VERSION "HNNBNNNYNNNNNNNNNNNNNNNNNNNNNNNNNNNNNNNNNN/4/%%%/4/'%**4NNN///"

NS_ :

BS_:

BU_: BAP_Tester BCM1 Gateway Gateway_PAG Klima_MSB Lift_VA VAS_L VAS_R

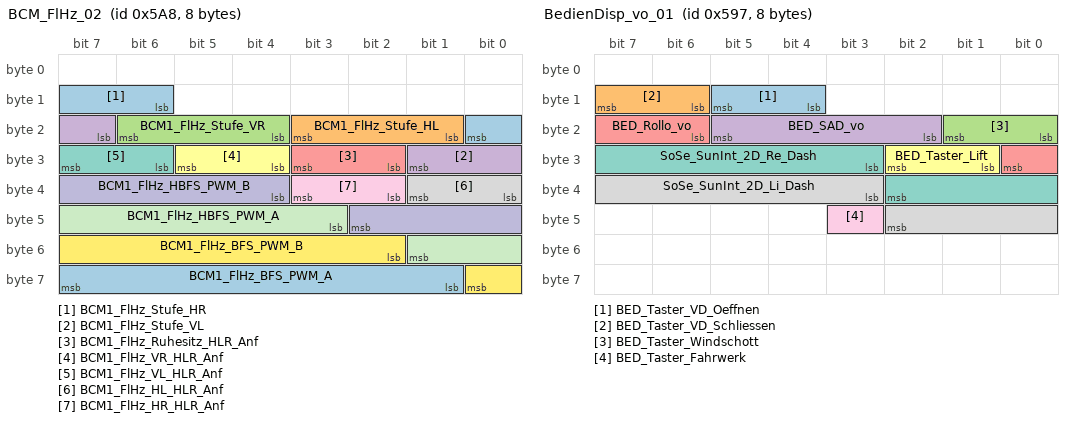
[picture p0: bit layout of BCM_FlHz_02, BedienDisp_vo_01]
BO_ 1448 BCM_FlHz_02: 8 BCM1
 SG_ BCM1_FlHz_Stufe_HR : 14|3@1+ (1.0,0.0) [0.0|7] ""  Gateway,Gateway_PAG,Klima_MSB
 SG_ BCM1_FlHz_Stufe_HL : 17|3@1+ (1.0,0.0) [0.0|7] ""  Gateway,Gateway_PAG,Klima_MSB
 SG_ BCM1_FlHz_Stufe_VR : 20|3@1+ (1.0,0.0) [0.0|7] ""  Gateway,Gateway_PAG,Klima_MSB
 SG_ BCM1_FlHz_Stufe_VL : 23|3@1+ (1.0,0.0) [0.0|7] ""  Gateway,Gateway_PAG,Klima_MSB
 SG_ BCM1_FlHz_Ruhesitz_HLR_Anf : 26|2@1+ (1.0,0.0) [0.0|3] ""  Gateway,Gateway_PAG
 SG_ BCM1_FlHz_VR_HLR_Anf : 28|2@1+ (1.0,0.0) [0.0|3] ""  Gateway,Gateway_PAG
 SG_ BCM1_FlHz_VL_HLR_Anf : 30|2@1+ (1.0,0.0) [0.0|3] ""  Gateway,Gateway_PAG
 SG_ BCM1_FlHz_HL_HLR_Anf : 32|2@1+ (1.0,0.0) [0.0|3] ""  Gateway,Gateway_PAG
 SG_ BCM1_FlHz_HR_HLR_Anf : 34|2@1+ (1.0,0.0) [0.0|3] ""  Gateway,Gateway_PAG
 SG_ BCM1_FlHz_HBFS_PWM_B : 36|7@1+ (1,0) [0|100] "Unit_PerCent"  Gateway,Gateway_PAG
 SG_ BCM1_FlHz_HBFS_PWM_A : 43|7@1+ (1,0) [0|100] "Unit_PerCent"  Gateway,Gateway_PAG
 SG_ BCM1_FlHz_BFS_PWM_B : 50|7@1+ (1,0) [0|100] "Unit_PerCent"  Gateway,Gateway_PAG
 SG_ BCM1_FlHz_BFS_PWM_A : 57|7@1+ (1,0) [0|100] "Unit_PerCent"  Gateway,Gateway_PAG

BO_ 961 BCM_Taster_01: 8 BCM1
 SG_ Heckrollo_2_Taster : 10|2@1+ (1.0,0.0) [0.0|3] ""  Gateway,Gateway_PAG
 SG_ APS_Taster : 12|2@1+ (1.0,0.0) [0.0|3] ""  Gateway,Gateway_PAG
 SG_ PLA_Taster : 14|2@1+ (1.0,0.0) [0.0|3] ""  Gateway,Gateway_PAG
 SG_ ESP_Off_Taster : 16|2@1+ (1.0,0.0) [0.0|3] ""  Gateway,Gateway_PAG
 SG_ HDC_Taster : 18|2@1+ (1.0,0.0) [0.0|3] ""  Gateway,Gateway_PAG
 SG_ AVH_Taster : 20|2@1+ (1.0,0.0) [0.0|3] ""  Gateway,Gateway_PAG
 SG_ Display_Taster : 22|2@1+ (1.0,0.0) [0.0|3] ""  Gateway,Gateway_PAG
 SG_ Heckrollo_Taster : 24|2@1+ (1.0,0.0) [0.0|3] ""  Gateway,Gateway_PAG
 SG_ Spoiler_Taster : 26|2@1+ (1.0,0.0) [0.0|3] ""  Gateway,Gateway_PAG
 SG_ Drivesel_1_Taster : 28|2@1+ (1.0,0.0) [0.0|3] ""  Gateway,Gateway_PAG
 SG_ Drivesel_2_Taster : 30|2@1+ (1.0,0.0) [0.0|3] ""  Gateway,Gateway_PAG
 SG_ Sideview_Taster : 32|2@1+ (1.0,0.0) [0.0|3] ""  Gateway,Gateway_PAG
 SG_ LIM_PAO_Alivesignal : 34|4@1+ (1,0) [0|15] ""  Gateway,Gateway_PAG
 SG_ LKS_Taster : 38|2@1+ (1.0,0.0) [0.0|3] ""  Gateway,Gateway_PAG
 SG_ SWA_Taster : 40|2@1+ (1.0,0.0) [0.0|3] ""  Gateway,Gateway_PAG
 SG_ LIM_bCall_Taster : 42|1@1+ (1.0,0.0) [0.0|1] ""  Gateway,Gateway_PAG
 SG_ eCall_Taste : 43|2@1+ (1.0,0.0) [0.0|3] ""  Gateway,Gateway_PAG
 SG_ PLA_Taster_Fehler_Roh : 45|1@1+ (1.0,0.0) [0.0|1] ""  Gateway,Gateway_PAG
 SG_ LIM_PAO_ON_Status : 46|2@1+ (1.0,0.0) [0.0|3] ""  Gateway,Gateway_PAG
 SG_ LIM_PAO_OFF_Status : 48|2@1+ (1.0,0.0) [0.0|3] ""  Gateway,Gateway_PAG
 SG_ LIM_PAO_Schriftzug_Status : 50|2@1+ (1.0,0.0) [0.0|3] ""  Gateway,Gateway_PAG
 SG_ Spoiler_LED_Status : 52|2@1+ (1.0,0.0) [0.0|3] ""  Gateway,Gateway_PAG
 SG_ AVH_LED_Status : 54|2@1+ (1.0,0.0) [0.0|3] ""  Gateway,Gateway_PAG
 SG_ HDC_LED_Status : 56|2@1+ (1.0,0.0) [0.0|3] ""  Gateway,Gateway_PAG
 SG_ PLA_LED_Status : 60|2@1+ (1.0,0.0) [0.0|3] ""  Gateway,Gateway_PAG
 SG_ APS_LED_Status : 62|2@1+ (1.0,0.0) [0.0|3] ""  Gateway,Gateway_PAG

BO_ 1432 BCM_Taster_02: 8 BCM1
 SG_ BCM_BFS_Fernsteuerung_aktiv : 28|1@1+ (1.0,0.0) [0.0|1] ""  Gateway,Gateway_PAG
 SG_ BCM_Soundklappe_Taster : 29|1@1+ (1.0,0.0) [0.0|1] ""  Gateway,Gateway_PAG
 SG_ E_Sound_LED_Status : 30|2@1+ (1.0,0.0) [0.0|3] ""  Gateway,Gateway_PAG
 SG_ Pilot_Taster : 32|2@1+ (1.0,0.0) [0.0|3] ""  Gateway,Gateway_PAG
 SG_ BCM1_eSound_Taster : 34|2@1+ (1.0,0.0) [0.0|3] ""  Gateway,Gateway_PAG
 SG_ BCM_FS_Programmwippe : 37|1@1+ (1.0,0.0) [0.0|1] ""  Gateway,Gateway_PAG
 SG_ BCM_BFS_Programmwippe : 38|1@1+ (1.0,0.0) [0.0|1] ""  Gateway,Gateway_PAG
 SG_ BCM_FS_Multif_Taster : 39|1@1+ (1.0,0.0) [0.0|1] ""  Gateway,Gateway_PAG
 SG_ BCM_BFS_Multif_Taster : 40|1@1+ (1.0,0.0) [0.0|1] ""  Gateway,Gateway_PAG
 SG_ BCM_FS_Massage_Taster : 41|1@1+ (1.0,0.0) [0.0|1] ""  Gateway,Gateway_PAG
 SG_ BCM_BFS_Massage_Taster : 42|1@1+ (1.0,0.0) [0.0|1] ""  Gateway,Gateway_PAG
 SG_ BCM_FS_Pneumatik_Verstellung : 43|1@1+ (1.0,0.0) [0.0|1] ""  Gateway,Gateway_PAG
 SG_ BCM_BFS_Pneumatik_Verstellung : 44|1@1+ (1.0,0.0) [0.0|1] ""  Gateway,Gateway_PAG
 SG_ LIM_Rear_Mode : 45|1@1+ (1.0,0.0) [0.0|1] ""  Gateway,Gateway_PAG
 SG_ BCM1_NR_Ride_Height_Up_Taster : 46|2@1+ (1.0,0.0) [0.0|3] ""  Gateway,Gateway_PAG
 SG_ BCM1_NR_Ride_Height_Down_Taster : 48|2@1+ (1.0,0.0) [0.0|3] ""  Gateway,Gateway_PAG
 SG_ LIM_S_Rollo_vo : 50|3@1+ (1.0,0.0) [0.0|7] ""  Gateway,Gateway_PAG
 SG_ LIM_S_Rollo_hi : 53|3@1+ (1.0,0.0) [0.0|7] ""  Gateway,Gateway_PAG
 SG_ LIM_S_SAD_Vo : 56|4@1+ (1.0,0.0) [0.0|15] ""  Gateway,Gateway_PAG
 SG_ LIM_S_SAD_hi : 60|4@1+ (1.0,0.0) [0.0|15] ""  Gateway,Gateway_PAG

BO_ 1431 BedienDisp_vo_01: 8 Gateway
 SG_ BED_Taster_VD_Oeffnen : 12|2@1+ (1.0,0.0) [0.0|3] ""  Vector__XXX
 SG_ BED_Taster_VD_Schliessen : 14|2@1+ (1.0,0.0) [0.0|3] ""  Vector__XXX
 SG_ BED_Taster_Windschott : 16|2@1+ (1.0,0.0) [0.0|3] ""  Vector__XXX
 SG_ BED_SAD_vo : 18|4@1+ (1.0,0.0) [0.0|15] ""  Vector__XXX
 SG_ BED_Rollo_vo : 22|3@1+ (1.0,0.0) [0.0|7] ""  Vector__XXX
 SG_ BED_Taster_Lift : 25|2@1+ (1.0,0.0) [0.0|3] ""  Lift_VA
 SG_ SoSe_SunInt_2D_Re_Dash : 27|8@1+ (5,0) [0|1200] "Unit_WattPerMeterSquar"  BCM1
 SG_ SoSe_SunInt_2D_Li_Dash : 35|8@1+ (5,0) [0|1200] "Unit_WattPerMeterSquar"  BCM1
 SG_ BED_Taster_Fahrwerk : 43|1@1+ (1.0,0.0) [0.0|1] ""  Vector__XXX

BO_ 870 Blinkmodi_02: 8 Gateway
 SG_ BM_ZV_auf : 12|1@1+ (1.0,0.0) [0.0|1] ""  BCM1
 SG_ BM_ZV_zu : 13|1@1+ (1.0,0.0) [0.0|1] ""  BCM1
 SG_ BM_DWA_ein : 14|1@1+ (1.0,0.0) [0.0|1] ""  BCM1
 SG_ BM_DWA_Alarm : 15|1@1+ (1.0,0.0) [0.0|1] ""  BCM1
 SG_ BM_Crash : 16|1@1+ (1.0,0.0) [0.0|1] ""  BCM1
 SG_ BM_Panik : 17|1@1+ (1.0,0.0) [0.0|1] ""  BCM1
 SG_ BM_Not_Bremsung : 18|1@1+ (1.0,0.0) [0.0|1] ""  BCM1
 SG_ BM_GDO : 19|1@1+ (1.0,0.0) [0.0|1] ""  BCM1
 SG_ BM_Warnblinken : 20|1@1+ (1.0,0.0) [0.0|1] ""  BCM1,VAS_L,VAS_R
 SG_ BM_Taxi_Notalarm : 21|1@1+ (1.0,0.0) [0.0|1] ""  BCM1
 SG_ BM_Telematik : 22|1@1+ (1.0,0.0) [0.0|1] ""  BCM1
 SG_ BM_links : 23|1@1+ (1.0,0.0) [0.0|1] ""  BCM1,VAS_L,VAS_R
 SG_ BM_rechts : 24|1@1+ (1.0,0.0) [0.0|1] ""  BCM1,VAS_L,VAS_R
 SG_ Blinken_li_Fzg_Takt : 25|1@1+ (1.0,0.0) [0.0|1] ""  BCM1,VAS_L,VAS_R
 SG_ Blinken_re_Fzg_Takt : 26|1@1+ (1.0,0.0) [0.0|1] ""  BCM1,VAS_L,VAS_R
 SG_ Blinken_li_Kombi_Takt : 27|1@1+ (1.0,0.0) [0.0|1] ""  Vector__XXX
 SG_ Blinken_re_Kombi_Takt : 28|1@1+ (1.0,0.0) [0.0|1] ""  Vector__XXX
 SG_ BM_NBA_n_codiert_n_aktiv : 29|1@1+ (1.0,0.0) [0.0|1] ""  Vector__XXX
 SG_ BM_NBA_Status : 30|2@1+ (1.0,0.0) [0.0|3] ""  Vector__XXX
 SG_ BM_WBT_Beleuchtung : 32|1@1+ (1.0,0.0) [0.0|1] ""  BCM1
 SG_ BM_HD_Oeffnung_angelernt : 33|1@1+ (1.0,0.0) [0.0|1] ""  BCM1
 SG_ BM_Autobahn : 34|1@1+ (1.0,0.0) [0.0|1] ""  BCM1
 SG_ BM_Rollenmodus_Blinken : 35|1@1+ (1.0,0.0) [0.0|1] ""  BCM1
 SG_ BM_Recas : 36|1@1+ (1.0,0.0) [0.0|1] ""  BCM1
 SG_ BM_Wischblinken : 37|1@1+ (1.0,0.0) [0.0|1] ""  BCM1
 SG_ BM_Telematik_Abbruchgrund : 38|6@1+ (1.0,0.0) [0.0|63] ""  Vector__XXX
 SG_ BM_PiloPa : 44|1@1+ (1.0,0.0) [0.0|1] ""  BCM1
 SG_ DWA_Alarmquelle : 59|5@1+ (1.0,0.0) [0.0|31] ""  Vector__XXX

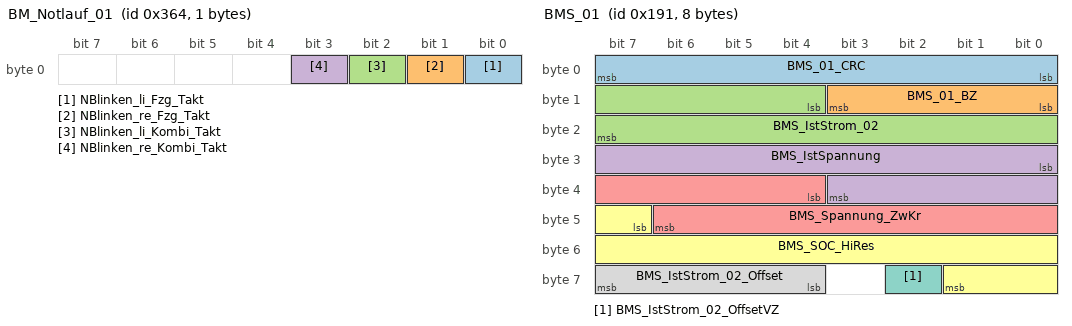
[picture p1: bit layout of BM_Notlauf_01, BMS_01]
BO_ 868 BM_Notlauf_01: 1 BCM1
 SG_ NBlinken_li_Fzg_Takt : 0|1@1+ (1.0,0.0) [0.0|1] ""  Gateway,Gateway_PAG
 SG_ NBlinken_re_Fzg_Takt : 1|1@1+ (1.0,0.0) [0.0|1] ""  Gateway,Gateway_PAG
 SG_ NBlinken_li_Kombi_Takt : 2|1@1+ (1.0,0.0) [0.0|1] ""  Gateway,Gateway_PAG
 SG_ NBlinken_re_Kombi_Takt : 3|1@1+ (1.0,0.0) [0.0|1] ""  Gateway,Gateway_PAG

BO_ 401 BMS_01: 8 Gateway
 SG_ BMS_01_CRC : 0|8@1+ (1,0) [0|255] ""  Vector__XXX
 SG_ BMS_01_BZ : 8|4@1+ (1,0) [0|15] ""  Vector__XXX
 SG_ BMS_IstStrom_02 : 12|12@1+ (1,-2047) [-2047|2046] "Unit_Amper"  Vector__XXX
 SG_ BMS_IstSpannung : 24|12@1+ (0.25,0) [0.00|1023.25] "Unit_Volt"  Vector__XXX
 SG_ BMS_Spannung_ZwKr : 36|11@1+ (0.5,0) [0.0|1022.5] "Unit_Volt"  Vector__XXX
 SG_ BMS_SOC_HiRes : 47|11@1+ (0.05,0) [0.00|100.00] "Unit_PerCent"  Klima_MSB
 SG_ BMS_IstStrom_02_OffsetVZ : 58|1@1+ (1.0,0.0) [0.0|1] ""  Vector__XXX
 SG_ BMS_IstStrom_02_Offset : 60|4@1+ (0.0625,0) [0.0000|0.9375] "Unit_Amper"  Vector__XXX

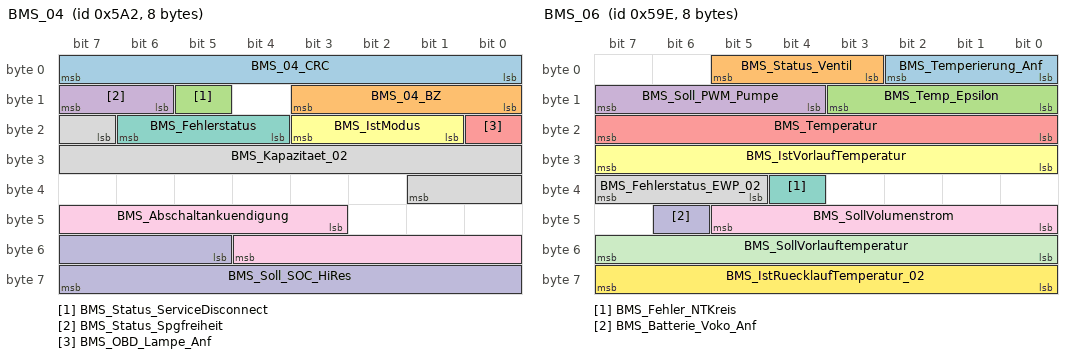
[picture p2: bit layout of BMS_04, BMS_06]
BO_ 1442 BMS_04: 8 Gateway
 SG_ BMS_04_CRC : 0|8@1+ (1,0) [0|255] ""  Vector__XXX
 SG_ BMS_04_BZ : 8|4@1+ (1,0) [0|15] ""  Vector__XXX
 SG_ BMS_Status_ServiceDisconnect : 13|1@1+ (1.0,0.0) [0.0|1] ""  Vector__XXX
 SG_ BMS_Status_Spgfreiheit : 14|2@1+ (1.0,0.0) [0.0|3] ""  Vector__XXX
 SG_ BMS_OBD_Lampe_Anf : 16|1@1+ (1.0,0.0) [0.0|1] ""  Vector__XXX
 SG_ BMS_IstModus : 17|3@1+ (1.0,0.0) [0.0|7] ""  Klima_MSB
 SG_ BMS_Fehlerstatus : 20|3@1+ (1.0,0.0) [0.0|7] ""  Vector__XXX
 SG_ BMS_Kapazitaet_02 : 23|11@1+ (0.2,0) [0.0|409.2] "Unit_AmperHour"  Vector__XXX
 SG_ BMS_Abschaltankuendigung : 43|10@1+ (0.5,0) [0.0|510.5] "Unit_Secon"  Vector__XXX
 SG_ BMS_Soll_SOC_HiRes : 53|11@1+ (0.05,0) [0.00|100.00] "Unit_PerCent"  Vector__XXX

BO_ 1438 BMS_06: 8 Gateway
 SG_ BMS_Temperierung_Anf : 0|3@1+ (1.0,0.0) [0.0|7] ""  Vector__XXX
 SG_ BMS_Status_Ventil : 3|3@1+ (1.0,0.0) [0.0|7] ""  Vector__XXX
 SG_ BMS_Temp_Epsilon : 8|4@1+ (1,-15) [-15|0] "Unit_DegreCelsi"  Vector__XXX
 SG_ BMS_Soll_PWM_Pumpe : 12|4@1+ (10,0) [0|100] "Unit_PerCent"  Vector__XXX
 SG_ BMS_Temperatur : 16|8@1+ (0.5,-40) [-40.0|86.5] "Unit_DegreCelsi"  Klima_MSB
 SG_ BMS_IstVorlaufTemperatur : 24|8@1+ (0.5,-40) [-40.0|86.5] "Unit_DegreCelsi"  Vector__XXX
 SG_ BMS_Fehler_NTKreis : 36|1@1+ (1.0,0.0) [0.0|1] ""  Vector__XXX
 SG_ BMS_Fehlerstatus_EWP_02 : 37|3@1+ (1.0,0.0) [0.0|7] ""  Vector__XXX
 SG_ BMS_SollVolumenstrom : 40|6@1+ (1,0) [0|61] "Unit_LiterPerMinut"  Vector__XXX
 SG_ BMS_Batterie_Voko_Anf : 46|1@1+ (1.0,0.0) [0.0|1] ""  Vector__XXX
 SG_ BMS_SollVorlauftemperatur : 48|8@1+ (0.5,-40) [-40.0|86.5] "Unit_DegreCelsi"  Vector__XXX
 SG_ BMS_IstRuecklaufTemperatur_02 : 56|8@1+ (0.5,-40) [-40.0|86.5] "Unit_DegreCelsi"  Vector__XXX

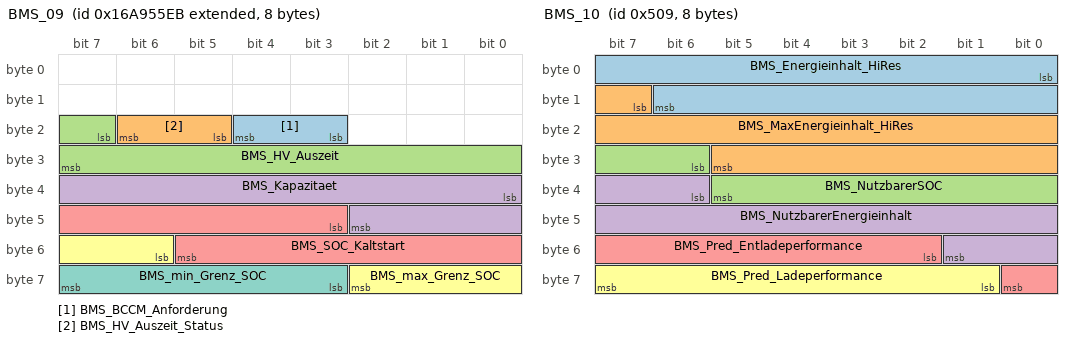
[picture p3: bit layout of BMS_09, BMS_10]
BO_ 2527679979 BMS_09: 8 Gateway
 SG_ BMS_BCCM_Anforderung : 19|2@1+ (1.0,0.0) [0.0|3] ""  Vector__XXX
 SG_ BMS_HV_Auszeit_Status : 21|2@1+ (1.0,0.0) [0.0|3] ""  Vector__XXX
 SG_ BMS_HV_Auszeit : 23|9@1+ (4,0) [0|2036] "Unit_Minut"  Vector__XXX
 SG_ BMS_Kapazitaet : 32|11@1+ (0.1,0) [0.0|204.6] "Unit_AmperHour"  Vector__XXX
 SG_ BMS_SOC_Kaltstart : 43|11@1+ (0.05,0) [0.00|100.00] "Unit_PerCent"  Klima_MSB
 SG_ BMS_max_Grenz_SOC : 54|5@1+ (1,70) [70|100] "Unit_PerCent"  Vector__XXX
 SG_ BMS_min_Grenz_SOC : 59|5@1+ (1,0) [0|30] "Unit_PerCent"  Vector__XXX

BO_ 1289 BMS_10: 8 Gateway
 SG_ BMS_Energieinhalt_HiRes : 0|15@1+ (4,0) [0|131060] "Unit_WattHour"  Vector__XXX
 SG_ BMS_MaxEnergieinhalt_HiRes : 15|15@1+ (4,0) [0|131060] "Unit_WattHour"  Vector__XXX
 SG_ BMS_NutzbarerSOC : 30|8@1+ (0.5,0) [0.0|100.0] "Unit_PerCent"  Klima_MSB
 SG_ BMS_NutzbarerEnergieinhalt : 38|12@1+ (25,0) [0|102325] "Unit_WattHour"  Vector__XXX
 SG_ BMS_Pred_Entladeperformance : 50|7@1+ (1,0) [0|100] "Unit_PerCent"  Vector__XXX
 SG_ BMS_Pred_Ladeperformance : 57|7@1+ (1,0) [0|100] "Unit_PerCent"  Vector__XXX

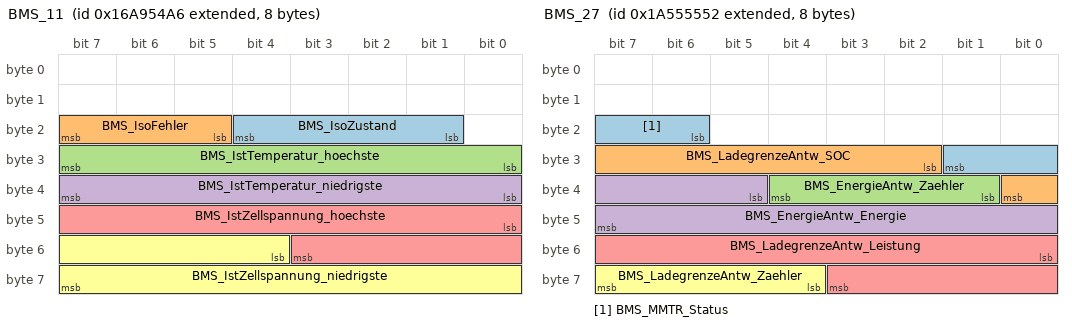
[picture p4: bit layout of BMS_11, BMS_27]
BO_ 2527679654 BMS_11: 8 Gateway
 SG_ BMS_IsoZustand : 17|4@1+ (1.0,0.0) [0.0|15] ""  Vector__XXX
 SG_ BMS_IsoFehler : 21|3@1+ (1.0,0.0) [0.0|7] ""  Vector__XXX
 SG_ BMS_IstTemperatur_hoechste : 24|8@1+ (0.5,-40) [-40.0|86.0] "Unit_DegreCelsi"  Klima_MSB
 SG_ BMS_IstTemperatur_niedrigste : 32|8@1+ (0.5,-40) [-40.0|86.0] "Unit_DegreCelsi"  Klima_MSB
 SG_ BMS_IstZellspannung_hoechste : 40|12@1+ (1,1000) [1000|5091] "Unit_MilliVolt"  Vector__XXX
 SG_ BMS_IstZellspannung_niedrigste : 52|12@1+ (1,1000) [1000|5091] "Unit_MilliVolt"  Vector__XXX

BO_ 2589283666 BMS_27: 8 Gateway_PAG
 SG_ BMS_MMTR_Status : 22|4@1+ (1.0,0.0) [0.0|15] ""  Klima_MSB
 SG_ BMS_LadegrenzeAntw_SOC : 26|7@1+ (1,0) [0|100] "Unit_PerCent"  Vector__XXX
 SG_ BMS_EnergieAntw_Zaehler : 33|4@1+ (1,0) [0|13] "Unit_None"  Vector__XXX
 SG_ BMS_EnergieAntw_Energie : 37|11@1+ (250,0) [0|511250] "Unit_WattHour"  Vector__XXX
 SG_ BMS_LadegrenzeAntw_Leistung : 48|12@1+ (200,0) [0|818600] "Unit_Watt"  Vector__XXX
 SG_ BMS_LadegrenzeAntw_Zaehler : 60|4@1+ (1,0) [0|13] "Unit_None"  Vector__XXX

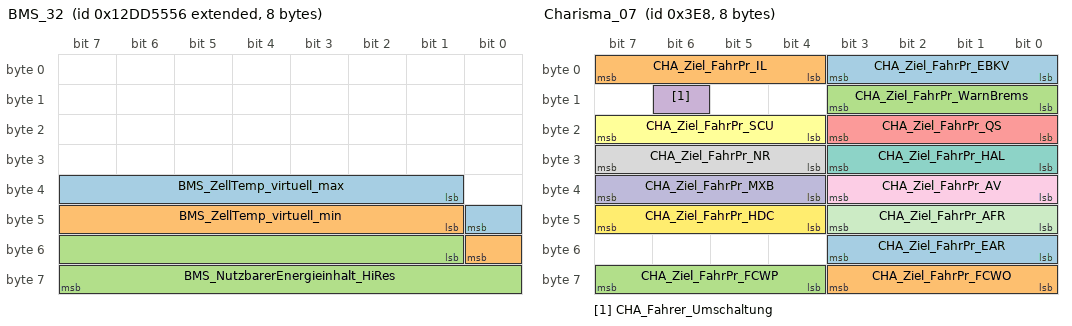
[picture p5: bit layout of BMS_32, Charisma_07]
BO_ 2463978838 BMS_32: 8 Gateway
 SG_ BMS_ZellTemp_virtuell_max : 33|8@1+ (0.5,-40) [-40.0|86.0] "Unit_DegreCelsi"  Klima_MSB
 SG_ BMS_ZellTemp_virtuell_min : 41|8@1+ (0.5,-40) [-40.0|86.0] "Unit_DegreCelsi"  Klima_MSB
 SG_ BMS_NutzbarerEnergieinhalt_HiRes : 49|15@1+ (4,-4) [0|131056] "Unit_WattHour"  Vector__XXX

BO_ 2617128448 CCP_Klima_CRO_01: 8 Vector__XXX
 SG_ CCP_Klima_CRO_01_Data : 0|64@1+ (1,0) [0|1] ""  BCM1,Klima_MSB

BO_ 2617128449 CCP_Klima_DTO_01: 8 BCM1
 SG_ CCP_Klima_DTO_01_Data : 0|64@1+ (1,0) [0|1] ""  Vector__XXX

BO_ 2617167360 CCP_Lift_VA_CRO_01: 8 Vector__XXX
 SG_ CCP_Lift_VA_CRO_01_Data : 0|64@1+ (1.0,0.0) [0.0|18446744073709551615] ""  Lift_VA

BO_ 2617167361 CCP_Lift_VA_DTO_01: 8 Lift_VA
 SG_ CCP_Lift_VA_DTO_01_Data : 0|64@1+ (1.0,0.0) [0.0|18446744073709551615] ""  Vector__XXX

BO_ 901 Charisma_01: 8 Gateway
 SG_ CHA_Ziel_FahrPr_AGA : 0|4@1+ (1.0,0.0) [0.0|15] ""  Vector__XXX
 SG_ CHA_Ziel_FahrPr_ESP : 4|4@1+ (1.0,0.0) [0.0|15] ""  Vector__XXX
 SG_ CHA_Ziel_FahrPr_Freilauf : 8|4@1+ (1.0,0.0) [0.0|15] ""  Vector__XXX
 SG_ CHA_Fahrer_Umschaltung : 14|1@1+ (1.0,0.0) [0.0|1] ""  Vector__XXX
 SG_ CHA_Fahrer_Umschaltung_BMA : 15|1@1+ (1.0,0.0) [0.0|1] ""  Vector__XXX
 SG_ CHA_Ziel_FahrPr_MO : 16|4@1+ (1.0,0.0) [0.0|15] ""  Vector__XXX
 SG_ CHA_Ziel_FahrPr_GE : 20|4@1+ (1.0,0.0) [0.0|15] ""  Vector__XXX
 SG_ CHA_Ziel_FahrPr_ALR : 24|4@1+ (1.0,0.0) [0.0|15] ""  Vector__XXX
 SG_ CHA_Ziel_FahrPr_MO_BZS : 28|4@1+ (1.0,0.0) [0.0|15] ""  BCM1
 SG_ CHA_Ziel_FahrPr_DR : 32|4@1+ (1.0,0.0) [0.0|15] ""  Vector__XXX
 SG_ CHA_Ziel_FahrPr_VAQ : 36|4@1+ (1.0,0.0) [0.0|15] ""  Vector__XXX
 SG_ CHA_Ziel_FahrPr_AFS : 40|4@1+ (1.0,0.0) [0.0|15] ""  BCM1
 SG_ CHA_Ziel_FahrPr_PreCrash : 44|4@1+ (1.0,0.0) [0.0|15] ""  Vector__XXX
 SG_ CHA_Ziel_FahrPr_EPS : 48|4@1+ (1.0,0.0) [0.0|15] ""  Vector__XXX
 SG_ CHA_Ziel_FahrPr_ACC : 52|4@1+ (1.0,0.0) [0.0|15] ""  Vector__XXX
 SG_ CHA_Ziel_FahrPr_SAK : 56|4@1+ (1.0,0.0) [0.0|15] ""  Vector__XXX
 SG_ CHA_Ziel_FahrPr_MO_StSt : 60|4@1+ (1.0,0.0) [0.0|15] ""  Vector__XXX

BO_ 902 Charisma_03: 8 Gateway
 SG_ CHA_Drive_Select1_LED : 10|2@1+ (1.0,0.0) [0.0|3] ""  BCM1
 SG_ CHA_Eco_Charisma_LED : 12|2@1+ (1.0,0.0) [0.0|3] ""  BCM1
 SG_ CHA_Fahrer_Umschaltung : 14|1@1+ (1.0,0.0) [0.0|1] ""  BCM1,Klima_MSB
 SG_ CHA_EV_LED : 15|1@1+ (1.0,0.0) [0.0|1] ""  BCM1
 SG_ CHA_Ziel_FahrPr_AMB : 16|4@1+ (1.0,0.0) [0.0|15] ""  BCM1
 SG_ CHA_Ziel_FahrPr_IVB : 20|4@1+ (1.0,0.0) [0.0|15] ""  Vector__XXX
 SG_ CHA_Kombi_Texte : 24|4@1+ (1.0,0.0) [0.0|15] ""  Vector__XXX
 SG_ CHA_Ziel_FahrPr_KL : 28|4@1+ (1.0,0.0) [0.0|15] ""  BCM1,Klima_MSB
 SG_ CHA_Ziel_FahrPr_HSP : 32|4@1+ (1.0,0.0) [0.0|15] ""  Vector__XXX
 SG_ CHA_Drehschalter_Istmodus : 36|4@1+ (1.0,0.0) [0.0|15] ""  BCM1
 SG_ CHA_Ziel_FahrPr_RWB : 40|4@1+ (1.0,0.0) [0.0|15] ""  Vector__XXX
 SG_ CHA_Ziel_FahrPr_03_01 : 44|4@1+ (1.0,0.0) [0.0|15] ""  Vector__XXX
 SG_ CHA_Ziel_FahrPr_03_02 : 48|4@1+ (1.0,0.0) [0.0|15] ""  Vector__XXX
 SG_ CHA_Current_Mode : 52|4@1+ (1.0,0.0) [0.0|15] ""  Vector__XXX
 SG_ CHA_Charge_LED : 57|1@1+ (1.0,0.0) [0.0|1] ""  Vector__XXX
 SG_ CHA_Offroad_LED : 58|2@1+ (1.0,0.0) [0.0|3] ""  Vector__XXX
 SG_ CHA_Kombi_Texte_02 : 60|4@1+ (1.0,0.0) [0.0|15] ""  Vector__XXX

BO_ 1000 Charisma_07: 8 Gateway
 SG_ CHA_Ziel_FahrPr_EBKV : 0|4@1+ (1.0,0.0) [0.0|15] ""  Vector__XXX
 SG_ CHA_Ziel_FahrPr_IL : 4|4@1+ (1.0,0.0) [0.0|15] ""  Vector__XXX
 SG_ CHA_Ziel_FahrPr_WarnBrems : 8|4@1+ (1.0,0.0) [0.0|15] ""  Vector__XXX
 SG_ CHA_Fahrer_Umschaltung : 14|1@1+ (1.0,0.0) [0.0|1] ""  Vector__XXX
 SG_ CHA_Ziel_FahrPr_QS : 16|4@1+ (1.0,0.0) [0.0|15] ""  Vector__XXX
 SG_ CHA_Ziel_FahrPr_SCU : 20|4@1+ (1.0,0.0) [0.0|15] ""  Vector__XXX
 SG_ CHA_Ziel_FahrPr_HAL : 24|4@1+ (1.0,0.0) [0.0|15] ""  Vector__XXX
 SG_ CHA_Ziel_FahrPr_NR : 28|4@1+ (1.0,0.0) [0.0|15] ""  Lift_VA
 SG_ CHA_Ziel_FahrPr_AV : 32|4@1+ (1.0,0.0) [0.0|15] ""  BCM1
 SG_ CHA_Ziel_FahrPr_MXB : 36|4@1+ (1.0,0.0) [0.0|15] ""  Vector__XXX
 SG_ CHA_Ziel_FahrPr_AFR : 40|4@1+ (1.0,0.0) [0.0|15] ""  Vector__XXX
 SG_ CHA_Ziel_FahrPr_HDC : 44|4@1+ (1.0,0.0) [0.0|15] ""  Vector__XXX
 SG_ CHA_Ziel_FahrPr_EAR : 48|4@1+ (1.0,0.0) [0.0|15] ""  Vector__XXX
 SG_ CHA_Ziel_FahrPr_FCWO : 56|4@1+ (1.0,0.0) [0.0|15] ""  Vector__XXX
 SG_ CHA_Ziel_FahrPr_FCWP : 60|4@1+ (1.0,0.0) [0.0|15] ""  Vector__XXX

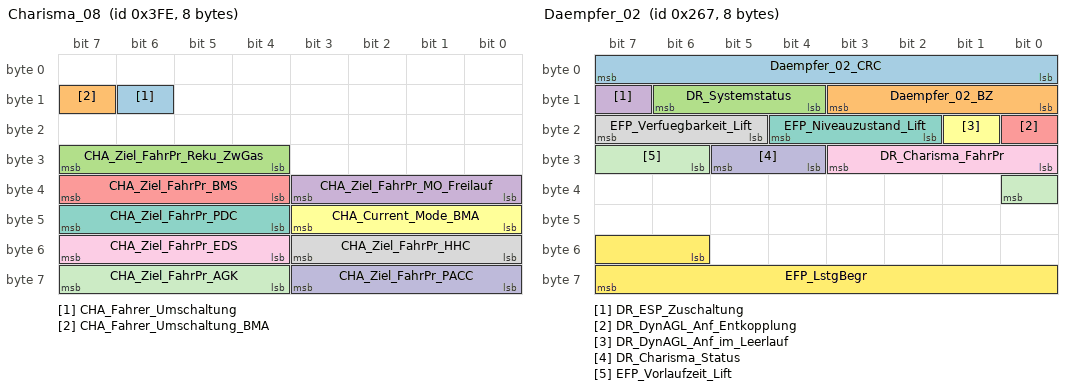
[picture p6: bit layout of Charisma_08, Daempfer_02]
BO_ 1022 Charisma_08: 8 Gateway
 SG_ CHA_Fahrer_Umschaltung : 14|1@1+ (1.0,0.0) [0.0|1] ""  Vector__XXX
 SG_ CHA_Fahrer_Umschaltung_BMA : 15|1@1+ (1.0,0.0) [0.0|1] ""  Vector__XXX
 SG_ CHA_Ziel_FahrPr_Reku_ZwGas : 28|4@1+ (1.0,0.0) [0.0|15] ""  Vector__XXX
 SG_ CHA_Ziel_FahrPr_MO_Freilauf : 32|4@1+ (1.0,0.0) [0.0|15] ""  Vector__XXX
 SG_ CHA_Ziel_FahrPr_BMS : 36|4@1+ (1.0,0.0) [0.0|15] ""  Vector__XXX
 SG_ CHA_Current_Mode_BMA : 40|4@1+ (1.0,0.0) [0.0|15] ""  Vector__XXX
 SG_ CHA_Ziel_FahrPr_PDC : 44|4@1+ (1.0,0.0) [0.0|15] ""  BCM1
 SG_ CHA_Ziel_FahrPr_HHC : 48|4@1+ (1.0,0.0) [0.0|15] ""  Vector__XXX
 SG_ CHA_Ziel_FahrPr_EDS : 52|4@1+ (1.0,0.0) [0.0|15] ""  Vector__XXX
 SG_ CHA_Ziel_FahrPr_PACC : 56|4@1+ (1.0,0.0) [0.0|15] ""  Vector__XXX
 SG_ CHA_Ziel_FahrPr_AGK : 60|4@1+ (1.0,0.0) [0.0|15] ""  Vector__XXX

BO_ 615 Daempfer_02: 8 Gateway
 SG_ Daempfer_02_CRC : 0|8@1+ (1,0) [0|255] ""  Vector__XXX
 SG_ Daempfer_02_BZ : 8|4@1+ (1,0) [0|15] ""  Vector__XXX
 SG_ DR_Systemstatus : 12|3@1+ (1.0,0.0) [0.0|7] ""  Vector__XXX
 SG_ DR_ESP_Zuschaltung : 15|1@1+ (1.0,0.0) [0.0|1] ""  Vector__XXX
 SG_ DR_DynAGL_Anf_Entkopplung : 16|1@1+ (1.0,0.0) [0.0|1] ""  Vector__XXX
 SG_ DR_DynAGL_Anf_im_Leerlauf : 17|1@1+ (1.0,0.0) [0.0|1] ""  Vector__XXX
 SG_ EFP_Niveauzustand_Lift : 18|3@1+ (1.0,0.0) [0.0|7] ""  Lift_VA
 SG_ EFP_Verfuegbarkeit_Lift : 21|3@1+ (1.0,0.0) [0.0|7] ""  Lift_VA
 SG_ DR_Charisma_FahrPr : 24|4@1+ (1.0,0.0) [0.0|15] ""  Vector__XXX
 SG_ DR_Charisma_Status : 28|2@1+ (1.0,0.0) [0.0|3] ""  Vector__XXX
 SG_ EFP_Vorlaufzeit_Lift : 30|3@1+ (1,3) [3|8] "Unit_Secon"  Lift_VA
 SG_ EFP_LstgBegr : 54|10@1+ (1,0) [0|1000] "Unit_KiloWatt"  Vector__XXX

BO_ 2617012736 DEV_BCM1_Resp_00: 8 BCM1
 SG_ DEV_BCM1_Resp_00_Data : 0|64@1+ (1.0,0.0) [0.0|18446744073709551615] ""  Vector__XXX

BO_ 2617012991 DEV_BCM1_Resp_FF: 8 BCM1
 SG_ DEV_BCM1_Resp_FF_Data : 0|64@1+ (1.0,0.0) [0.0|18446744073709551615] ""  Vector__XXX

BO_ 2617037312 DEV_Klima_Fond_Tx_00: 8 BCM1
 SG_ DEV_Klima_Fond_Tx_00_Data : 0|64@1+ (1.0,0.0) [0.0|18446744073709551615] ""  Vector__XXX

BO_ 2617037567 DEV_Klima_Fond_Tx_FF: 8 BCM1
 SG_ DEV_Klima_Fond_Tx_FF_Data : 0|64@1+ (1.0,0.0) [0.0|18446744073709551615] ""  Vector__XXX

BO_ 2617127424 DEV_Klima_Tx_00: 8 BCM1
 SG_ DEV_Klima_Tx_00_Data : 0|64@1+ (1.0,0.0) [0.0|18446744073709551615] ""  Vector__XXX

BO_ 2617127679 DEV_Klima_Tx_FF: 8 BCM1
 SG_ DEV_Klima_Tx_FF_Data : 0|64@1+ (1.0,0.0) [0.0|18446744073709551615] ""  Vector__XXX

BO_ 2617166336 DEV_Lift_VA_Req_01: 8 Vector__XXX
 SG_ DEV_Lift_VA_Req_01_Data : 0|64@1+ (1.0,0.0) [0.0|18446744073709551615] ""  Lift_VA

BO_ 2617166337 DEV_Lift_VA_Resp_01: 8 Lift_VA
 SG_ DEV_Lift_VA_Resp_01_Data : 0|64@1+ (1.0,0.0) [0.0|18446744073709551615] ""  Vector__XXX

BO_ 2617166591 DEV_Lift_VA_Resp_FF: 8 Lift_VA
 SG_ DEV_Lift_VA_Resp_FF_Data : 0|64@1+ (1.0,0.0) [0.0|18446744073709551615] ""  Vector__XXX

BO_ 2617123584 DEV_VAS_L_Resp_00: 8 VAS_L
 SG_ DEV_VAS_L_Resp_00_Data : 0|64@1+ (1.0,0.0) [0.0|18446744073709551615] ""  Vector__XXX

BO_ 2617123839 DEV_VAS_L_Resp_FF: 8 VAS_L
 SG_ DEV_VAS_L_Resp_FF_Data : 0|64@1+ (1.0,0.0) [0.0|18446744073709551615] ""  Vector__XXX

BO_ 2617125632 DEV_VAS_R_Resp_00: 8 VAS_R
 SG_ DEV_VAS_R_Resp_00_Data : 0|64@1+ (1.0,0.0) [0.0|18446744073709551615] ""  Vector__XXX

BO_ 2617125887 DEV_VAS_R_Resp_FF: 8 VAS_R
 SG_ DEV_VAS_R_Resp_FF_Data : 0|64@1+ (1.0,0.0) [0.0|18446744073709551615] ""  Vector__XXX

BO_ 2549880614 DIA_AAU_Req: 8 Gateway
 SG_ DIA_AAU_Req_Data : 0|64@1+ (1.0,0.0) [0.0|18446744073709551615] ""  BCM1,Klima_MSB

BO_ 2550011686 DIA_AAU_Resp: 8 BCM1
 SG_ DIA_AAU_Resp_Data : 0|64@1+ (1.0,0.0) [0.0|18446744073709551615] ""  Gateway,Gateway_PAG

BO_ 2549880393 DIA_EVLS_Req: 8 Gateway
 SG_ DIA_EVLS_Req_Data : 0|64@1+ (1.0,0.0) [0.0|18446744073709551615] ""  BCM1

BO_ 2550011465 DIA_EVLS_Resp: 8 BCM1
 SG_ DIA_EVLS_Resp_Data : 0|64@1+ (1.0,0.0) [0.0|18446744073709551615] ""  Gateway,Gateway_PAG

BO_ 2549880347 DIA_Geblaese_Req: 8 Gateway
 SG_ DIA_Geblaese_Req_Data : 0|64@1+ (1.0,0.0) [0.0|18446744073709551615] ""  BCM1,Klima_MSB

BO_ 2550011419 DIA_Geblaese_Resp: 8 BCM1
 SG_ DIA_Geblaese_Resp_Data : 0|64@1+ (1.0,0.0) [0.0|18446744073709551615] ""  Gateway,Gateway_PAG

BO_ 2549880340 DIA_gLW_LM_L_Req: 8 Gateway
 SG_ DIA_gLW_LM_L_Req_Data : 0|64@1+ (1.0,0.0) [0.0|18446744073709551615] ""  BCM1

BO_ 2550011412 DIA_gLW_LM_L_Resp: 8 BCM1
 SG_ DIA_gLW_LM_L_Resp_Data : 0|64@1+ (1.0,0.0) [0.0|18446744073709551615] ""  Gateway,Gateway_PAG

BO_ 2549880341 DIA_gLW_LM_R_Req: 8 Gateway
 SG_ DIA_gLW_LM_R_Req_Data : 0|64@1+ (1.0,0.0) [0.0|18446744073709551615] ""  BCM1

BO_ 2550011413 DIA_gLW_LM_R_Resp: 8 BCM1
 SG_ DIA_gLW_LM_R_Resp_Data : 0|64@1+ (1.0,0.0) [0.0|18446744073709551615] ""  Gateway,Gateway_PAG

BO_ 2549880577 DIA_KBF_Req: 8 Gateway
 SG_ DIA_KBF_Req_Data : 0|64@1+ (1.0,0.0) [0.0|18446744073709551615] ""  BCM1,Klima_MSB

BO_ 2550011649 DIA_KBF_Resp: 8 BCM1
 SG_ DIA_KBF_Resp_Data : 0|64@1+ (1.0,0.0) [0.0|18446744073709551615] ""  Gateway,Gateway_PAG

BO_ 2549880639 DIA_KPV_Req: 8 Gateway
 SG_ DIA_KPV_Req_Data : 0|64@1+ (1.0,0.0) [0.0|18446744073709551615] ""  BCM1

BO_ 2550011711 DIA_KPV_Resp: 8 BCM1
 SG_ DIA_KPV_Resp_Data : 0|64@1+ (1.0,0.0) [0.0|18446744073709551615] ""  Gateway,Gateway_PAG

BO_ 2549880330 DIA_LED_LM_L_Req: 8 Gateway
 SG_ DIA_LED_LM_L_Req_Data : 0|64@1+ (1.0,0.0) [0.0|18446744073709551615] ""  BCM1

BO_ 2550011402 DIA_LED_LM_L_Resp: 8 BCM1
 SG_ DIA_LED_LM_L_Resp_Data : 0|64@1+ (1.0,0.0) [0.0|18446744073709551615] ""  Gateway,Gateway_PAG

BO_ 2549880331 DIA_LED_LM_R_Req: 8 Gateway
 SG_ DIA_LED_LM_R_Req_Data : 0|64@1+ (1.0,0.0) [0.0|18446744073709551615] ""  BCM1

BO_ 2550011403 DIA_LED_LM_R_Resp: 8 BCM1
 SG_ DIA_LED_LM_R_Resp_Data : 0|64@1+ (1.0,0.0) [0.0|18446744073709551615] ""  Gateway,Gateway_PAG

BO_ 2549880633 DIA_LIM_2_Req: 8 Gateway
 SG_ DIA_LIM_2_Req_Data : 0|64@1+ (1.0,0.0) [0.0|18446744073709551615] ""  BCM1

BO_ 2550011705 DIA_LIM_2_Resp: 8 BCM1
 SG_ DIA_LIM_2_Resp_Data : 0|64@1+ (1.0,0.0) [0.0|18446744073709551615] ""  Gateway,Gateway_PAG

BO_ 2549880350 DIA_LIM_Req: 8 Gateway
 SG_ DIA_LIM_Req_Data : 0|64@1+ (1.0,0.0) [0.0|18446744073709551615] ""  BCM1

BO_ 2550011422 DIA_LIM_Resp: 8 BCM1
 SG_ DIA_LIM_Resp_Data : 0|64@1+ (1.0,0.0) [0.0|18446744073709551615] ""  Gateway,Gateway_PAG

BO_ 2549880427 DIA_MXB_LM_L_Req: 8 Gateway
 SG_ DIA_MXB_LM_L_Req_Data : 0|64@1+ (1.0,0.0) [0.0|18446744073709551615] ""  BCM1

BO_ 2550011499 DIA_MXB_LM_L_Resp: 8 BCM1
 SG_ DIA_MXB_LM_L_Resp_Data : 0|64@1+ (1.0,0.0) [0.0|18446744073709551615] ""  Gateway,Gateway_PAG

BO_ 2549880428 DIA_MXB_LM_R_Req: 8 Gateway
 SG_ DIA_MXB_LM_R_Req_Data : 0|64@1+ (1.0,0.0) [0.0|18446744073709551615] ""  BCM1

BO_ 2550011500 DIA_MXB_LM_R_Resp: 8 BCM1
 SG_ DIA_MXB_LM_R_Resp_Data : 0|64@1+ (1.0,0.0) [0.0|18446744073709551615] ""  Gateway,Gateway_PAG

BO_ 2549880612 DIA_SWP_Req: 8 Gateway
 SG_ DIA_SWP_Req_Data : 0|64@1+ (1.0,0.0) [0.0|18446744073709551615] ""  BCM1

BO_ 2550011684 DIA_SWP_Resp: 8 BCM1
 SG_ DIA_SWP_Resp_Data : 0|64@1+ (1.0,0.0) [0.0|18446744073709551615] ""  Gateway,Gateway_PAG

BO_ 2549880324 DIA_UGDO_S_Req: 8 Gateway
 SG_ DIA_UGDO_S_Req_Data : 0|64@1+ (1.0,0.0) [0.0|18446744073709551615] ""  BCM1

BO_ 2550011396 DIA_UGDO_S_Resp: 8 BCM1
 SG_ DIA_UGDO_S_Resp_Data : 0|64@1+ (1.0,0.0) [0.0|18446744073709551615] ""  Gateway,Gateway_PAG

BO_ 2549880679 DIA_WiBli_L_Req: 8 Gateway
 SG_ DIA_WiBli_L_Req : 0|64@1+ (1.0,0.0) [0.0|18446744073709551615] ""  BCM1

BO_ 2550011751 DIA_WiBli_L_Resp: 8 BCM1
 SG_ DIA_WiBli_L_Resp : 0|64@1+ (1.0,0.0) [0.0|18446744073709551615] ""  Gateway,Gateway_PAG

BO_ 2549880680 DIA_WiBli_R_Req: 8 Gateway
 SG_ DIA_WiBli_R_Req : 0|64@1+ (1.0,0.0) [0.0|18446744073709551615] ""  BCM1

BO_ 2550011752 DIA_WiBli_R_Resp: 8 BCM1
 SG_ DIA_WiBli_R_Resp : 0|64@1+ (1.0,0.0) [0.0|18446744073709551615] ""  Gateway,Gateway_PAG

BO_ 2549880321 DIA_WWS_Req: 8 Gateway
 SG_ DIA_WWS_Req_Data : 0|64@1+ (1.0,0.0) [0.0|18446744073709551615] ""  BCM1

BO_ 2550011393 DIA_WWS_Resp: 8 BCM1
 SG_ DIA_WWS_Resp_Data : 0|64@1+ (1.0,0.0) [0.0|18446744073709551615] ""  Gateway,Gateway_PAG

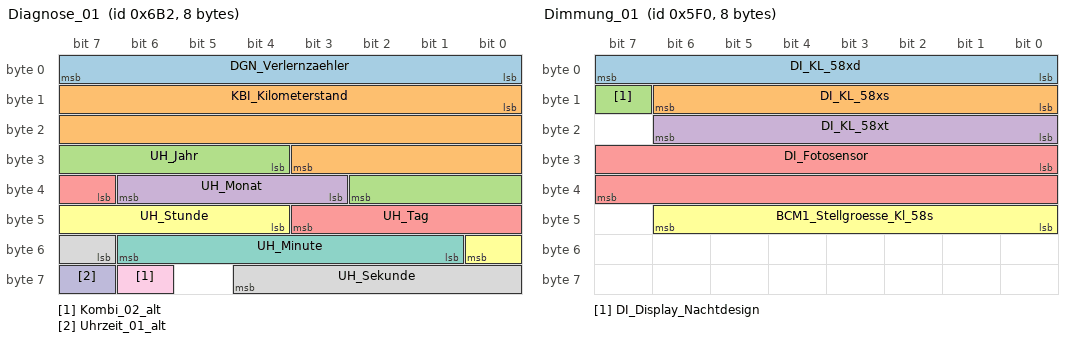
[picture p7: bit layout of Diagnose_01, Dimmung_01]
BO_ 1714 Diagnose_01: 8 Gateway
 SG_ DGN_Verlernzaehler : 0|8@1+ (1,0) [0|254] ""  BCM1,Klima_MSB,Lift_VA,VAS_L,VAS_R
 SG_ KBI_Kilometerstand : 8|20@1+ (1,0) [0|1048573] "Unit_KiloMeter"  BCM1,Klima_MSB,Lift_VA,VAS_L,VAS_R
 SG_ UH_Jahr : 28|7@1+ (1,2000) [2000|2127] "Unit_Year"  BCM1,Klima_MSB,Lift_VA,VAS_L,VAS_R
 SG_ UH_Monat : 35|4@1+ (1,0) [1|12] "Unit_Month"  BCM1,Klima_MSB,Lift_VA,VAS_L,VAS_R
 SG_ UH_Tag : 39|5@1+ (1,0) [1|31] "Unit_Day"  BCM1,Klima_MSB,Lift_VA,VAS_L,VAS_R
 SG_ UH_Stunde : 44|5@1+ (1,0) [0|23] "Unit_Hours"  BCM1,Klima_MSB,Lift_VA,VAS_L,VAS_R
 SG_ UH_Minute : 49|6@1+ (1,0) [0|59] "Unit_Minut"  BCM1,Klima_MSB,Lift_VA,VAS_L,VAS_R
 SG_ UH_Sekunde : 55|6@1+ (1,0) [0|59] "Unit_Secon"  BCM1,Klima_MSB,Lift_VA,VAS_L,VAS_R
 SG_ Kombi_02_alt : 62|1@1+ (1.0,0.0) [0.0|1] ""  Vector__XXX
 SG_ Uhrzeit_01_alt : 63|1@1+ (1.0,0.0) [0.0|1] ""  BCM1,VAS_L,VAS_R

BO_ 1520 Dimmung_01: 8 BCM1
 SG_ DI_KL_58xd : 0|8@1+ (1,0) [0|253] ""  Gateway,Gateway_PAG,Klima_MSB,VAS_L,VAS_R
 SG_ DI_KL_58xs : 8|7@1+ (1,0) [0|100] "Unit_PerCent"  Gateway,Gateway_PAG,Klima_MSB
 SG_ DI_Display_Nachtdesign : 15|1@1+ (1.0,0.0) [0.0|1] ""  Gateway,Gateway_PAG,VAS_L,VAS_R
 SG_ DI_KL_58xt : 16|7@1+ (1,0) [0|100] "Unit_PerCent"  Gateway,Gateway_PAG,Klima_MSB
 SG_ DI_Fotosensor : 24|16@1+ (1,0) [0|65535] ""  Gateway,Gateway_PAG,VAS_L,VAS_R
 SG_ BCM1_Stellgroesse_Kl_58s : 40|7@1+ (1,0) [0|100] ""  Gateway,Gateway_PAG

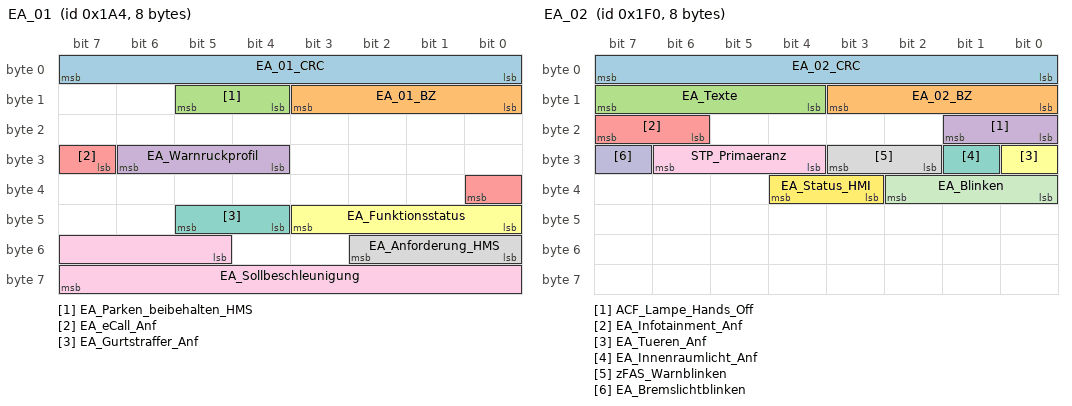
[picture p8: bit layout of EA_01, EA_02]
BO_ 420 EA_01: 8 Gateway
 SG_ EA_01_CRC : 0|8@1+ (1,0) [0|255] ""  Vector__XXX
 SG_ EA_01_BZ : 8|4@1+ (1,0) [0|15] ""  Vector__XXX
 SG_ EA_Parken_beibehalten_HMS : 12|2@1+ (1.0,0.0) [0.0|3] ""  Vector__XXX
 SG_ EA_Warnruckprofil : 28|3@1+ (1.0,0.0) [0.0|7] ""  Vector__XXX
 SG_ EA_eCall_Anf : 31|2@1+ (1.0,0.0) [0.0|3] ""  Vector__XXX
 SG_ EA_Funktionsstatus : 40|4@1+ (1.0,0.0) [0.0|15] ""  BCM1
 SG_ EA_Gurtstraffer_Anf : 44|2@1+ (1.0,0.0) [0.0|3] ""  Vector__XXX
 SG_ EA_Anforderung_HMS : 48|3@1+ (1.0,0.0) [0.0|7] ""  Vector__XXX
 SG_ EA_Sollbeschleunigung : 53|11@1+ (0.005,-7.22) [-7.220|3.005] "Unit_MeterPerSeconSquar"  Vector__XXX

BO_ 496 EA_02: 8 Gateway
 SG_ EA_02_CRC : 0|8@1+ (1,0) [0|255] ""  Vector__XXX
 SG_ EA_02_BZ : 8|4@1+ (1,0) [0|15] ""  Vector__XXX
 SG_ EA_Texte : 12|4@1+ (1.0,0.0) [0.0|15] ""  Vector__XXX
 SG_ ACF_Lampe_Hands_Off : 16|2@1+ (1.0,0.0) [0.0|3] ""  Vector__XXX
 SG_ EA_Infotainment_Anf : 22|2@1+ (1.0,0.0) [0.0|3] ""  Vector__XXX
 SG_ EA_Tueren_Anf : 24|1@1+ (1.0,0.0) [0.0|1] ""  Vector__XXX
 SG_ EA_Innenraumlicht_Anf : 25|1@1+ (1.0,0.0) [0.0|1] ""  BCM1
 SG_ zFAS_Warnblinken : 26|2@1+ (1.0,0.0) [0.0|3] ""  Vector__XXX
 SG_ STP_Primaeranz : 28|3@1+ (1.0,0.0) [0.0|7] ""  Vector__XXX
 SG_ EA_Bremslichtblinken : 31|1@1+ (1.0,0.0) [0.0|1] ""  Vector__XXX
 SG_ EA_Blinken : 32|3@1+ (1.0,0.0) [0.0|7] ""  Vector__XXX
 SG_ EA_Status_HMI : 35|2@1+ (1.0,0.0) [0.0|3] ""  Vector__XXX

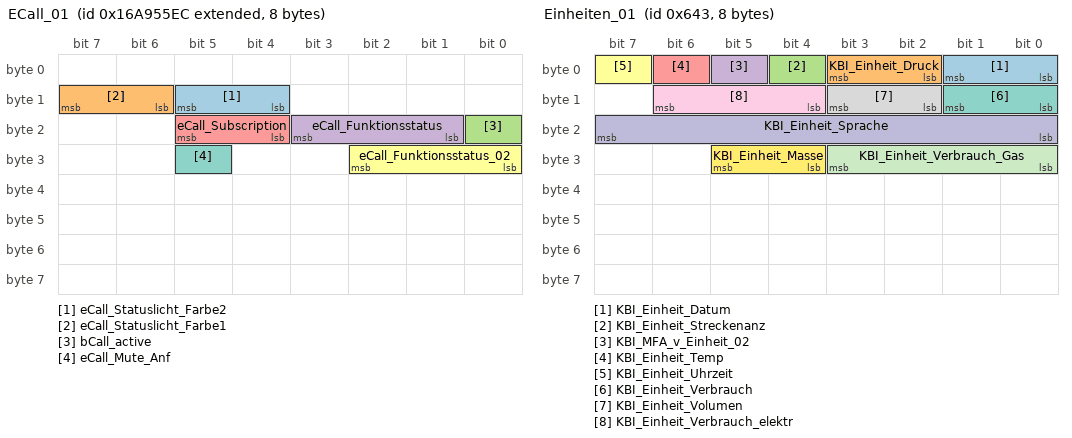
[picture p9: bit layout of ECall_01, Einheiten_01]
BO_ 2527679980 ECall_01: 8 Gateway
 SG_ eCall_Statuslicht_Farbe2 : 12|2@1+ (1.0,0.0) [0.0|3] ""  BCM1
 SG_ eCall_Statuslicht_Farbe1 : 14|2@1+ (1.0,0.0) [0.0|3] ""  BCM1
 SG_ bCall_active : 16|1@1+ (1.0,0.0) [0.0|1] ""  BCM1
 SG_ eCall_Funktionsstatus : 17|3@1+ (1.0,0.0) [0.0|7] ""  Vector__XXX
 SG_ eCall_Subscription : 20|2@1+ (1.0,0.0) [0.0|3] ""  Vector__XXX
 SG_ eCall_Funktionsstatus_02 : 24|3@1+ (1.0,0.0) [0.0|7] ""  BCM1
 SG_ eCall_Mute_Anf : 29|1@1+ (1.0,0.0) [0.0|1] ""  BCM1

BO_ 1603 Einheiten_01: 8 Gateway
 SG_ KBI_Einheit_Datum : 0|2@1+ (1.0,0.0) [0.0|3] ""  Vector__XXX
 SG_ KBI_Einheit_Druck : 2|2@1+ (1.0,0.0) [0.0|3] ""  Vector__XXX
 SG_ KBI_Einheit_Streckenanz : 4|1@1+ (1.0,0.0) [0.0|1] ""  Vector__XXX
 SG_ KBI_MFA_v_Einheit_02 : 5|1@1+ (1.0,0.0) [0.0|1] ""  Vector__XXX
 SG_ KBI_Einheit_Temp : 6|1@1+ (1.0,0.0) [0.0|1] ""  BCM1,Klima_MSB
 SG_ KBI_Einheit_Uhrzeit : 7|1@1+ (1.0,0.0) [0.0|1] ""  Vector__XXX
 SG_ KBI_Einheit_Verbrauch : 8|2@1+ (1.0,0.0) [0.0|3] ""  Vector__XXX
 SG_ KBI_Einheit_Volumen : 10|2@1+ (1.0,0.0) [0.0|3] ""  Vector__XXX
 SG_ KBI_Einheit_Verbrauch_elektr : 12|3@1+ (1.0,0.0) [0.0|7] ""  Vector__XXX
 SG_ KBI_Einheit_Sprache : 16|8@1+ (1,0) [0|255] ""  Vector__XXX
 SG_ KBI_Einheit_Verbrauch_Gas : 24|4@1+ (1.0,0.0) [0.0|15] ""  Vector__XXX
 SG_ KBI_Einheit_Masse : 28|2@1+ (1.0,0.0) [0.0|3] ""  Vector__XXX

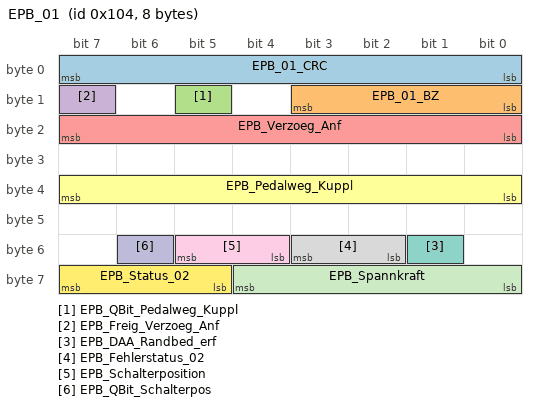
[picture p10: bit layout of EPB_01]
BO_ 260 EPB_01: 8 Gateway
 SG_ EPB_01_CRC : 0|8@1+ (1,0) [0|255] ""  Vector__XXX
 SG_ EPB_01_BZ : 8|4@1+ (1,0) [0|15] ""  Vector__XXX
 SG_ EPB_QBit_Pedalweg_Kuppl : 13|1@1+ (1.0,0.0) [0.0|1] ""  Vector__XXX
 SG_ EPB_Freig_Verzoeg_Anf : 15|1@1+ (1.0,0.0) [0.0|1] ""  Vector__XXX
 SG_ EPB_Verzoeg_Anf : 16|8@1+ (0.048,-7.968) [-7.968|4.224] "Unit_MeterPerSeconSquar"  Vector__XXX
 SG_ EPB_Pedalweg_Kuppl : 32|8@1+ (0.4,0) [8.0|92.0] "Unit_PerCent"  Vector__XXX
 SG_ EPB_DAA_Randbed_erf : 49|1@1+ (1.0,0.0) [0.0|1] ""  Vector__XXX
 SG_ EPB_Fehlerstatus_02 : 50|2@1+ (1.0,0.0) [0.0|3] ""  BCM1
 SG_ EPB_Schalterposition : 52|2@1+ (1.0,0.0) [0.0|3] ""  Vector__XXX
 SG_ EPB_QBit_Schalterpos : 54|1@1+ (1.0,0.0) [0.0|1] ""  Vector__XXX
 SG_ EPB_Spannkraft : 56|5@1+ (1,0) [0|29] "Unit_KiloNewto"  Vector__XXX
 SG_ EPB_Status_02 : 61|3@1+ (1.0,0.0) [0.0|7] ""  BCM1

BO_TX_BU_ 1448 :BCM1,Klima_MSB;
BO_TX_BU_ 1431 :Gateway,Gateway_PAG;
BO_TX_BU_ 870 :Gateway,Gateway_PAG;
BO_TX_BU_ 401 :Gateway,Gateway_PAG;
BO_TX_BU_ 1442 :Gateway,Gateway_PAG;
BO_TX_BU_ 1438 :Gateway,Gateway_PAG;
BO_TX_BU_ 2527679979 :Gateway,Gateway_PAG;
BO_TX_BU_ 1289 :Gateway,Gateway_PAG;
BO_TX_BU_ 2527679654 :Gateway,Gateway_PAG;
BO_TX_BU_ 2463978838 :Gateway,Gateway_PAG;
BO_TX_BU_ 2617128449 :BCM1,Klima_MSB;
BO_TX_BU_ 901 :Gateway,Gateway_PAG;
BO_TX_BU_ 902 :Gateway,Gateway_PAG;
BO_TX_BU_ 1000 :Gateway,Gateway_PAG;
BO_TX_BU_ 1022 :Gateway,Gateway_PAG;
BO_TX_BU_ 615 :Gateway,Gateway_PAG;
BO_TX_BU_ 2617127424 :BCM1,Klima_MSB;
BO_TX_BU_ 2617127679 :BCM1,Klima_MSB;
BO_TX_BU_ 2549880614 :Gateway,Gateway_PAG;
BO_TX_BU_ 2550011686 :BCM1,Klima_MSB;
BO_TX_BU_ 2549880393 :Gateway,Gateway_PAG;
BO_TX_BU_ 2549880347 :Gateway,Gateway_PAG;
BO_TX_BU_ 2550011419 :BCM1,Klima_MSB;
BO_TX_BU_ 2549880340 :Gateway,Gateway_PAG;
BO_TX_BU_ 2549880341 :Gateway,Gateway_PAG;
BO_TX_BU_ 2549880577 :Gateway,Gateway_PAG;
BO_TX_BU_ 2550011649 :BCM1,Klima_MSB;
BO_TX_BU_ 2549880639 :Gateway,Gateway_PAG;
BO_TX_BU_ 2549880330 :Gateway,Gateway_PAG;
BO_TX_BU_ 2549880331 :Gateway,Gateway_PAG;
BO_TX_BU_ 2549880633 :Gateway,Gateway_PAG;
BO_TX_BU_ 2549880350 :Gateway,Gateway_PAG;
BO_TX_BU_ 2549880427 :Gateway,Gateway_PAG;
BO_TX_BU_ 2549880428 :Gateway,Gateway_PAG;
BO_TX_BU_ 2549880612 :Gateway,Gateway_PAG;
BO_TX_BU_ 2549880324 :Gateway,Gateway_PAG;
BO_TX_BU_ 2549880679 :Gateway,Gateway_PAG;
BO_TX_BU_ 2549880680 :Gateway,Gateway_PAG;
BO_TX_BU_ 2549880321 :Gateway,Gateway_PAG;
BO_TX_BU_ 1714 :Gateway,Gateway_PAG;
BO_TX_BU_ 420 :Gateway,Gateway_PAG;
BO_TX_BU_ 496 :Gateway,Gateway_PAG;
BO_TX_BU_ 2527679980 :Gateway,Gateway_PAG;
BO_TX_BU_ 1603 :Gateway,Gateway_PAG;
BO_TX_BU_ 260 :Gateway,Gateway_PAG;
CM_ BO_ 870 "Nur die Kombination des statischen und toggelnden Signals ergibt den Blinktakt für die Hell & Dunkelphase";
CM_ BO_ 868 "Botschaft wird vom BCM1 gesendet, wenn BCM2 ausfällt (Fail-Safe) und die Funktion 'Blinken' aktiv ist
";
CM_ BO_ 901 "ab MQB ohne CHK und mit geänderter Sendeart";
CM_ BO_ 902 "ab MQB 7.2.1";
CM_ BO_ 2549880614 "LIN Flashen Active Aroma Unit (DK2F)";
CM_ BO_ 2550011686 "LIN Flashen Active Aroma Unit (DK2F)";
CM_ BO_ 2549880393 "LIN Flashen elektrisch verstellbare Lenksäule (DK2F)";
CM_ BO_ 2550011465 "LIN Flashen elektrisch verstellbare Lenksäule (DK2F)";
CM_ BO_ 2549880347 "LIN Flashen Blower (DK2F)";
CM_ BO_ 2550011419 "LIN Flashen Blower (DK2F)";
CM_ BO_ 2549880340 "Diagnosezugriff & Flashen Leistungsmodul gleitende Leuchtweite";
CM_ BO_ 2549880341 "Diagnosezugriff Leistungsmodul gleitende Leuchtweite";
CM_ BO_ 2549880577 "LIN Flashen Klimapanel hinten (DK2F)";
CM_ BO_ 2550011649 "LIN Flashen Klimapanel hinten (DK2F)";
CM_ BO_ 2549880639 "LIN Flashen KPV (DK2F)";
CM_ BO_ 2550011711 "LIN Flashen KBF (DK2F)";
CM_ BO_ 2549880330 "Diagnosezugriff Leistungsmodul LED";
CM_ BO_ 2549880331 "Diagnosezugriff Leistungsmodul LED";
CM_ BO_ 2549880633 "LIN Flashen Innenlichtmodul 2 (DK2F)";
CM_ BO_ 2550011705 "LIN Flashen Innenlichtmodul 2 (DK2F)";
CM_ BO_ 2549880350 "LIN Flashen Innenlichtmodul (DK2F)";
CM_ BO_ 2550011422 "LIN Flashen Innenlichtmodul (DK2F)";
CM_ BO_ 2549880427 "Diagnosezugriff Leistungsmodul Matrix Beam";
CM_ BO_ 2549880428 "Diagnosezugriff Leistungsmodul Matrix Beam";
CM_ BO_ 2549880324 "LIN Flashen Universal Garage Door Opener (DK2F)";
CM_ BO_ 2550011396 "LIN Flashen Universal Garage Door Opener (DK2F)";
CM_ BO_ 2549880321 "LIN Flashen Wischwinkelsteuerung (DK2F)";
CM_ BO_ 2550011393 "LIN Flashen Wischwinkelsteuerung (DK2F)";
CM_ BO_ 1520 "ab MQB nach abgestimmten FLH Dimmung";
CM_ BO_ 1603 "ab MQB mit 8 Byte";
CM_ BO_ 260 "ab MQB mit CRC-8";

CM_ SG_ 1448 BCM1_FlHz_BFS_PWM_A "Flächenheizung: Leistungsvorgabe
0-100: PWM in Prozent (spannungskompensiert)
101: 100 % PWM nicht spannungskompensiert
";
CM_ SG_ 1448 BCM1_FlHz_BFS_PWM_B "Flächenheizung: Leistungsvorgabe
0-100: PWM in Prozent (spannungskompensiert)
101: 100 % PWM nicht spannungskompensiert
";
CM_ SG_ 1448 BCM1_FlHz_HBFS_PWM_A "Flächenheizung: Leistungsvorgabe
0-100: PWM in Prozent (spannungskompensiert)
101: 100 % PWM nicht spannungskompensiert
";
CM_ SG_ 1448 BCM1_FlHz_HBFS_PWM_B "Flächenheizung: Leistungsvorgabe
0-100: PWM in Prozent (spannungskompensiert)
101: 100 % PWM nicht spannungskompensiert
";
CM_ SG_ 1448 BCM1_FlHz_HL_HLR_Anf "Anforderung eines prozentualen Leistungskontingents für die Flächenheizung hinten links";
CM_ SG_ 1448 BCM1_FlHz_HR_HLR_Anf "Anforderung eines prozentualen Leistungskontingents für die Flächenheizung hinten rechts";
CM_ SG_ 1448 BCM1_FlHz_Ruhesitz_HLR_Anf "Anforderung eines prozentualen Leistungskontingents für die Flächenheizung des Ruhesitz";
CM_ SG_ 1448 BCM1_FlHz_Stufe_HL "Statusmeldung Flächenheizung hinten links";
CM_ SG_ 1448 BCM1_FlHz_Stufe_HR "Statusmeldung Flächenheizung hinten rechts";
CM_ SG_ 1448 BCM1_FlHz_Stufe_VL "Statusmeldung Flächenheizung vorne links";
CM_ SG_ 1448 BCM1_FlHz_Stufe_VR "Statusmeldung Flächenheizung vorne rechts";
CM_ SG_ 1448 BCM1_FlHz_VL_HLR_Anf "Anforderung eines prozentualen Leistungskontingents für die Flächenheizung vorne links";
CM_ SG_ 1448 BCM1_FlHz_VR_HLR_Anf "Anforderung eines prozentualen Leistungskontingents für die Flächenheizung vorne rechts";

CM_ SG_ 961 APS_LED_Status "Das Signal beschreibt den Zustand der APS LED für die Einparkhilfe, die im MLBevo vom BCM1 oder LIN Schalterleiste (BCM1 Slave) angesteuert wird.";
CM_ SG_ 961 APS_Taster "Das Signal beschreibt den Zustand der Taste, die im MLBevo vom BCM1 eingelesen wird.";
CM_ SG_ 961 AVH_LED_Status "Das Signal beschreibt den Zustand der AVH LED, die im MLBevo vom BCM1 oder LIN Schalterleiste (BCM1 Slave) angesteuert wird.
";
CM_ SG_ 961 AVH_Taster "Das Signal beschreibt den Zustand der AVH Taste, die im MLBevo vom BCM1 eingelesen wird.
";
CM_ SG_ 961 Display_Taster "Taster für Display Klappung";
CM_ SG_ 961 Drivesel_1_Taster "Taster 1 für Drive Select Betätigung";
CM_ SG_ 961 Drivesel_2_Taster "Taster 2 für Drive Select Betätigung";
CM_ SG_ 961 eCall_Taste "Status der eCall-Taste. 
(Emergency Call / SOS Hilferuf)";
CM_ SG_ 961 ESP_Off_Taster "Das Signal beschreibt den Zustand der ESP Taste, die im MLBevo vom BCM1 eingelesen wird.
";
CM_ SG_ 961 HDC_LED_Status "Das Signal beschreibt den Zustand der HDC LED, die im MLBevo vom BCM1 oder LIN Schalterleiste (BCM1 Slave) angesteuert wird.	";
CM_ SG_ 961 HDC_Taster "Das Signal beschreibt den Zustand der HDC Taste, die im MLBevo vom BCM1 eingelesen wird
0 = Taste nicht betätigt
1 = Taste entprellt betätigt
2 = Init oder Taste nicht verbaut
3 = Fehler";
CM_ SG_ 961 Heckrollo_2_Taster "Taster 2 für Heckrollo Betätigung";
CM_ SG_ 961 Heckrollo_Taster "Taster für Heckrollo Betätigung";
CM_ SG_ 961 LIM_bCall_Taster "Statusinformation des Service Call Tasters im Dachmodul";
CM_ SG_ 961 LIM_PAO_Alivesignal "Alive-Information zur Absicherung von Timeouterkennung bei Routing über mehrere Bussegmente";
CM_ SG_ 961 LIM_PAO_OFF_Status "Istwert für LED 'OFF' in Anzeige Passenger Airbag On/Off";
CM_ SG_ 961 LIM_PAO_ON_Status "Istwert für LED 'ON' in Anzeige Passenger Airbag On/Off";
CM_ SG_ 961 LIM_PAO_Schriftzug_Status "Istwert für LED 'PASSENGER AIRBAG' in Anzeige Passenger Airbag On/Off";
CM_ SG_ 961 LKS_Taster "Taste zum de-/aktivieren der Funktion LKS (Lane Keeping System)

0 - Taste nicht betätigt
1 - Taste betätigt
2 - INIT oder Taste nicht verbaut
3 - Fehler (Timeout, hängender Taster)";
CM_ SG_ 961 PLA_LED_Status "Das Signal beschreibt den Zustand der PLA LED, die im MLBevo vom BCM1 oder LIN Schalterleiste (BCM1 Slave) angesteuert wird.";
CM_ SG_ 961 PLA_Taster "Das Signal beschreibt den Zustand der PLA (Parklenkassisten) Taste, die im MLBevo vom BCM1 eingelesen wird.";
CM_ SG_ 961 PLA_Taster_Fehler_Roh "PLA Taster Fehlerstatus als ungefiltertes Signal für eine schnelle Fehlererkennung und Verarbeitung im IPA";
CM_ SG_ 961 Sideview_Taster "Taster für SIDEVIEW Betätigung";
CM_ SG_ 961 Spoiler_LED_Status "Status der Funktions LED SPOILER Ein/Ausfahren.";
CM_ SG_ 961 Spoiler_Taster "Taster für SPOILER Betätigung";
CM_ SG_ 961 SWA_Taster "SWA Taster vom BCM1 (quelle LDS)";

CM_ SG_ 1432 BCM1_eSound_Taster "Das Signal beschreibt den Zustand der eSound Taste, die im MLBevo vom BCM1 eingelesen wird
0 = Taste nicht betätigt
1 = Taste entprellt betätigt
2 = Init oder Taste nicht verbaut
3 = Fehler";
CM_ SG_ 1432 BCM1_NR_Ride_Height_Down_Taster "Tastersignal zum Absenken des Fahrzeugs bei höhenverstellbaren Fahrzeugen (Taster/Bedieneinheit an Schalterleiste 2  BCM1)
";
CM_ SG_ 1432 BCM1_NR_Ride_Height_Up_Taster "Tastersignal zum Anheben des Fahrzeugs bei höhenverstellbaren Fahrzeugen (Taster/Bedieneinheit an Schalterleiste 2  BCM1";
CM_ SG_ 1432 BCM_BFS_Fernsteuerung_aktiv "Fernsteuerung BFS aktiv";
CM_ SG_ 1432 BCM_BFS_Massage_Taster "Ansteuerungs-Signalisierung der Pneumatik-Funktionen";
CM_ SG_ 1432 BCM_BFS_Multif_Taster "Ansteuerungs-Signalisierung der Pneumatik-Funktionen";
CM_ SG_ 1432 BCM_BFS_Pneumatik_Verstellung "Ansteuerungs-Signalisierung der Pneumatik-Funktionen";
CM_ SG_ 1432 BCM_BFS_Programmwippe "Ansteuerungs-Signalisierung der Pneumatik-Funktionen";
CM_ SG_ 1432 BCM_FS_Massage_Taster "Ansteuerungs-Signalisierung der Pneumatik-Funktionen";
CM_ SG_ 1432 BCM_FS_Multif_Taster "Ansteuerungs-Signalisierung der Pneumatik-Funktionen";
CM_ SG_ 1432 BCM_FS_Pneumatik_Verstellung "Ansteuerungs-Signalisierung der Pneumatik-Funktionen";
CM_ SG_ 1432 BCM_FS_Programmwippe "Ansteuerungs-Signalisierung der Pneumatik-Funktionen";
CM_ SG_ 1432 BCM_Soundklappe_Taster "Status Soundklappe Taste";
CM_ SG_ 1432 E_Sound_LED_Status "Das Signal beschreibt den Zustand der eSound LED, die im MLBevo vom BCM1 oder LIN Schalterleiste (BCM1 Slave) angesteuert wird.";
CM_ SG_ 1432 LIM_S_Rollo_hi "Schalterfeld LIM für Sonnenrolle Schiebedach hinten";
CM_ SG_ 1432 LIM_S_Rollo_vo "Schalterfeld LIM für Sonnenrolle Schiebedach vorne";
CM_ SG_ 1432 LIM_S_SAD_hi "Schalterfeld LIM für SAD hinten";
CM_ SG_ 1432 LIM_S_SAD_Vo "Schalterfeld LIM für SAD vorne";
CM_ SG_ 1432 Pilot_Taster "Das Signal beschreibt den Zustand der Pilot Taste, die im MLBevo vom BCM1 eingelesen wird
0 = Taste nicht betätigt
1 = Taste entprellt betätigt
2 = Init oder Taste nicht verbaut
3 = Fehler";

CM_ SG_ 1431 BED_Rollo_vo "Schalterfeld MIKO für Sonnenrollo Schiebedach vorne";
CM_ SG_ 1431 BED_SAD_vo "Bedienschalter für Schiebe / Ausstelldach vorne";
CM_ SG_ 1431 BED_Taster_Fahrwerk "Beschreibt den Fahrwerkstaster";
CM_ SG_ 1431 BED_Taster_Lift "Betätigungsstatus der Lift - Taste";
CM_ SG_ 1431 BED_Taster_VD_Oeffnen "Signal des Verdecktasters zum Oeffnen des Verdecks";
CM_ SG_ 1431 BED_Taster_VD_Schliessen "Signal des Verdecktasters zum Schliessen des Verdecks";
CM_ SG_ 1431 BED_Taster_Windschott "Bedientaster zum Aufstellen und Ablegen des Windschott";
CM_ SG_ 1431 SoSe_SunInt_2D_Li_Dash "Sonnenintensität links (2D Sensor) Dashboard";
CM_ SG_ 1431 SoSe_SunInt_2D_Re_Dash "Sonnenintensität rechts (2D Sensor) Dashboard";

CM_ SG_ 870 Blinken_li_Fzg_Takt "Fzg-Takt Blinker links

";
CM_ SG_ 870 Blinken_li_Kombi_Takt "Kombi-Takt Blinker links

";
CM_ SG_ 870 Blinken_re_Fzg_Takt "Fzg-Takt Blinker rechts

";
CM_ SG_ 870 Blinken_re_Kombi_Takt "Kombi-Takt Blinker rechts

";
CM_ SG_ 870 BM_Autobahn "Status Autobahnblinken
";
CM_ SG_ 870 BM_Crash "Status Crashblinken
";
CM_ SG_ 870 BM_DWA_Alarm "Status DWA-Alarmblinken
";
CM_ SG_ 870 BM_DWA_ein "Status Quittierungsblinken DWA";
CM_ SG_ 870 BM_GDO "Blinken bei UGDO anlernen

";
CM_ SG_ 870 BM_HD_Oeffnung_angelernt "HD_Rueckmeld_prog eine Blinkerquittierung wird beim BCM2 angefordert.
Wenn die Geschwindigkeit kleiner einer vorgegebenen Schwelle (default 2km/h) ist wird das Signal BM_HD_Öffnung_angelernt versendet und die Blinkerquittierung ausgelöst";
CM_ SG_ 870 BM_links "Richtungsblinken links

";
CM_ SG_ 870 BM_NBA_n_codiert_n_aktiv "Notbremsanzeige nicht codiert/nicht aktiv (Fehler)";
CM_ SG_ 870 BM_NBA_Status "Notbremsanzeige Status nicht aktiv / BRL Dunkelphase / BRL Hellphase";
CM_ SG_ 870 BM_Not_Bremsung "Das Signal BM_Not_Bremsung  zeigt an,  ob ein Warnblinken aufgrund einer vom Bremssystem signalisierten Notbremsung aktiv ist.";
CM_ SG_ 870 BM_Panik "Panikblinken
";
CM_ SG_ 870 BM_PiloPa "Quittierungsblinken bei pilotierten Parkvorgängen";
CM_ SG_ 870 BM_Recas "Blinkermodus RECAS  (RearEndCollisionAlertSignal)";
CM_ SG_ 870 BM_rechts "Richtungsblinken rechts

";
CM_ SG_ 870 BM_Rollenmodus_Blinken "Das Signal wird statisch gesetzt, wenn die Blinkerart Rollenmodus_Blinken aktiv ist.";
CM_ SG_ 870 BM_Taxi_Notalarm "Blinken bei Taxi-Not-Alarm

";
CM_ SG_ 870 BM_Telematik "Telematikblinken
";
CM_ SG_ 870 BM_Telematik_Abbruchgrund "Gibt bei erwaretem aber ausbleibendem Flankenanstieg der BM_Telematik an wieso die Ausführung verhindert wurde. Bei Flankenabfall der BM_Telematik wird angegeben wieso die Ausführung beendet wurde.

Bei nicht bereitem Sender soll 'init' gesendet werden,";
CM_ SG_ 870 BM_Warnblinken "Warnblinken

";
CM_ SG_ 870 BM_WBT_Beleuchtung "Aktivierung Warnblinktasterfunktionsbeleuchtung
Warnblinktasterfunktionsbeleuchtung soll aktiviert werden (statisch auf 1)";
CM_ SG_ 870 BM_Wischblinken "Blinkermodus Wisch_Blinken";
CM_ SG_ 870 BM_ZV_auf "Blinken bei ZV auf

";
CM_ SG_ 870 BM_ZV_zu "Blinken bei ZV zu

";
CM_ SG_ 870 DWA_Alarmquelle "Signalisiert den Auslösegrund der DWA";

CM_ SG_ 868 NBlinken_li_Fzg_Takt "Notlaufblinken, Fhzg-Takt links

";
CM_ SG_ 868 NBlinken_li_Kombi_Takt "Notlaufblinken, Blinkerkontrolllampe links

";
CM_ SG_ 868 NBlinken_re_Fzg_Takt "Notlaufblinken, Fhzg-Takt rechts
";
CM_ SG_ 868 NBlinken_re_Kombi_Takt "Notlaufblinken, Blinkerkontrolllampe rechts

";

CM_ SG_ 401 BMS_01_BZ "Botschaft asynchron geroutet. Zählerwert kann springen.";
CM_ SG_ 401 BMS_01_CRC "Für MLB:
'Berechnung siehe Lastenheft 'Kommunikationsabsicherung für FlexRay und CAN''

Ab MQB und MLBevo:
'Berechnung siehe Lastenheft 'End-to-End Kommunikationsabsicherung''

Endwerte siehe Begleitdokument 'S-PDU Kennungsfolgen'";
CM_ SG_ 401 BMS_IstSpannung "actual voltage of the battery / Momentanwert: Batteriespannung";
CM_ SG_ 401 BMS_IstStrom_02 "Momentanwert: Batteriestrom
Stromrichtung: ein Ladestrom wird mit positiven, ein Entladestrom mit negativen Werten angegeben";
CM_ SG_ 401 BMS_IstStrom_02_Offset "Nachkommastelle des BMS_IstStrom_02";
CM_ SG_ 401 BMS_IstStrom_02_OffsetVZ "Vorzeichen des Offsets, bzw. der Nachkommastelle";
CM_ SG_ 401 BMS_SOC_HiRes "State of Charge / aktueller Ladezustand der Batterie (höhere Auflösung)";
CM_ SG_ 401 BMS_Spannung_ZwKr "Momentanwert: 
Spannung an den Batterie-HV-Anschlüssen";

CM_ SG_ 1442 BMS_04_CRC "Für MLB:
'Berechnung siehe Lastenheft 'Kommunikationsabsicherung für FlexRay und CAN''

Ab MQB und MLBevo:
'Berechnung siehe Lastenheft 'End-to-End Kommunikationsabsicherung''

Endwerte siehe Begleitdokument 'S-PDU Kennungsfolgen'";
CM_ SG_ 1442 BMS_Abschaltankuendigung "Zeitliche Ankündigung einer Abschaltung der HV Batterie.";
CM_ SG_ 1442 BMS_Fehlerstatus "aktueller Fehlerstatus der Batterie";
CM_ SG_ 1442 BMS_IstModus "Aktueller Betriebsmodus der Batterie
0: Standby; Schuetze geoeffnet; Kommunikation aktiv
1: Hauptschuetze geschlossen / HV-Netz aktiviert / normaler Fahrbetrieb
2: projektabhaengig belegt (z.B. Balancing, erweitertes DC-Schnelladen)
3: externes Laden ";
CM_ SG_ 1442 BMS_Kapazitaet_02 "Nutzbare Kapazität der Batterie,
oder alterungsabhängige absolute Gesamtkapazität der Batterie.

Projektabhängig kann die Kapazität auf das nutzbare SOC-Fenster (zwischen oberer und unterer SOC-Grenze) bezogen sein, wobei sich dieses SOC-Fenster alteru";
CM_ SG_ 1442 BMS_OBD_Lampe_Anf "Anforderung MIL (MalfunctionIndicationLamp) von BMS (Motorsteuergerät reicht diese Info an Kombi weiter).";
CM_ SG_ 1442 BMS_Soll_SOC_HiRes "Der Sollwert für den HV-Batterie-SOC bei einer SOC-steuernden Betriebsstrategie";
CM_ SG_ 1442 BMS_Status_ServiceDisconnect "Status des Service Disconnect, ob dieser gesteckt oder gezogen ist.
Abhängigkeiten zu anderen Signalen: BMS_Fehler_Sicherung und BMS_Fehler_Pilot";
CM_ SG_ 1442 BMS_Status_Spgfreiheit "0=Init (ohne Funktion)
1=BMS Zwischenkreis spannungsfrei (U_Zwkr < 20V)
2=BMS Zwischenkreis nicht spannungsfrei (U_Zwkr >/= 25V, Hysterese)
3=Fehler (z.B. Fehler in der Sensorik)";

CM_ SG_ 1438 BMS_Batterie_Voko_Anf "Anforderung des BMC die Bauteilvorkonditionierung der HV-Batterie durchzuführen.";
CM_ SG_ 1438 BMS_Fehler_NTKreis "Fehler im NTKreis, HV-Batterie wird nicht klimatisiert
(Fehler, Fehlerfrei) ";
CM_ SG_ 1438 BMS_Fehlerstatus_EWP_02 "Fehlerstatus der elektrischen Wasserpumpe der HV-Batterie";
CM_ SG_ 1438 BMS_IstRuecklaufTemperatur_02 "Aktuelle Ruecklauftemperatur der Batterie";
CM_ SG_ 1438 BMS_IstVorlaufTemperatur "Aktuelle Vorlauftemperatur der Batterie";
CM_ SG_ 1438 BMS_Soll_PWM_Pumpe "Ansteuerungs-Sollwert der Batterie-Kühlmittelpumpe. 
Speziell im MQB PHEV: Istwert der Pumpenansteuerung (Batterie steuert Pumpe selbständig an).";
CM_ SG_ 1438 BMS_SollVolumenstrom "Soll Volumenstrom für Kühlkreislauf Batterie";
CM_ SG_ 1438 BMS_SollVorlauftemperatur "Soll_Vorlauftemperatur_Kühlmedium in °C";
CM_ SG_ 1438 BMS_Status_Ventil "Status des 3-2-Wege-Ventils (betätigt/unbetätigt/Fehler)";
CM_ SG_ 1438 BMS_Temp_Epsilon "Das Signal beschreibt die Differenz zwischen Batterie Soll-Temperatur und Batterie Ist-Temperatur.";
CM_ SG_ 1438 BMS_Temperatur "battery temperature / Momentanwert: Temperatur der Traktionsbatterie";
CM_ SG_ 1438 BMS_Temperierung_Anf "Temperierungsbedarf der HV-Batterie";

CM_ SG_ 2527679979 BMS_BCCM_Anforderung "Signal zum HVLM zur Aktivierung BCCM aufgrund Grenzwertüberschreitung Standzeitzähler";
CM_ SG_ 2527679979 BMS_HV_Auszeit "Zeit seit letzter Hochvoltaktivität.";
CM_ SG_ 2527679979 BMS_HV_Auszeit_Status "Status HV-Auszeit.";
CM_ SG_ 2527679979 BMS_Kapazitaet "Gesamtenergiekapazitaet der HV-Batterie unter Berücksichtigung der Alterung";
CM_ SG_ 2527679979 BMS_max_Grenz_SOC "oberer Grenz SOC - Betriebsstrategie";
CM_ SG_ 2527679979 BMS_min_Grenz_SOC "unterer Grenz SOC - Betriebsstrategie";
CM_ SG_ 2527679979 BMS_SOC_Kaltstart "Abhängig von der notwendigen Kaltstartleistung berechneter SOC Wert.";

CM_ SG_ 1289 BMS_Energieinhalt_HiRes "aktuell nutzbarer Energieinhalt der HV-Batterie
(bezogen auf ein definiertes mittleres Belastungsprofil)";
CM_ SG_ 1289 BMS_MaxEnergieinhalt_HiRes "maximal nutzbarer Energieinhalt der HV-Batterie
(bezogen auf ein definiertes mittleres Belastungsprofil)";
CM_ SG_ 1289 BMS_NutzbarerEnergieinhalt "Restenergieinhalt der Traktionsbatterie, bezogen auf die Betriebsstrategiegrenzen";
CM_ SG_ 1289 BMS_NutzbarerSOC "Aktueller relativer Ladezustand der HV-Batterie";
CM_ SG_ 1289 BMS_Pred_Entladeperformance "Indikator Stromintegral in Entladerichtung. 
0%     = Start abrampen Peak-Entladestromgrenze auf Dauer-Entladestromgrenze.
100% = Voller Peak-Entladestrom verfügbar";
CM_ SG_ 1289 BMS_Pred_Ladeperformance "Indikator Stromintegral in Laderichtung. 
0%     = Start abrampen Peak-Ladestromgrenze auf Dauer-Ladestromgrenze.
100% = Voller Peak-Ladestrom verfügbar";

CM_ SG_ 2527679654 BMS_IsoFehler "Ergebnis der Isolationsmessung des BMS";
CM_ SG_ 2527679654 BMS_IsoZustand "Ergebnis des aktuellen/letzten Isolations-Meßzyklus: Messung läuft; Messung Batterie-intern oder Gesamtsystem; gemessener Wert unterschreitet Schwelle 1 / Schwelle 2.";
CM_ SG_ 2527679654 BMS_IstTemperatur_hoechste "aktuell höchste Temperatur in der Batterie";
CM_ SG_ 2527679654 BMS_IstTemperatur_niedrigste "aktuell niedrigsteTemperatur in der Batterie";
CM_ SG_ 2527679654 BMS_IstZellspannung_hoechste "höchster Wert aller Zellspannungen im BMS";
CM_ SG_ 2527679654 BMS_IstZellspannung_niedrigste "niedrigster Wert aller Zellspannungen im BMS";

CM_ SG_ 2589283666 BMS_EnergieAntw_Energie "Für Laden der HV-Batterie notwendige Energie (um angefragten SOC-Hub zu erreichen).";
CM_ SG_ 2589283666 BMS_EnergieAntw_Zaehler "Fortlaufender Zähler für die Antwort Energie.";
CM_ SG_ 2589283666 BMS_LadegrenzeAntw_Leistung "Ladeleistung mit welcher bis zu SOC aus BMS_LadegrenzeAntw_SOC geladen werden kann.";
CM_ SG_ 2589283666 BMS_LadegrenzeAntw_SOC "SOC-Grenze bis zu welcher mit der Leistung aus BMS_LadegrenzeAntw_Leistung geladen werden kann.";
CM_ SG_ 2589283666 BMS_LadegrenzeAntw_Zaehler "Fortlaufender Zähler für die Antwort Leistung.";
CM_ SG_ 2589283666 BMS_MMTR_Status "Status der HVB zur Funktion Make me track ready";

CM_ SG_ 2463978838 BMS_NutzbarerEnergieinhalt_HiRes "Restenergieinhalt der Traktionsbatterie, bezogen auf die Betriebsstrategiegrenzen";
CM_ SG_ 2463978838 BMS_ZellTemp_virtuell_max "Maximaler Wert der Zelltemperatur der HVB, Berechnung über Thermomodell";
CM_ SG_ 2463978838 BMS_ZellTemp_virtuell_min "Minimaler Wert der Zelltemperatur der HVB, Berechnung über Thermomodell";

CM_ SG_ 901 CHA_Fahrer_Umschaltung "Die manuelle Umschaltung durch den Fahrer soll signalisiert werden, um zu automatischen Umschaltungen (z.B. Retries) differenzieren zu können.";
CM_ SG_ 901 CHA_Fahrer_Umschaltung_BMA "Die manuelle Umschaltung der Betriebsmodusauswahl durch den Fahrer soll signalisiert werden, um zu automatischen Umschaltungen (z.B. Retries) differenzieren zu können.";
CM_ SG_ 901 CHA_Ziel_FahrPr_ACC "MQB
Anforderung Ziel-Fahrprogramm ACC";
CM_ SG_ 901 CHA_Ziel_FahrPr_AFS "Anforderung Ziel-Fahrprogramm AFS";
CM_ SG_ 901 CHA_Ziel_FahrPr_AGA "Anforderung Ziel-Fahrprogramm AGA/SAK2 (Aussensound)";
CM_ SG_ 901 CHA_Ziel_FahrPr_ALR "Anforderung Ziel-Fahrprogramm Allrad";
CM_ SG_ 901 CHA_Ziel_FahrPr_DR "Anforderung Ziel-Fahrprogramm Dämpfer";
CM_ SG_ 901 CHA_Ziel_FahrPr_EPS "Anforderung Ziel-Fahrprogramm Elektrische Lenkhilfe";
CM_ SG_ 901 CHA_Ziel_FahrPr_ESP "Anforderung Ziel-Fahrprogramm ESP";
CM_ SG_ 901 CHA_Ziel_FahrPr_Freilauf "Anforderung Ziel-Fahrprogramm Funktion Freilauf";
CM_ SG_ 901 CHA_Ziel_FahrPr_GE "Anforderung Ziel-Fahrprogramm Getriebe";
CM_ SG_ 901 CHA_Ziel_FahrPr_MO "Anforderung Ziel-Fahrprogramm Motor";
CM_ SG_ 901 CHA_Ziel_FahrPr_MO_BZS "Anforderung Zielfahrprogramm Motor-Betriebszusände";
CM_ SG_ 901 CHA_Ziel_FahrPr_MO_StSt "Anforderung Ziel-Fahrprogramm Funktion Motor Start-Stopp";
CM_ SG_ 901 CHA_Ziel_FahrPr_PreCrash "Anforderung Ziel-Fahrprogramm PreCrash";
CM_ SG_ 901 CHA_Ziel_FahrPr_SAK "Anforderung Ziel-Fahrprogramm Soundaktuator";
CM_ SG_ 901 CHA_Ziel_FahrPr_VAQ "Anforderung Ziel-Fahrprogramm VAQ";

CM_ SG_ 902 CHA_Charge_LED "Ansteuerung der LED am Charge-Taster durch Charisma im PHEV";
CM_ SG_ 902 CHA_Current_Mode "Aktuell eingestelltes Charisma Fahrprogramm";
CM_ SG_ 902 CHA_Drehschalter_Istmodus "Aktuell eingestellte Vorgabe für Schalterposition des CHA-Drehschalters";
CM_ SG_ 902 CHA_Drive_Select1_LED "CHA Ansteuer Signal der Funktions LED";
CM_ SG_ 902 CHA_Eco_Charisma_LED "Ansteuerung der Funktions-LED der ECO alias Bluekey Taste bzw. Charisma-Taste.
Der Master der Fahrmodus-Funktion soll die Funktionsleuchte ansteuern, in der MQB Architektur ist der Master im Gateway untergebracht.";
CM_ SG_ 902 CHA_EV_LED "Ansteuerung der LED am EV-Taster durch Charisma im PHEV";
CM_ SG_ 902 CHA_Fahrer_Umschaltung "Die manuelle Umschaltung durch den Fahrer soll signalisiert werden, um zu automatischen Umschaltungen (z.B. Retries) differenzieren zu können.";
CM_ SG_ 902 CHA_Kombi_Texte "Anzeige des aktuellen Charisma-Fahrprofiles im Kombi.
Die Texte werden HUT-Spezifisch in einem Schnittstellen-LAH definiert.";
CM_ SG_ 902 CHA_Kombi_Texte_02 "Anzeige von Hinweistexten bzgl. Charismaumschaltungen im Kombi.
Die Texte werden HUT-Spezifisch in einem Schnittstellen-LAH definiert.";
CM_ SG_ 902 CHA_Offroad_LED "Ansteuerung der Offroad-LED";
CM_ SG_ 902 CHA_Ziel_FahrPr_03_01 "reserviert für Anforderung Ziel-Fahrprogramm";
CM_ SG_ 902 CHA_Ziel_FahrPr_03_02 "reserviert für Anforderung Ziel-Fahrprogramm";
CM_ SG_ 902 CHA_Ziel_FahrPr_AMB "Anforderung Ziel-Fahrprogramm Ambientelichtmodul";
CM_ SG_ 902 CHA_Ziel_FahrPr_HSP "Anforderung Ziel-Fahrprogramm Heckspoiler";
CM_ SG_ 902 CHA_Ziel_FahrPr_IVB "Anforderung Ziel-Fahrprogramm IVB";
CM_ SG_ 902 CHA_Ziel_FahrPr_KL "Anforderung Ziel-Fahrprogramm Klima";
CM_ SG_ 902 CHA_Ziel_FahrPr_RWB "Anforderung Zielfahrprogramm Reichweitenberechnung (RWB)";

CM_ SG_ 1000 CHA_Fahrer_Umschaltung "Die manuelle Umschaltung durch den Fahrer soll signalisiert werden, um zu automatischen Umschaltungen (z.B. Retries) differenzieren zu können.";
CM_ SG_ 1000 CHA_Ziel_FahrPr_AFR "Anforderung Ziel-Fahrprogramm Aktive Fahrwerk Regelung (eAWS und eABC)";
CM_ SG_ 1000 CHA_Ziel_FahrPr_AV "Anforderung Ziel-Fahrprogramm AreaView2";
CM_ SG_ 1000 CHA_Ziel_FahrPr_EAR "Anforderung Zielfahrprogramm EAR (EFP Allrad Regelsysteme)";
CM_ SG_ 1000 CHA_Ziel_FahrPr_EBKV "Signal zur Ansteuerung des EBKV durch den Charisma-Koordinator";
CM_ SG_ 1000 CHA_Ziel_FahrPr_FCWO "Anforderung Ziel-Fahrprogramm FCWO (Objektwarnung)";
CM_ SG_ 1000 CHA_Ziel_FahrPr_FCWP "Anforderung Ziel-Fahrprogramm FCWP (Personenwarnung)";
CM_ SG_ 1000 CHA_Ziel_FahrPr_HAL "Anforderung Zielfahrprogramm Hinterachslenkung (HAL)";
CM_ SG_ 1000 CHA_Ziel_FahrPr_HDC "Anforderung Ziel-Fahrprogramm Hill Descent Control";
CM_ SG_ 1000 CHA_Ziel_FahrPr_IL "Anforderung Ziel-Fahrprogramm Integrallenkung";
CM_ SG_ 1000 CHA_Ziel_FahrPr_MXB "Anforderung Ziel-Fahrprogramm MXB";
CM_ SG_ 1000 CHA_Ziel_FahrPr_NR "Anforderung Ziel-Fahrprogramm Niveaureglierung";
CM_ SG_ 1000 CHA_Ziel_FahrPr_QS "Anforderung Ziel-Fahrprogramm geregelte Hinterachsquersperre";
CM_ SG_ 1000 CHA_Ziel_FahrPr_SCU "Anforderung Ziel-Fahrprogramm SCU";
CM_ SG_ 1000 CHA_Ziel_FahrPr_WarnBrems "Anforderung Ziel-Fahrprogramm für Funktion Warn- und/oder Notbremsfunktion";

CM_ SG_ 1022 CHA_Current_Mode_BMA "Aktuell eingestellter Charisma Betriebsmodus";
CM_ SG_ 1022 CHA_Fahrer_Umschaltung "Die manuelle Umschaltung durch den Fahrer soll signalisiert werden, um zu automatischen Umschaltungen (z.B. Retries) differenzieren zu können.";
CM_ SG_ 1022 CHA_Fahrer_Umschaltung_BMA "Die manuelle Umschaltung der Betriebsmodusauswahl durch den Fahrer soll signalisiert werden, um zu automatischen Umschaltungen (z.B. Retries) differenzieren zu können.";
CM_ SG_ 1022 CHA_Ziel_FahrPr_AGK "Signal zur Ansteuerung des Teilnehmers Abgasklappen durch den Charisma-Koordinator über das Motor-SG";
CM_ SG_ 1022 CHA_Ziel_FahrPr_BMS "Anforderung Ziel-Fahrprogramm BMS (nähere Spezifikation siehe Charisma-LH PAG)";
CM_ SG_ 1022 CHA_Ziel_FahrPr_EDS "Anforderung Ziel-Fahrprogramm Elektronische Differentialsperre";
CM_ SG_ 1022 CHA_Ziel_FahrPr_HHC "Anforderung Ziel-Fahrprogramm Hill Hold Control";
CM_ SG_ 1022 CHA_Ziel_FahrPr_MO_Freilauf "Anforderung Ziel-Fahrprogramm Funktion Freilauf Motor aus";
CM_ SG_ 1022 CHA_Ziel_FahrPr_PACC "Anforderung Ziel-Fahrprogramm InnoDrive (PACCh)";
CM_ SG_ 1022 CHA_Ziel_FahrPr_PDC "Signal zur Ansteuerung des PDC/PLA durch den Charisma-Koordinator";
CM_ SG_ 1022 CHA_Ziel_FahrPr_Reku_ZwGas "Anforderung Ziel-Fahrprogramm für Rekuperation oder Zwischengas";

CM_ SG_ 615 Daempfer_02_CRC "Für MLB:
'Berechnung siehe Lastenheft 'Kommunikationsabsicherung für FlexRay und CAN''

Ab MQB und MLBevo:
'Berechnung siehe Lastenheft 'End-to-End Kommunikationsabsicherung''

Endwerte siehe Begleitdokument 'S-PDU Kennungsfolgen'";
CM_ SG_ 615 DR_Charisma_FahrPr "MLBevo: Aktuelles Fahrprogramm des Charisma-Teilnehmers (siehe Systemlastenheft Drive Select)
MQB: Istwert der Kennlinie (siehe Systemlastenheft MQB FPA)";
CM_ SG_ 615 DR_Charisma_Status "Charisma Systemstatus des Charisma-Teilnehmers

Wert 0x3 ist nur für Fahrzeuge ab MQB relevant";
CM_ SG_ 615 DR_DynAGL_Anf_Entkopplung "Nur PO44x
Dynamische Aggregatelagerung
Anforderung zusätzliche Entkopplung für Getriebelager";
CM_ SG_ 615 DR_DynAGL_Anf_im_Leerlauf "Nur PO44x
Anforderung zusätzliche Entkopplung des Motorlagers im Leerlauf";
CM_ SG_ 615 DR_ESP_Zuschaltung "Zwangsweise Aktivierung ESP-Funktionalität durch die Dämpferregelung, Anforderung erfolgt auch bei Passivtastung.";
CM_ SG_ 615 DR_Systemstatus "Bei Statusänderung wird der Soll-Zustand ausgegeben. Der Status beschreibt einen Parametersatz: Temporäre Änderung der Dämpfereinstellungen werden hier nicht abgebildet. 
";
CM_ SG_ 615 EFP_LstgBegr "Anzeige der aktuell maximal zur Verfuegung stehend Antriebsleistung bei Eingriff durch Bauteilschutz Bremse";
CM_ SG_ 615 EFP_Niveauzustand_Lift "Rückmeldung Niveauzustand Liftfunktionalität";
CM_ SG_ 615 EFP_Verfuegbarkeit_Lift "Verfuegbarkeit der Liftfunktionalitaet";
CM_ SG_ 615 EFP_Vorlaufzeit_Lift "Vorlaufzeit Heben für Smartlift";

CM_ SG_ 2549880614 DIA_AAU_Req_Data "Diagnose Request Flashen AAU";

CM_ SG_ 2550011686 DIA_AAU_Resp_Data "Diagnose Response Flashen AAU";

CM_ SG_ 2549880393 DIA_EVLS_Req_Data "Diagnose Request Flashen EVLS";

CM_ SG_ 2550011465 DIA_EVLS_Resp_Data "Diagnose Response Flashen EVLS";

CM_ SG_ 2549880347 DIA_Geblaese_Req_Data "Diagnose Request Flashen Geblaese";

CM_ SG_ 2550011419 DIA_Geblaese_Resp_Data "Diagnose Response Flashen Geblaese";

CM_ SG_ 2549880340 DIA_gLW_LM_L_Req_Data "Diagnosezugriff & Flashen Leistungsmodule für gleitende Leuchtweite ";

CM_ SG_ 2550011412 DIA_gLW_LM_L_Resp_Data "Diagnosezugriff & Flashen Leistungsmodule für gleitende Leuchtweite ";

CM_ SG_ 2549880341 DIA_gLW_LM_R_Req_Data "Diagnosezugriff & Flashen Leistungsmodule für gleitende Leuchtweite ";

CM_ SG_ 2550011413 DIA_gLW_LM_R_Resp_Data "Diagnosezugriff & Flashen Leistungsmodule für gleitende Leuchtweite ";

CM_ SG_ 2549880577 DIA_KBF_Req_Data "Diagnose Request Flashen KBF";

CM_ SG_ 2550011649 DIA_KBF_Resp_Data "Diagnose Response Flashen KBF";

CM_ SG_ 2549880639 DIA_KPV_Req_Data "Diagnosezugriff & Flashen Klimapanel vorne";

CM_ SG_ 2550011711 DIA_KPV_Resp_Data "Diagnosezugriff & Flashen Klimabedienteil vorne";

CM_ SG_ 2549880330 DIA_LED_LM_L_Req_Data "Diagnosezugriff & Flashen LED Leistungsmodule";

CM_ SG_ 2550011402 DIA_LED_LM_L_Resp_Data "Diagnosezugriff & Flashen LED Leistungsmodule";

CM_ SG_ 2549880331 DIA_LED_LM_R_Req_Data "Diagnosezugriff & Flashen LED Leistungsmodule";

CM_ SG_ 2550011403 DIA_LED_LM_R_Resp_Data "Diagnosezugriff & Flashen LED Leistungsmodule";

CM_ SG_ 2549880633 DIA_LIM_2_Req_Data "Diagnose Request Flashen LIM_2";

CM_ SG_ 2550011705 DIA_LIM_2_Resp_Data "Diagnose Response Flashen LIM_2";

CM_ SG_ 2549880350 DIA_LIM_Req_Data "Diagnose Request Flashen LIM";

CM_ SG_ 2550011422 DIA_LIM_Resp_Data "Diagnose Response Flashen LIM";

CM_ SG_ 2549880427 DIA_MXB_LM_L_Req_Data "Diagnosezugriff & Flashen Matrixbeam Leistungsmodule";

CM_ SG_ 2550011499 DIA_MXB_LM_L_Resp_Data "Diagnosezugriff & Flashen Matrixbeam Leistungsmodule";

CM_ SG_ 2549880428 DIA_MXB_LM_R_Req_Data "Diagnosezugriff & Flashen Matrixbeam Leistungsmodule";

CM_ SG_ 2550011500 DIA_MXB_LM_R_Resp_Data "Diagnosezugriff & Flashen Matrixbeam Leistungsmodule";

CM_ SG_ 2549880612 DIA_SWP_Req_Data "Diagnosezugriff & Flashen Automatic Transmission Fluid-Pumpe";

CM_ SG_ 2550011684 DIA_SWP_Resp_Data "Diagnosezugriff & Flashen Automatic Transmission Fluid-Pumpe";

CM_ SG_ 2549880324 DIA_UGDO_S_Req_Data "Diagnosezugriff & Flashen Garagentoröffner (Sender)";

CM_ SG_ 2550011396 DIA_UGDO_S_Resp_Data "Diagnosezugriff & Flashen Garagentoröffner (Sender)";

CM_ SG_ 2549880679 DIA_WiBli_L_Req "DK2F Flash Diagnosezugriff";

CM_ SG_ 2550011751 DIA_WiBli_L_Resp "DK2F Flash Diagnosezugriff";

CM_ SG_ 2549880680 DIA_WiBli_R_Req "DK2F Flash Diagnosezugriff";

CM_ SG_ 2550011752 DIA_WiBli_R_Resp "DK2F Flash Diagnosezugriff";

CM_ SG_ 2549880321 DIA_WWS_Req_Data "Diagnosezugriff & Flashen Wischwinkelsteuerung";

CM_ SG_ 2550011393 DIA_WWS_Resp_Data "Diagnosezugriff & Flashen Wischwinkelsteuerung";

CM_ SG_ 1714 DGN_Verlernzaehler "wrap around 254 --> 0";
CM_ SG_ 1714 KBI_Kilometerstand "Fehler wird ausgegeben, falls Kilometerstand nicht restaurierbar
";
CM_ SG_ 1714 UH_Minute "0x3C- 0x3f = Werte ungültig";
CM_ SG_ 1714 UH_Monat "0x0D, 0xF =  Werte ungültig
0x0E = Relatives Datum (nur VW)";
CM_ SG_ 1714 UH_Sekunde "0x3C- 0x3f = Werte ungültig";
CM_ SG_ 1714 UH_Stunde "0x18 - 0x1F = Werte ungültig";
CM_ SG_ 1714 UH_Tag "0x0: reserviert bei VW";
CM_ SG_ 1714 Uhrzeit_01_alt "
";

CM_ SG_ 1520 BCM1_Stellgroesse_Kl_58s "Rohwert Dimmpoti";
CM_ SG_ 1520 DI_Display_Nachtdesign "Für Displays sind oft  automatische Umschaltungen von Tag-/Nachtdesign vorgesehen.
Es gibt jedoch Zustände, an denen auch tagsüber das Abblendlicht eingeschaltet ist.
z.B. Dauerfahrlicht, Geschwindigkeitsabhängiges 'Licht-An-Bei-Autobahn', 'Regenlicht',";
CM_ SG_ 1520 DI_Fotosensor "Helligkeitswert Fotosensor
Für die Dimmung relevanter Wert zur Sensierung der Umgebungshelligkeit
Im Detail beschrieben im 'Funktionslastenheft Dimmung MQB'.";
CM_ SG_ 1520 DI_KL_58xd "Klemme 58xd Display- und Funktionsbeleuchtung
Mit der Klemme 58xd wird die Helligkeit der Display- und der Funktionsbeleuchtungen der Schalter gesteuert.
Im Detail beschrieben im 'Funktionslastenheft Dimmung MQB'.";
CM_ SG_ 1520 DI_KL_58xs "Suchbeleuchtung Schalter
EIN-AUS-Schaltalgorithmus der allgemeinen Schaltersuchbeleuchtung. 
Im Detail beschrieben im 'Funktionslastenheft Dimmung MQB'.
";
CM_ SG_ 1520 DI_KL_58xt "Timergesteuerte Suchbeleuchtung
Der EIN-AUS-Schaltalgorithmus für die vor- und nachlaufende Schaltersuchbeleuchtungen beim Ein- & Aussteigen; z.B.: Start/Stop-Taster.
Im Detail beschrieben im 'Funktionslastenheft Dimmung MQB'.";

CM_ SG_ 420 EA_01_BZ "EA Botschaftszähler
Botschaft asynchron geroutet. Zählerwert kann springen.";
CM_ SG_ 420 EA_01_CRC "Ab MQB und MLBevo:
'Berechnung siehe Lastenheft 'End-to-End Kommunikationsabsicherung''";
CM_ SG_ 420 EA_Anforderung_HMS "Emergency Assist Anforderung an HMS";
CM_ SG_ 420 EA_eCall_Anf "Emergency Assist Anforderung eCall";
CM_ SG_ 420 EA_Funktionsstatus "Emergency Assist Funktionsstatus";
CM_ SG_ 420 EA_Gurtstraffer_Anf "Emergency Assist Anforderung reversibler Gurtstraffer";
CM_ SG_ 420 EA_Parken_beibehalten_HMS "Anforderung um automatisches lösen der Parkbremse zu verhindern";
CM_ SG_ 420 EA_Sollbeschleunigung "Emergency Assist Beschleunigungsanforderung";
CM_ SG_ 420 EA_Warnruckprofil "Emergency Assist Anforderung an ESP, welcher Ruck verwendet werden soll.";

CM_ SG_ 496 ACF_Lampe_Hands_Off "Anzeige, ob der Fahrer die Hände am Lenkrad hat.";
CM_ SG_ 496 EA_02_BZ "Botschaftszähler
Botschaft asynchron geroutet. Zählerwert kann springen.";
CM_ SG_ 496 EA_02_CRC "Für MLB:
'Berechnung siehe Lastenheft 'Kommunikationsabsicherung für Flexray und CAN''

Ab MQB und MLBevo:
'Berechnung siehe Lastenheft 'End-to-End Kommunikationsabsicherung'

Endwerte siehe Begleitdokument 'S-PDU Kennungsfolge'";
CM_ SG_ 496 EA_Blinken "Emergency Assist Anforderung Blinker";
CM_ SG_ 496 EA_Bremslichtblinken "Die Funktion Emergency Alert fordert ein Blinken der Bremsleuchten an.";
CM_ SG_ 496 EA_Infotainment_Anf "Emergency Assist Anforderung Absenkung Infotainment-Funktionen";
CM_ SG_ 496 EA_Innenraumlicht_Anf "Anforderung Innenraumbeleuchtung durch den Emergency Assist";
CM_ SG_ 496 EA_Status_HMI "Anzeige Emergency Assist-Statusleuchte im Fahrerinformationsdisplay";
CM_ SG_ 496 EA_Texte "Anzeige der EA Texte";
CM_ SG_ 496 EA_Tueren_Anf "Emergency Assist Anforderung Türen entriegeln";
CM_ SG_ 496 STP_Primaeranz "Primäranzeige des Staupiloten";
CM_ SG_ 496 zFAS_Warnblinken "Anforderung Warnblinken durch zFAS Funktionen.";

CM_ SG_ 2527679980 bCall_active "1: Breakdown call is active
0: BreakdownCall is inactive";
CM_ SG_ 2527679980 eCall_Funktionsstatus "HMI-Aufruf im Kombi (Broadcast)
Fehlerfälle die im Kombi angezeigt werden können";
CM_ SG_ 2527679980 eCall_Funktionsstatus_02 "Erweiterung des Funktionsstatus für andere Funktionen
ACN aktiv, MEC aktiv
MEC = manual emergency call = maueller Notruf
ACN = automatic emergency call = automatischer Notruf";
CM_ SG_ 2527679980 eCall_Mute_Anf "Signalisiert die Aufforderungen alle Soundquellen im Fahrzeug während eines aktiven Notrufs zu muten";
CM_ SG_ 2527679980 eCall_Statuslicht_Farbe1 "Steuerung Statuslicht (Farbe1) für Funktionsrückmeldungen Emergency Call / SOS Hilferuf,
z.B. LED-Anzeige im Dachmodul.";
CM_ SG_ 2527679980 eCall_Statuslicht_Farbe2 "Steuerung Statuslicht (Farbe2) für Funktionsrückmeldungen Emergency Call / SOS Hilferuf,
z.B. LED-Anzeige im Dachmodul.";
CM_ SG_ 2527679980 eCall_Subscription "Anzeige 'Service Unsubscribed' im Kombi - Aktualisierte Namensgebung";

CM_ SG_ 1603 KBI_Einheit_Datum "Anzeigevariante des Datums";
CM_ SG_ 1603 KBI_Einheit_Druck "Einheit des Druckes";
CM_ SG_ 1603 KBI_Einheit_Masse "Einheit der Masse (Verwendung z.B. ASTA)";
CM_ SG_ 1603 KBI_Einheit_Sprache "Siehe BAP-Datenfestlegung UnitMaster";
CM_ SG_ 1603 KBI_Einheit_Streckenanz "Einheit der Streckenanzeige";
CM_ SG_ 1603 KBI_Einheit_Temp "Einheit der Temperatur";
CM_ SG_ 1603 KBI_Einheit_Uhrzeit "Anzeigevariante der Uhrzeit";
CM_ SG_ 1603 KBI_Einheit_Verbrauch "Einheit der Verbrauchs";
CM_ SG_ 1603 KBI_Einheit_Verbrauch_elektr "Einheit elektrischer Verbrauch";
CM_ SG_ 1603 KBI_Einheit_Verbrauch_Gas "Unterscheidung zwischen M3/h und kg/h für Komfortverbrauchsberechnung.";
CM_ SG_ 1603 KBI_Einheit_Volumen "Einheit des Volumens";
CM_ SG_ 1603 KBI_MFA_v_Einheit_02 "Einheit der Geschwindigkeit, die vom Fahrer im Car-Menü gewählt wurde. Veränderliche Grösse, im Gegensatz zur Einheit des Tachokranzes.

Redundant in der Einheiten_01 Botschaft definiert, um Konsistenz zur BAP-Festlegung zu haben.";

CM_ SG_ 260 EPB_01_BZ "Botschaft asynchron geroutet. Zählerwert kann springen.";
CM_ SG_ 260 EPB_01_CRC "Für MLB:
'Berechnung siehe Lastenheft 'Kommunikationsabsicherung für FlexRay und CAN''

Ab MQB und MLBevo:
'Berechnung siehe Lastenheft 'End-to-End Kommunikationsabsicherung''

Endwerte siehe Begleitdokument 'S-PDU Kennungsfolgen'";
CM_ SG_ 260 EPB_DAA_Randbed_erf "Die Randbedingungen zum automatischen Öffnen der EPB (Funktion DAA) sind erfüllt und ein Betätigen des Fahrpedals führt zum Öffnen der EPB.";
CM_ SG_ 260 EPB_Fehlerstatus_02 "Anpassung der Texte an die  aktuellen Zustände für weitergehende Funktionen (Stillstandsmanager)";
CM_ SG_ 260 EPB_Freig_Verzoeg_Anf "Verzögerungsanforderung	";
CM_ SG_ 260 EPB_Pedalweg_Kuppl "Signal entspricht Tastverhältnis des PWM. Gesamtweg Kupplungspedal 10% bis 90%, damit zu erwartende Werte 25 bis 225. 25 bei Kupplungspedal nicht getreten, 225 bei Kupplungspedal voll durchgetreten.
2% Toleranz wird im Wertebereich ermöglicht (8%-92%).
";
CM_ SG_ 260 EPB_Schalterposition "Spiegelt die Schalterstellung wieder.

0x3 = Schalterfehler ";
CM_ SG_ 260 EPB_Spannkraft "Erzeugte Spannkraft. Bezieht sich auf die Aktuatoren.

MQB: Spannkraftwerte entsprechen nicht den tatsächlichen Spannkräften. Genauere Informationen bitte in der Fachabteilung erfragen! ";
CM_ SG_ 260 EPB_Status_02 "Erweiterung der Zustände um ein genaueres Bild des aktuellen Zustandes zu erhalten für weitergehende Funktionen ( Stillstandsmanager)
";
CM_ SG_ 260 EPB_Verzoeg_Anf "Steuerungsanforderung an andere Systeme (z.B. ESP), um während der Fahrt, durch den Handbremsschalter ausgelöst, zu bremsen (ECD-Funktion)";
BA_DEF_REL_ BU_SG_REL_  "GenSigTimeoutTime" INT 0 65535;
BA_DEF_ BO_  "DiagRequest" ENUM "No", "Yes";
BA_DEF_ BO_  "DiagResponse" ENUM "No", "Yes";
BA_DEF_ BO_  "DiagState" ENUM "No", "Yes";
BA_DEF_ BO_  "GenMsgChkConstant" HEX 0 4095;
BA_DEF_ BO_  "GenMsgCycleTime" INT 0 65535;
BA_DEF_ BO_  "GenMsgCycleTimeFast" INT 0 65535;
BA_DEF_ BO_  "GenMsgDelayTime" INT 0 100000;
BA_DEF_ BO_  "GenMsgILSupport" ENUM "No", "Yes";
BA_DEF_ BO_  "GenMsgNrOfRepetition" INT 0 100;
BA_DEF_ BO_  "GenMsgPDUConstants" STRING;
BA_DEF_ BO_  "GenMsgSendType" ENUM "Cyclic", "not_used", "not_used", "not_used", "not_used", "not_used", "not_used", "IfActive", "NoMsgSendType";
BA_DEF_ BO_  "GenMsgStartDelayTime" INT 0 100000;
BA_DEF_ BO_  "NmMessage" ENUM "No", "Yes";
BA_DEF_ BO_  "NmhMessage" ENUM "No", "Yes";
BA_DEF_ BO_  "MsgType" ENUM "Application", "NM ", "NMH", "TP2.0", "ISO-TP ", "BAP", "EID", "KS", "XCP_PRE_CONFIGURED", "XCP_RUNTIME_CONFIGURED";
BA_DEF_ BO_  "VAGTP20_API" HEX 0 255;
BA_DEF_ BO_  "VAGTP20_DynConnection" ENUM "No", "Yes";
BA_DEF_ BO_  "VAGTP20_DynSetup" ENUM "No", "Yes";
BA_DEF_ BO_  "VAGTP20_StatConnection" ENUM "No", "Yes";
BA_DEF_ SG_  "GenSigActiveRepetitions" INT -2147483648 2147483647;
BA_DEF_ SG_  "GenSigInactiveValue" INT -2147483648 2147483647;
BA_DEF_ SG_  "GenSigSendType" ENUM "Cyclic", "OnWrite", "OnWriteWithRepetition", "OnChange", "OnChangeWithRepetition", "IfActive", "IfActiveWithRepetition", "NoSigSendType", "OnChangeAndIfActive", "OnChangeAndIfActiveWithRepetition";
BA_DEF_ SG_  "GenSigStartValue" INT -2147483648 2147483647;
BA_DEF_ SG_  "NWM-WakeupAllowed" ENUM "No", "Yes";
BA_DEF_ SG_  "GenSigFuncType" ENUM "NoFunction", "MsgCounter", "CRC-8", "XOR", "XOR-2", "DatedBit", "SW-Kl15", "CHK", "Constant", "Protocol", "CRC-8-SAE_J1850", "CRC-32", "DataLength", "DataID", "MsgCounter16", "SOK-Signatur", "Cluster";
BA_DEF_ SG_  "GenSigSwitchedByIgnition" ENUM "No", "Yes";
BA_DEF_ SG_  "Fehlerwert" HEX 0 2147483647;
BA_DEF_ SG_  "GenSigMissingSourceValue" HEX 0 2147483647;
BA_DEF_DEF_REL_  "GenSigTimeoutTime" 0;
BA_DEF_DEF_  "DiagRequest" "No";
BA_DEF_DEF_  "DiagResponse" "No";
BA_DEF_DEF_  "DiagState" "No";
BA_DEF_DEF_  "GenMsgChkConstant" 0;
BA_DEF_DEF_  "GenMsgCycleTime" 0;
BA_DEF_DEF_  "GenMsgCycleTimeFast" 0;
BA_DEF_DEF_  "GenMsgDelayTime" 0;
BA_DEF_DEF_  "GenMsgILSupport" "No";
BA_DEF_DEF_  "GenMsgNrOfRepetition" 0;
BA_DEF_DEF_  "GenMsgPDUConstants" "";
BA_DEF_DEF_  "GenMsgSendType" "NoMsgSendType";
BA_DEF_DEF_  "GenMsgStartDelayTime" 0;
BA_DEF_DEF_  "NmMessage" "No";
BA_DEF_DEF_  "NmhMessage" "No";
BA_DEF_DEF_  "MsgType" "Application";
BA_DEF_DEF_  "VAGTP20_API" 0;
BA_DEF_DEF_  "VAGTP20_DynConnection" "No";
BA_DEF_DEF_  "VAGTP20_DynSetup" "No";
BA_DEF_DEF_  "VAGTP20_StatConnection" "No";
BA_DEF_DEF_  "GenSigActiveRepetitions" 0;
BA_DEF_DEF_  "GenSigInactiveValue" 0;
BA_DEF_DEF_  "GenSigSendType" "NoSigSendType";
BA_DEF_DEF_  "GenSigStartValue" 0;
BA_DEF_DEF_  "NWM-WakeupAllowed" "No";
BA_DEF_DEF_  "GenSigFuncType" "NoFunction";
BA_DEF_DEF_  "GenSigSwitchedByIgnition" "Yes";
BA_DEF_DEF_  "Fehlerwert" 0;
BA_DEF_DEF_  "GenSigMissingSourceValue" 0;
BA_ "GenMsgCycleTime" BO_ 1448 500;
BA_ "GenMsgDelayTime" BO_ 1448 50;
BA_ "GenMsgILSupport" BO_ 1448 1;
BA_ "GenMsgSendType" BO_ 1448 0;
BA_ "GenMsgCycleTime" BO_ 961 200;
BA_ "GenMsgCycleTimeFast" BO_ 961 20;
BA_ "GenMsgDelayTime" BO_ 961 20;
BA_ "GenMsgILSupport" BO_ 961 1;
BA_ "GenMsgNrOfRepetition" BO_ 961 5;
BA_ "GenMsgSendType" BO_ 961 0;
BA_ "GenMsgCycleTime" BO_ 1432 1000;
BA_ "GenMsgCycleTimeFast" BO_ 1432 100;
BA_ "GenMsgDelayTime" BO_ 1432 50;
BA_ "GenMsgILSupport" BO_ 1432 1;
BA_ "GenMsgNrOfRepetition" BO_ 1432 5;
BA_ "GenMsgSendType" BO_ 1432 0;
BA_ "GenMsgCycleTime" BO_ 1431 500;
BA_ "GenMsgCycleTimeFast" BO_ 1431 50;
BA_ "GenMsgDelayTime" BO_ 1431 20;
BA_ "GenMsgILSupport" BO_ 1431 1;
BA_ "GenMsgNrOfRepetition" BO_ 1431 3;
BA_ "GenMsgSendType" BO_ 1431 0;
BA_ "GenMsgCycleTime" BO_ 870 1000;
BA_ "GenMsgCycleTimeFast" BO_ 870 50;
BA_ "GenMsgDelayTime" BO_ 870 10;
BA_ "GenMsgILSupport" BO_ 870 1;
BA_ "GenMsgNrOfRepetition" BO_ 870 5;
BA_ "GenMsgSendType" BO_ 870 0;
BA_ "GenMsgCycleTimeFast" BO_ 868 50;
BA_ "GenMsgDelayTime" BO_ 868 5;
BA_ "GenMsgILSupport" BO_ 868 1;
BA_ "GenMsgNrOfRepetition" BO_ 868 5;
BA_ "GenMsgSendType" BO_ 868 7;
BA_ "GenMsgCycleTime" BO_ 401 100;
BA_ "GenMsgILSupport" BO_ 401 1;
BA_ "GenMsgPDUConstants" BO_ 401 "0x7d,0x0e,0xaf,0x0b,0x24,0x58,0x88,0x9e,0x89,0x3a,0x81,0x61,0x4e,0xe3,0x04,0x1f";
BA_ "GenMsgSendType" BO_ 401 0;
BA_ "GenMsgCycleTime" BO_ 1442 500;
BA_ "GenMsgDelayTime" BO_ 1442 20;
BA_ "GenMsgILSupport" BO_ 1442 1;
BA_ "GenMsgPDUConstants" BO_ 1442 "0xeb,0x4c,0x44,0xaf,0x21,0x8d,0x01,0x58,0xfa,0x93,0xdb,0x89,0x15,0x10,0x4a,0x61";
BA_ "GenMsgSendType" BO_ 1442 0;
BA_ "GenMsgCycleTime" BO_ 1438 500;
BA_ "GenMsgILSupport" BO_ 1438 1;
BA_ "GenMsgSendType" BO_ 1438 0;
BA_ "GenMsgCycleTime" BO_ 2527679979 1000;
BA_ "GenMsgILSupport" BO_ 2527679979 1;
BA_ "GenMsgSendType" BO_ 2527679979 0;
BA_ "GenMsgCycleTime" BO_ 1289 100;
BA_ "GenMsgILSupport" BO_ 1289 1;
BA_ "GenMsgSendType" BO_ 1289 0;
BA_ "GenMsgCycleTime" BO_ 2527679654 2000;
BA_ "GenMsgILSupport" BO_ 2527679654 1;
BA_ "GenMsgPDUConstants" BO_ 2527679654 "0x79,0xb9,0x67,0xad,0xd5,0xf7,0x70,0xaa,0x44,0x61,0x5a,0xdc,0x26,0xb4,0xd2,0xc3";
BA_ "GenMsgSendType" BO_ 2527679654 0;
BA_ "GenMsgCycleTime" BO_ 2589283666 1000;
BA_ "GenMsgDelayTime" BO_ 2589283666 100;
BA_ "GenMsgILSupport" BO_ 2589283666 1;
BA_ "GenMsgSendType" BO_ 2589283666 0;
BA_ "GenMsgCycleTime" BO_ 2463978838 100;
BA_ "GenMsgILSupport" BO_ 2463978838 1;
BA_ "GenMsgSendType" BO_ 2463978838 0;
BA_ "MsgType" BO_ 2617128448 6;
BA_ "MsgType" BO_ 2617128449 6;
BA_ "MsgType" BO_ 2617167360 6;
BA_ "MsgType" BO_ 2617167361 6;
BA_ "GenMsgCycleTime" BO_ 901 1000;
BA_ "GenMsgDelayTime" BO_ 901 50;
BA_ "GenMsgILSupport" BO_ 901 1;
BA_ "GenMsgSendType" BO_ 901 0;
BA_ "GenMsgStartDelayTime" BO_ 901 50;
BA_ "GenMsgCycleTime" BO_ 902 1000;
BA_ "GenMsgILSupport" BO_ 902 1;
BA_ "GenMsgSendType" BO_ 902 0;
BA_ "GenMsgStartDelayTime" BO_ 902 50;
BA_ "GenMsgCycleTime" BO_ 1000 1000;
BA_ "GenMsgDelayTime" BO_ 1000 50;
BA_ "GenMsgILSupport" BO_ 1000 1;
BA_ "GenMsgSendType" BO_ 1000 0;
BA_ "GenMsgStartDelayTime" BO_ 1000 55;
BA_ "GenMsgCycleTime" BO_ 1022 1000;
BA_ "GenMsgDelayTime" BO_ 1022 50;
BA_ "GenMsgILSupport" BO_ 1022 1;
BA_ "GenMsgSendType" BO_ 1022 0;
BA_ "GenMsgStartDelayTime" BO_ 1022 50;
BA_ "GenMsgCycleTime" BO_ 615 80;
BA_ "GenMsgILSupport" BO_ 615 1;
BA_ "GenMsgPDUConstants" BO_ 615 "0xc7,0x7d,0x4c,0x0e,0x19,0xaf,0x2e,0x0b,0x8d,0x24,0x62,0x58,0x67,0x88,0x93,0x9e";
BA_ "GenMsgSendType" BO_ 615 0;
BA_ "MsgType" BO_ 2617012736 6;
BA_ "MsgType" BO_ 2617012991 6;
BA_ "MsgType" BO_ 2617037312 6;
BA_ "MsgType" BO_ 2617037567 6;
BA_ "MsgType" BO_ 2617127424 6;
BA_ "MsgType" BO_ 2617127679 6;
BA_ "MsgType" BO_ 2617166336 6;
BA_ "MsgType" BO_ 2617166337 6;
BA_ "MsgType" BO_ 2617166591 6;
BA_ "MsgType" BO_ 2617123584 6;
BA_ "MsgType" BO_ 2617123839 6;
BA_ "MsgType" BO_ 2617125632 6;
BA_ "MsgType" BO_ 2617125887 6;
BA_ "DiagRequest" BO_ 2549880614 1;
BA_ "MsgType" BO_ 2549880614 4;
BA_ "DiagResponse" BO_ 2550011686 1;
BA_ "MsgType" BO_ 2550011686 4;
BA_ "DiagRequest" BO_ 2549880393 1;
BA_ "MsgType" BO_ 2549880393 4;
BA_ "DiagResponse" BO_ 2550011465 1;
BA_ "MsgType" BO_ 2550011465 4;
BA_ "DiagRequest" BO_ 2549880347 1;
BA_ "MsgType" BO_ 2549880347 4;
BA_ "DiagResponse" BO_ 2550011419 1;
BA_ "MsgType" BO_ 2550011419 4;
BA_ "DiagRequest" BO_ 2549880340 1;
BA_ "MsgType" BO_ 2549880340 4;
BA_ "DiagResponse" BO_ 2550011412 1;
BA_ "MsgType" BO_ 2550011412 4;
BA_ "DiagRequest" BO_ 2549880341 1;
BA_ "MsgType" BO_ 2549880341 4;
BA_ "DiagResponse" BO_ 2550011413 1;
BA_ "MsgType" BO_ 2550011413 4;
BA_ "DiagRequest" BO_ 2549880577 1;
BA_ "MsgType" BO_ 2549880577 4;
BA_ "DiagResponse" BO_ 2550011649 1;
BA_ "MsgType" BO_ 2550011649 4;
BA_ "DiagRequest" BO_ 2549880639 1;
BA_ "MsgType" BO_ 2549880639 4;
BA_ "DiagResponse" BO_ 2550011711 1;
BA_ "MsgType" BO_ 2550011711 4;
BA_ "DiagRequest" BO_ 2549880330 1;
BA_ "MsgType" BO_ 2549880330 4;
BA_ "DiagResponse" BO_ 2550011402 1;
BA_ "MsgType" BO_ 2550011402 4;
BA_ "DiagRequest" BO_ 2549880331 1;
BA_ "MsgType" BO_ 2549880331 4;
BA_ "DiagResponse" BO_ 2550011403 1;
BA_ "MsgType" BO_ 2550011403 4;
BA_ "DiagRequest" BO_ 2549880633 1;
BA_ "MsgType" BO_ 2549880633 4;
BA_ "DiagResponse" BO_ 2550011705 1;
BA_ "MsgType" BO_ 2550011705 4;
BA_ "DiagRequest" BO_ 2549880350 1;
BA_ "MsgType" BO_ 2549880350 4;
BA_ "DiagResponse" BO_ 2550011422 1;
BA_ "MsgType" BO_ 2550011422 4;
BA_ "DiagRequest" BO_ 2549880427 1;
BA_ "MsgType" BO_ 2549880427 4;
BA_ "DiagResponse" BO_ 2550011499 1;
BA_ "MsgType" BO_ 2550011499 4;
BA_ "DiagRequest" BO_ 2549880428 1;
BA_ "MsgType" BO_ 2549880428 4;
BA_ "DiagResponse" BO_ 2550011500 1;
BA_ "MsgType" BO_ 2550011500 4;
BA_ "DiagRequest" BO_ 2549880612 1;
BA_ "MsgType" BO_ 2549880612 4;
BA_ "DiagResponse" BO_ 2550011684 1;
BA_ "MsgType" BO_ 2550011684 4;
BA_ "DiagRequest" BO_ 2549880324 1;
BA_ "MsgType" BO_ 2549880324 4;
BA_ "DiagResponse" BO_ 2550011396 1;
BA_ "MsgType" BO_ 2550011396 4;
BA_ "DiagRequest" BO_ 2549880679 1;
BA_ "MsgType" BO_ 2549880679 4;
BA_ "DiagResponse" BO_ 2550011751 1;
BA_ "MsgType" BO_ 2550011751 4;
BA_ "DiagRequest" BO_ 2549880680 1;
BA_ "MsgType" BO_ 2549880680 4;
BA_ "DiagResponse" BO_ 2550011752 1;
BA_ "MsgType" BO_ 2550011752 4;
BA_ "DiagRequest" BO_ 2549880321 1;
BA_ "MsgType" BO_ 2549880321 4;
BA_ "DiagResponse" BO_ 2550011393 1;
BA_ "MsgType" BO_ 2550011393 4;
BA_ "GenMsgCycleTime" BO_ 1714 1000;
BA_ "GenMsgILSupport" BO_ 1714 1;
BA_ "GenMsgSendType" BO_ 1714 0;
BA_ "GenMsgStartDelayTime" BO_ 1714 55;
BA_ "GenMsgCycleTime" BO_ 1520 200;
BA_ "GenMsgDelayTime" BO_ 1520 50;
BA_ "GenMsgILSupport" BO_ 1520 1;
BA_ "GenMsgSendType" BO_ 1520 0;
BA_ "GenMsgCycleTime" BO_ 420 500;
BA_ "GenMsgILSupport" BO_ 420 1;
BA_ "GenMsgPDUConstants" BO_ 420 "0x69,0xbb,0x54,0xe6,0x4e,0x46,0x8d,0x7b,0xea,0x87,0xe9,0xb3,0x63,0xce,0xf8,0xbf";
BA_ "GenMsgSendType" BO_ 420 0;
BA_ "GenMsgCycleTime" BO_ 496 50;
BA_ "GenMsgDelayTime" BO_ 496 20;
BA_ "GenMsgILSupport" BO_ 496 1;
BA_ "GenMsgPDUConstants" BO_ 496 "0x2f,0x3c,0x22,0x60,0x18,0xeb,0x63,0x76,0xc5,0x91,0x0f,0x27,0x34,0x04,0x7f,0x02";
BA_ "GenMsgSendType" BO_ 496 0;
BA_ "GenMsgCycleTime" BO_ 2527679980 500;
BA_ "GenMsgDelayTime" BO_ 2527679980 50;
BA_ "GenMsgILSupport" BO_ 2527679980 1;
BA_ "GenMsgSendType" BO_ 2527679980 0;
BA_ "GenMsgStartDelayTime" BO_ 2527679980 50;
BA_ "GenMsgCycleTime" BO_ 1603 1000;
BA_ "GenMsgDelayTime" BO_ 1603 100;
BA_ "GenMsgILSupport" BO_ 1603 1;
BA_ "GenMsgSendType" BO_ 1603 0;
BA_ "GenMsgChkConstant" BO_ 260 5;
BA_ "GenMsgCycleTime" BO_ 260 500;
BA_ "GenMsgDelayTime" BO_ 260 40;
BA_ "GenMsgILSupport" BO_ 260 1;
BA_ "GenMsgPDUConstants" BO_ 260 "0x05,0x05,0x05,0x05,0x05,0x05,0x05,0x05,0x05,0x05,0x05,0x05,0x05,0x05,0x05,0x05";
BA_ "GenMsgSendType" BO_ 260 0;
BA_ "GenSigSendType" SG_ 1448 BCM1_FlHz_BFS_PWM_A 3;
BA_ "GenSigSwitchedByIgnition" SG_ 1448 BCM1_FlHz_BFS_PWM_A 0;
BA_ "GenSigSendType" SG_ 1448 BCM1_FlHz_BFS_PWM_B 3;
BA_ "GenSigSwitchedByIgnition" SG_ 1448 BCM1_FlHz_BFS_PWM_B 0;
BA_ "GenSigSendType" SG_ 1448 BCM1_FlHz_HBFS_PWM_A 3;
BA_ "GenSigSwitchedByIgnition" SG_ 1448 BCM1_FlHz_HBFS_PWM_A 0;
BA_ "GenSigSendType" SG_ 1448 BCM1_FlHz_HBFS_PWM_B 3;
BA_ "GenSigSwitchedByIgnition" SG_ 1448 BCM1_FlHz_HBFS_PWM_B 0;
BA_ "GenSigSendType" SG_ 1448 BCM1_FlHz_HL_HLR_Anf 3;
BA_ "GenSigSwitchedByIgnition" SG_ 1448 BCM1_FlHz_HL_HLR_Anf 0;
BA_ "GenSigSendType" SG_ 1448 BCM1_FlHz_HR_HLR_Anf 3;
BA_ "GenSigSwitchedByIgnition" SG_ 1448 BCM1_FlHz_HR_HLR_Anf 0;
BA_ "GenSigSendType" SG_ 1448 BCM1_FlHz_Ruhesitz_HLR_Anf 3;
BA_ "GenSigSwitchedByIgnition" SG_ 1448 BCM1_FlHz_Ruhesitz_HLR_Anf 0;
BA_ "GenSigSendType" SG_ 1448 BCM1_FlHz_Stufe_HL 3;
BA_ "GenSigSwitchedByIgnition" SG_ 1448 BCM1_FlHz_Stufe_HL 0;
BA_ "GenSigSendType" SG_ 1448 BCM1_FlHz_Stufe_HR 3;
BA_ "GenSigSwitchedByIgnition" SG_ 1448 BCM1_FlHz_Stufe_HR 0;
BA_ "GenSigSendType" SG_ 1448 BCM1_FlHz_Stufe_VL 3;
BA_ "GenSigSwitchedByIgnition" SG_ 1448 BCM1_FlHz_Stufe_VL 0;
BA_ "GenSigSendType" SG_ 1448 BCM1_FlHz_Stufe_VR 3;
BA_ "GenSigSwitchedByIgnition" SG_ 1448 BCM1_FlHz_Stufe_VR 0;
BA_ "GenSigSendType" SG_ 1448 BCM1_FlHz_VL_HLR_Anf 3;
BA_ "GenSigSwitchedByIgnition" SG_ 1448 BCM1_FlHz_VL_HLR_Anf 0;
BA_ "GenSigSendType" SG_ 1448 BCM1_FlHz_VR_HLR_Anf 3;
BA_ "GenSigSwitchedByIgnition" SG_ 1448 BCM1_FlHz_VR_HLR_Anf 0;
BA_ "GenSigActiveRepetitions" SG_ 961 APS_LED_Status 5;
BA_ "GenSigSendType" SG_ 961 APS_LED_Status 4;
BA_ "GenSigSwitchedByIgnition" SG_ 961 APS_LED_Status 0;
BA_ "Fehlerwert" SG_ 961 APS_LED_Status 3;
BA_ "GenSigActiveRepetitions" SG_ 961 APS_Taster 5;
BA_ "GenSigSendType" SG_ 961 APS_Taster 4;
BA_ "GenSigStartValue" SG_ 961 APS_Taster 2;
BA_ "GenSigSwitchedByIgnition" SG_ 961 APS_Taster 0;
BA_ "Fehlerwert" SG_ 961 APS_Taster 3;
BA_ "GenSigActiveRepetitions" SG_ 961 AVH_LED_Status 5;
BA_ "GenSigSendType" SG_ 961 AVH_LED_Status 4;
BA_ "GenSigSwitchedByIgnition" SG_ 961 AVH_LED_Status 0;
BA_ "Fehlerwert" SG_ 961 AVH_LED_Status 3;
BA_ "GenSigActiveRepetitions" SG_ 961 AVH_Taster 5;
BA_ "GenSigSendType" SG_ 961 AVH_Taster 4;
BA_ "GenSigStartValue" SG_ 961 AVH_Taster 2;
BA_ "GenSigSwitchedByIgnition" SG_ 961 AVH_Taster 0;
BA_ "Fehlerwert" SG_ 961 AVH_Taster 3;
BA_ "GenSigActiveRepetitions" SG_ 961 Display_Taster 5;
BA_ "GenSigSendType" SG_ 961 Display_Taster 4;
BA_ "GenSigStartValue" SG_ 961 Display_Taster 2;
BA_ "GenSigSwitchedByIgnition" SG_ 961 Display_Taster 0;
BA_ "Fehlerwert" SG_ 961 Display_Taster 3;
BA_ "GenSigActiveRepetitions" SG_ 961 Drivesel_1_Taster 5;
BA_ "GenSigSendType" SG_ 961 Drivesel_1_Taster 4;
BA_ "GenSigStartValue" SG_ 961 Drivesel_1_Taster 2;
BA_ "GenSigSwitchedByIgnition" SG_ 961 Drivesel_1_Taster 0;
BA_ "Fehlerwert" SG_ 961 Drivesel_1_Taster 3;
BA_ "GenSigActiveRepetitions" SG_ 961 Drivesel_2_Taster 5;
BA_ "GenSigSendType" SG_ 961 Drivesel_2_Taster 4;
BA_ "GenSigStartValue" SG_ 961 Drivesel_2_Taster 2;
BA_ "GenSigSwitchedByIgnition" SG_ 961 Drivesel_2_Taster 0;
BA_ "Fehlerwert" SG_ 961 Drivesel_2_Taster 3;
BA_ "GenSigActiveRepetitions" SG_ 961 eCall_Taste 5;
BA_ "GenSigSendType" SG_ 961 eCall_Taste 4;
BA_ "GenSigSwitchedByIgnition" SG_ 961 eCall_Taste 0;
BA_ "Fehlerwert" SG_ 961 eCall_Taste 3;
BA_ "GenSigActiveRepetitions" SG_ 961 ESP_Off_Taster 5;
BA_ "GenSigSendType" SG_ 961 ESP_Off_Taster 4;
BA_ "GenSigStartValue" SG_ 961 ESP_Off_Taster 2;
BA_ "GenSigSwitchedByIgnition" SG_ 961 ESP_Off_Taster 0;
BA_ "Fehlerwert" SG_ 961 ESP_Off_Taster 3;
BA_ "GenSigActiveRepetitions" SG_ 961 HDC_LED_Status 5;
BA_ "GenSigSendType" SG_ 961 HDC_LED_Status 4;
BA_ "GenSigSwitchedByIgnition" SG_ 961 HDC_LED_Status 0;
BA_ "Fehlerwert" SG_ 961 HDC_LED_Status 3;
BA_ "GenSigActiveRepetitions" SG_ 961 HDC_Taster 5;
BA_ "GenSigSendType" SG_ 961 HDC_Taster 4;
BA_ "GenSigStartValue" SG_ 961 HDC_Taster 2;
BA_ "GenSigSwitchedByIgnition" SG_ 961 HDC_Taster 0;
BA_ "Fehlerwert" SG_ 961 HDC_Taster 3;
BA_ "GenSigActiveRepetitions" SG_ 961 Heckrollo_2_Taster 5;
BA_ "GenSigSendType" SG_ 961 Heckrollo_2_Taster 4;
BA_ "GenSigStartValue" SG_ 961 Heckrollo_2_Taster 2;
BA_ "GenSigSwitchedByIgnition" SG_ 961 Heckrollo_2_Taster 0;
BA_ "Fehlerwert" SG_ 961 Heckrollo_2_Taster 3;
BA_ "GenSigActiveRepetitions" SG_ 961 Heckrollo_Taster 5;
BA_ "GenSigSendType" SG_ 961 Heckrollo_Taster 4;
BA_ "GenSigStartValue" SG_ 961 Heckrollo_Taster 2;
BA_ "GenSigSwitchedByIgnition" SG_ 961 Heckrollo_Taster 0;
BA_ "Fehlerwert" SG_ 961 Heckrollo_Taster 3;
BA_ "GenSigActiveRepetitions" SG_ 961 LIM_bCall_Taster 5;
BA_ "GenSigSendType" SG_ 961 LIM_bCall_Taster 4;
BA_ "GenSigSwitchedByIgnition" SG_ 961 LIM_bCall_Taster 0;
BA_ "GenSigSendType" SG_ 961 LIM_PAO_Alivesignal 3;
BA_ "GenSigSwitchedByIgnition" SG_ 961 LIM_PAO_Alivesignal 0;
BA_ "GenSigSendType" SG_ 961 LIM_PAO_OFF_Status 3;
BA_ "GenSigSwitchedByIgnition" SG_ 961 LIM_PAO_OFF_Status 0;
BA_ "GenSigSendType" SG_ 961 LIM_PAO_ON_Status 3;
BA_ "GenSigSwitchedByIgnition" SG_ 961 LIM_PAO_ON_Status 0;
BA_ "GenSigSendType" SG_ 961 LIM_PAO_Schriftzug_Status 3;
BA_ "GenSigSwitchedByIgnition" SG_ 961 LIM_PAO_Schriftzug_Status 0;
BA_ "GenSigActiveRepetitions" SG_ 961 LKS_Taster 5;
BA_ "GenSigSendType" SG_ 961 LKS_Taster 4;
BA_ "GenSigStartValue" SG_ 961 LKS_Taster 2;
BA_ "GenSigSwitchedByIgnition" SG_ 961 LKS_Taster 0;
BA_ "Fehlerwert" SG_ 961 LKS_Taster 3;
BA_ "GenSigActiveRepetitions" SG_ 961 PLA_LED_Status 5;
BA_ "GenSigSendType" SG_ 961 PLA_LED_Status 4;
BA_ "GenSigSwitchedByIgnition" SG_ 961 PLA_LED_Status 0;
BA_ "Fehlerwert" SG_ 961 PLA_LED_Status 3;
BA_ "GenSigActiveRepetitions" SG_ 961 PLA_Taster 5;
BA_ "GenSigSendType" SG_ 961 PLA_Taster 4;
BA_ "GenSigStartValue" SG_ 961 PLA_Taster 2;
BA_ "GenSigSwitchedByIgnition" SG_ 961 PLA_Taster 0;
BA_ "Fehlerwert" SG_ 961 PLA_Taster 3;
BA_ "GenSigSendType" SG_ 961 PLA_Taster_Fehler_Roh 3;
BA_ "GenSigSwitchedByIgnition" SG_ 961 PLA_Taster_Fehler_Roh 0;
BA_ "GenSigActiveRepetitions" SG_ 961 Sideview_Taster 5;
BA_ "GenSigSendType" SG_ 961 Sideview_Taster 4;
BA_ "GenSigStartValue" SG_ 961 Sideview_Taster 2;
BA_ "GenSigSwitchedByIgnition" SG_ 961 Sideview_Taster 0;
BA_ "Fehlerwert" SG_ 961 Sideview_Taster 3;
BA_ "GenSigActiveRepetitions" SG_ 961 Spoiler_LED_Status 5;
BA_ "GenSigSendType" SG_ 961 Spoiler_LED_Status 4;
BA_ "GenSigSwitchedByIgnition" SG_ 961 Spoiler_LED_Status 0;
BA_ "Fehlerwert" SG_ 961 Spoiler_LED_Status 3;
BA_ "GenSigActiveRepetitions" SG_ 961 Spoiler_Taster 5;
BA_ "GenSigSendType" SG_ 961 Spoiler_Taster 4;
BA_ "GenSigStartValue" SG_ 961 Spoiler_Taster 2;
BA_ "GenSigSwitchedByIgnition" SG_ 961 Spoiler_Taster 0;
BA_ "Fehlerwert" SG_ 961 Spoiler_Taster 3;
BA_ "GenSigActiveRepetitions" SG_ 961 SWA_Taster 5;
BA_ "GenSigSendType" SG_ 961 SWA_Taster 4;
BA_ "GenSigSwitchedByIgnition" SG_ 961 SWA_Taster 0;
BA_ "Fehlerwert" SG_ 961 SWA_Taster 3;
BA_ "GenSigSendType" SG_ 1432 BCM1_eSound_Taster 3;
BA_ "GenSigStartValue" SG_ 1432 BCM1_eSound_Taster 2;
BA_ "GenSigSwitchedByIgnition" SG_ 1432 BCM1_eSound_Taster 0;
BA_ "Fehlerwert" SG_ 1432 BCM1_eSound_Taster 3;
BA_ "GenSigActiveRepetitions" SG_ 1432 BCM1_NR_Ride_Height_Down_Taster 5;
BA_ "GenSigSendType" SG_ 1432 BCM1_NR_Ride_Height_Down_Taster 4;
BA_ "GenSigStartValue" SG_ 1432 BCM1_NR_Ride_Height_Down_Taster 2;
BA_ "GenSigSwitchedByIgnition" SG_ 1432 BCM1_NR_Ride_Height_Down_Taster 0;
BA_ "Fehlerwert" SG_ 1432 BCM1_NR_Ride_Height_Down_Taster 3;
BA_ "GenSigActiveRepetitions" SG_ 1432 BCM1_NR_Ride_Height_Up_Taster 5;
BA_ "GenSigSendType" SG_ 1432 BCM1_NR_Ride_Height_Up_Taster 4;
BA_ "GenSigStartValue" SG_ 1432 BCM1_NR_Ride_Height_Up_Taster 2;
BA_ "GenSigSwitchedByIgnition" SG_ 1432 BCM1_NR_Ride_Height_Up_Taster 0;
BA_ "Fehlerwert" SG_ 1432 BCM1_NR_Ride_Height_Up_Taster 3;
BA_ "GenSigSendType" SG_ 1432 BCM_BFS_Fernsteuerung_aktiv 3;
BA_ "GenSigSwitchedByIgnition" SG_ 1432 BCM_BFS_Fernsteuerung_aktiv 0;
BA_ "GenSigSendType" SG_ 1432 BCM_BFS_Massage_Taster 3;
BA_ "GenSigSwitchedByIgnition" SG_ 1432 BCM_BFS_Massage_Taster 0;
BA_ "GenSigSendType" SG_ 1432 BCM_BFS_Multif_Taster 3;
BA_ "GenSigSwitchedByIgnition" SG_ 1432 BCM_BFS_Multif_Taster 0;
BA_ "GenSigSendType" SG_ 1432 BCM_BFS_Pneumatik_Verstellung 3;
BA_ "GenSigSwitchedByIgnition" SG_ 1432 BCM_BFS_Pneumatik_Verstellung 0;
BA_ "GenSigSendType" SG_ 1432 BCM_BFS_Programmwippe 3;
BA_ "GenSigSwitchedByIgnition" SG_ 1432 BCM_BFS_Programmwippe 0;
BA_ "GenSigSendType" SG_ 1432 BCM_FS_Massage_Taster 3;
BA_ "GenSigSwitchedByIgnition" SG_ 1432 BCM_FS_Massage_Taster 0;
BA_ "GenSigSendType" SG_ 1432 BCM_FS_Multif_Taster 3;
BA_ "GenSigSwitchedByIgnition" SG_ 1432 BCM_FS_Multif_Taster 0;
BA_ "GenSigSendType" SG_ 1432 BCM_FS_Pneumatik_Verstellung 3;
BA_ "GenSigSwitchedByIgnition" SG_ 1432 BCM_FS_Pneumatik_Verstellung 0;
BA_ "GenSigSendType" SG_ 1432 BCM_FS_Programmwippe 3;
BA_ "GenSigSwitchedByIgnition" SG_ 1432 BCM_FS_Programmwippe 0;
BA_ "GenSigActiveRepetitions" SG_ 1432 BCM_Soundklappe_Taster 5;
BA_ "GenSigSendType" SG_ 1432 BCM_Soundklappe_Taster 4;
BA_ "GenSigSwitchedByIgnition" SG_ 1432 BCM_Soundklappe_Taster 0;
BA_ "GenSigSendType" SG_ 1432 E_Sound_LED_Status 3;
BA_ "GenSigSwitchedByIgnition" SG_ 1432 E_Sound_LED_Status 0;
BA_ "Fehlerwert" SG_ 1432 E_Sound_LED_Status 3;
BA_ "GenSigActiveRepetitions" SG_ 1432 LIM_Rear_Mode 5;
BA_ "GenSigSendType" SG_ 1432 LIM_Rear_Mode 4;
BA_ "GenSigSwitchedByIgnition" SG_ 1432 LIM_Rear_Mode 0;
BA_ "GenSigActiveRepetitions" SG_ 1432 LIM_S_Rollo_hi 5;
BA_ "GenSigSendType" SG_ 1432 LIM_S_Rollo_hi 4;
BA_ "GenSigSwitchedByIgnition" SG_ 1432 LIM_S_Rollo_hi 0;
BA_ "GenSigActiveRepetitions" SG_ 1432 LIM_S_Rollo_vo 5;
BA_ "GenSigSendType" SG_ 1432 LIM_S_Rollo_vo 4;
BA_ "GenSigSwitchedByIgnition" SG_ 1432 LIM_S_Rollo_vo 0;
BA_ "GenSigActiveRepetitions" SG_ 1432 LIM_S_SAD_hi 5;
BA_ "GenSigSendType" SG_ 1432 LIM_S_SAD_hi 4;
BA_ "GenSigSwitchedByIgnition" SG_ 1432 LIM_S_SAD_hi 0;
BA_ "GenSigActiveRepetitions" SG_ 1432 LIM_S_SAD_Vo 5;
BA_ "GenSigSendType" SG_ 1432 LIM_S_SAD_Vo 4;
BA_ "GenSigSwitchedByIgnition" SG_ 1432 LIM_S_SAD_Vo 0;
BA_ "GenSigSendType" SG_ 1432 Pilot_Taster 3;
BA_ "GenSigStartValue" SG_ 1432 Pilot_Taster 2;
BA_ "GenSigSwitchedByIgnition" SG_ 1432 Pilot_Taster 0;
BA_ "Fehlerwert" SG_ 1432 Pilot_Taster 3;
BA_ "GenSigActiveRepetitions" SG_ 1431 BED_Rollo_vo 3;
BA_ "GenSigSendType" SG_ 1431 BED_Rollo_vo 4;
BA_ "GenSigSwitchedByIgnition" SG_ 1431 BED_Rollo_vo 0;
BA_ "GenSigActiveRepetitions" SG_ 1431 BED_SAD_vo 3;
BA_ "GenSigSendType" SG_ 1431 BED_SAD_vo 4;
BA_ "GenSigSwitchedByIgnition" SG_ 1431 BED_SAD_vo 0;
BA_ "GenSigActiveRepetitions" SG_ 1431 BED_Taster_Fahrwerk 3;
BA_ "GenSigSendType" SG_ 1431 BED_Taster_Fahrwerk 4;
BA_ "GenSigSwitchedByIgnition" SG_ 1431 BED_Taster_Fahrwerk 0;
BA_ "GenSigActiveRepetitions" SG_ 1431 BED_Taster_Lift 3;
BA_ "GenSigSendType" SG_ 1431 BED_Taster_Lift 4;
BA_ "GenSigStartValue" SG_ 1431 BED_Taster_Lift 2;
BA_ "GenSigSwitchedByIgnition" SG_ 1431 BED_Taster_Lift 0;
BA_ "Fehlerwert" SG_ 1431 BED_Taster_Lift 3;
BA_ "GenSigActiveRepetitions" SG_ 1431 BED_Taster_VD_Oeffnen 3;
BA_ "GenSigSendType" SG_ 1431 BED_Taster_VD_Oeffnen 4;
BA_ "GenSigStartValue" SG_ 1431 BED_Taster_VD_Oeffnen 2;
BA_ "GenSigSwitchedByIgnition" SG_ 1431 BED_Taster_VD_Oeffnen 0;
BA_ "Fehlerwert" SG_ 1431 BED_Taster_VD_Oeffnen 3;
BA_ "GenSigActiveRepetitions" SG_ 1431 BED_Taster_VD_Schliessen 3;
BA_ "GenSigSendType" SG_ 1431 BED_Taster_VD_Schliessen 4;
BA_ "GenSigStartValue" SG_ 1431 BED_Taster_VD_Schliessen 2;
BA_ "GenSigSwitchedByIgnition" SG_ 1431 BED_Taster_VD_Schliessen 0;
BA_ "Fehlerwert" SG_ 1431 BED_Taster_VD_Schliessen 3;
BA_ "GenSigActiveRepetitions" SG_ 1431 BED_Taster_Windschott 3;
BA_ "GenSigSendType" SG_ 1431 BED_Taster_Windschott 4;
BA_ "GenSigStartValue" SG_ 1431 BED_Taster_Windschott 2;
BA_ "GenSigSwitchedByIgnition" SG_ 1431 BED_Taster_Windschott 0;
BA_ "Fehlerwert" SG_ 1431 BED_Taster_Windschott 3;
BA_ "GenSigSendType" SG_ 1431 SoSe_SunInt_2D_Li_Dash 0;
BA_ "GenSigStartValue" SG_ 1431 SoSe_SunInt_2D_Li_Dash 254;
BA_ "GenSigSwitchedByIgnition" SG_ 1431 SoSe_SunInt_2D_Li_Dash 0;
BA_ "Fehlerwert" SG_ 1431 SoSe_SunInt_2D_Li_Dash 255;
BA_ "GenSigSendType" SG_ 1431 SoSe_SunInt_2D_Re_Dash 0;
BA_ "GenSigStartValue" SG_ 1431 SoSe_SunInt_2D_Re_Dash 254;
BA_ "GenSigSwitchedByIgnition" SG_ 1431 SoSe_SunInt_2D_Re_Dash 0;
BA_ "Fehlerwert" SG_ 1431 SoSe_SunInt_2D_Re_Dash 255;
BA_ "GenSigActiveRepetitions" SG_ 870 Blinken_li_Fzg_Takt 5;
BA_ "GenSigSendType" SG_ 870 Blinken_li_Fzg_Takt 4;
BA_ "GenSigSwitchedByIgnition" SG_ 870 Blinken_li_Fzg_Takt 0;
BA_ "GenSigActiveRepetitions" SG_ 870 Blinken_li_Kombi_Takt 5;
BA_ "GenSigSendType" SG_ 870 Blinken_li_Kombi_Takt 4;
BA_ "GenSigSwitchedByIgnition" SG_ 870 Blinken_li_Kombi_Takt 0;
BA_ "GenSigActiveRepetitions" SG_ 870 Blinken_re_Fzg_Takt 5;
BA_ "GenSigSendType" SG_ 870 Blinken_re_Fzg_Takt 4;
BA_ "GenSigSwitchedByIgnition" SG_ 870 Blinken_re_Fzg_Takt 0;
BA_ "GenSigActiveRepetitions" SG_ 870 Blinken_re_Kombi_Takt 5;
BA_ "GenSigSendType" SG_ 870 Blinken_re_Kombi_Takt 4;
BA_ "GenSigSwitchedByIgnition" SG_ 870 Blinken_re_Kombi_Takt 0;
BA_ "GenSigActiveRepetitions" SG_ 870 BM_Autobahn 5;
BA_ "GenSigSendType" SG_ 870 BM_Autobahn 4;
BA_ "GenSigSwitchedByIgnition" SG_ 870 BM_Autobahn 0;
BA_ "GenSigActiveRepetitions" SG_ 870 BM_Crash 5;
BA_ "GenSigSendType" SG_ 870 BM_Crash 4;
BA_ "GenSigSwitchedByIgnition" SG_ 870 BM_Crash 0;
BA_ "GenSigActiveRepetitions" SG_ 870 BM_DWA_Alarm 5;
BA_ "GenSigSendType" SG_ 870 BM_DWA_Alarm 4;
BA_ "GenSigSwitchedByIgnition" SG_ 870 BM_DWA_Alarm 0;
BA_ "GenSigActiveRepetitions" SG_ 870 BM_DWA_ein 5;
BA_ "GenSigSendType" SG_ 870 BM_DWA_ein 4;
BA_ "GenSigSwitchedByIgnition" SG_ 870 BM_DWA_ein 0;
BA_ "GenSigActiveRepetitions" SG_ 870 BM_GDO 5;
BA_ "GenSigSendType" SG_ 870 BM_GDO 4;
BA_ "GenSigSwitchedByIgnition" SG_ 870 BM_GDO 0;
BA_ "GenSigActiveRepetitions" SG_ 870 BM_HD_Oeffnung_angelernt 5;
BA_ "GenSigSendType" SG_ 870 BM_HD_Oeffnung_angelernt 4;
BA_ "GenSigSwitchedByIgnition" SG_ 870 BM_HD_Oeffnung_angelernt 0;
BA_ "GenSigActiveRepetitions" SG_ 870 BM_links 5;
BA_ "GenSigSendType" SG_ 870 BM_links 4;
BA_ "GenSigSwitchedByIgnition" SG_ 870 BM_links 0;
BA_ "GenSigActiveRepetitions" SG_ 870 BM_NBA_n_codiert_n_aktiv 5;
BA_ "GenSigSendType" SG_ 870 BM_NBA_n_codiert_n_aktiv 4;
BA_ "GenSigStartValue" SG_ 870 BM_NBA_n_codiert_n_aktiv 1;
BA_ "GenSigSwitchedByIgnition" SG_ 870 BM_NBA_n_codiert_n_aktiv 0;
BA_ "GenSigActiveRepetitions" SG_ 870 BM_NBA_Status 5;
BA_ "GenSigSendType" SG_ 870 BM_NBA_Status 4;
BA_ "GenSigSwitchedByIgnition" SG_ 870 BM_NBA_Status 0;
BA_ "GenSigActiveRepetitions" SG_ 870 BM_Not_Bremsung 5;
BA_ "GenSigSendType" SG_ 870 BM_Not_Bremsung 4;
BA_ "GenSigSwitchedByIgnition" SG_ 870 BM_Not_Bremsung 0;
BA_ "GenSigActiveRepetitions" SG_ 870 BM_Panik 5;
BA_ "GenSigSendType" SG_ 870 BM_Panik 4;
BA_ "GenSigSwitchedByIgnition" SG_ 870 BM_Panik 0;
BA_ "GenSigActiveRepetitions" SG_ 870 BM_PiloPa 5;
BA_ "GenSigSendType" SG_ 870 BM_PiloPa 4;
BA_ "GenSigSwitchedByIgnition" SG_ 870 BM_PiloPa 0;
BA_ "GenSigActiveRepetitions" SG_ 870 BM_Recas 5;
BA_ "GenSigSendType" SG_ 870 BM_Recas 4;
BA_ "GenSigSwitchedByIgnition" SG_ 870 BM_Recas 0;
BA_ "GenSigActiveRepetitions" SG_ 870 BM_rechts 5;
BA_ "GenSigSendType" SG_ 870 BM_rechts 4;
BA_ "GenSigSwitchedByIgnition" SG_ 870 BM_rechts 0;
BA_ "GenSigActiveRepetitions" SG_ 870 BM_Rollenmodus_Blinken 5;
BA_ "GenSigSendType" SG_ 870 BM_Rollenmodus_Blinken 4;
BA_ "GenSigSwitchedByIgnition" SG_ 870 BM_Rollenmodus_Blinken 0;
BA_ "GenSigActiveRepetitions" SG_ 870 BM_Taxi_Notalarm 5;
BA_ "GenSigSendType" SG_ 870 BM_Taxi_Notalarm 4;
BA_ "GenSigSwitchedByIgnition" SG_ 870 BM_Taxi_Notalarm 0;
BA_ "GenSigActiveRepetitions" SG_ 870 BM_Telematik 5;
BA_ "GenSigSendType" SG_ 870 BM_Telematik 4;
BA_ "GenSigSwitchedByIgnition" SG_ 870 BM_Telematik 0;
BA_ "GenSigActiveRepetitions" SG_ 870 BM_Telematik_Abbruchgrund 5;
BA_ "GenSigSendType" SG_ 870 BM_Telematik_Abbruchgrund 4;
BA_ "GenSigSwitchedByIgnition" SG_ 870 BM_Telematik_Abbruchgrund 0;
BA_ "GenSigActiveRepetitions" SG_ 870 BM_Warnblinken 5;
BA_ "GenSigSendType" SG_ 870 BM_Warnblinken 4;
BA_ "GenSigSwitchedByIgnition" SG_ 870 BM_Warnblinken 0;
BA_ "GenSigActiveRepetitions" SG_ 870 BM_WBT_Beleuchtung 5;
BA_ "GenSigSendType" SG_ 870 BM_WBT_Beleuchtung 4;
BA_ "GenSigSwitchedByIgnition" SG_ 870 BM_WBT_Beleuchtung 0;
BA_ "GenSigActiveRepetitions" SG_ 870 BM_Wischblinken 5;
BA_ "GenSigSendType" SG_ 870 BM_Wischblinken 4;
BA_ "GenSigSwitchedByIgnition" SG_ 870 BM_Wischblinken 0;
BA_ "GenSigActiveRepetitions" SG_ 870 BM_ZV_auf 5;
BA_ "GenSigSendType" SG_ 870 BM_ZV_auf 4;
BA_ "GenSigSwitchedByIgnition" SG_ 870 BM_ZV_auf 0;
BA_ "GenSigActiveRepetitions" SG_ 870 BM_ZV_zu 5;
BA_ "GenSigSendType" SG_ 870 BM_ZV_zu 4;
BA_ "GenSigSwitchedByIgnition" SG_ 870 BM_ZV_zu 0;
BA_ "GenSigSendType" SG_ 870 DWA_Alarmquelle 3;
BA_ "GenSigStartValue" SG_ 870 DWA_Alarmquelle 30;
BA_ "GenSigSwitchedByIgnition" SG_ 870 DWA_Alarmquelle 0;
BA_ "Fehlerwert" SG_ 870 DWA_Alarmquelle 31;
BA_ "GenSigActiveRepetitions" SG_ 868 NBlinken_li_Fzg_Takt 5;
BA_ "GenSigSendType" SG_ 868 NBlinken_li_Fzg_Takt 6;
BA_ "GenSigSwitchedByIgnition" SG_ 868 NBlinken_li_Fzg_Takt 0;
BA_ "GenSigActiveRepetitions" SG_ 868 NBlinken_li_Kombi_Takt 5;
BA_ "GenSigSendType" SG_ 868 NBlinken_li_Kombi_Takt 6;
BA_ "GenSigSwitchedByIgnition" SG_ 868 NBlinken_li_Kombi_Takt 0;
BA_ "GenSigActiveRepetitions" SG_ 868 NBlinken_re_Fzg_Takt 5;
BA_ "GenSigSendType" SG_ 868 NBlinken_re_Fzg_Takt 6;
BA_ "GenSigSwitchedByIgnition" SG_ 868 NBlinken_re_Fzg_Takt 0;
BA_ "GenSigActiveRepetitions" SG_ 868 NBlinken_re_Kombi_Takt 5;
BA_ "GenSigSendType" SG_ 868 NBlinken_re_Kombi_Takt 6;
BA_ "GenSigSwitchedByIgnition" SG_ 868 NBlinken_re_Kombi_Takt 0;
BA_ "GenSigSendType" SG_ 401 BMS_01_BZ 0;
BA_ "GenSigFuncType" SG_ 401 BMS_01_BZ 1;
BA_ "GenSigSwitchedByIgnition" SG_ 401 BMS_01_BZ 0;
BA_ "GenSigSendType" SG_ 401 BMS_01_CRC 0;
BA_ "GenSigFuncType" SG_ 401 BMS_01_CRC 2;
BA_ "GenSigSwitchedByIgnition" SG_ 401 BMS_01_CRC 0;
BA_ "GenSigSendType" SG_ 401 BMS_IstSpannung 0;
BA_ "GenSigStartValue" SG_ 401 BMS_IstSpannung 4094;
BA_ "GenSigSwitchedByIgnition" SG_ 401 BMS_IstSpannung 0;
BA_ "Fehlerwert" SG_ 401 BMS_IstSpannung 4095;
BA_ "GenSigSendType" SG_ 401 BMS_IstStrom_02 0;
BA_ "GenSigStartValue" SG_ 401 BMS_IstStrom_02 4094;
BA_ "GenSigSwitchedByIgnition" SG_ 401 BMS_IstStrom_02 0;
BA_ "Fehlerwert" SG_ 401 BMS_IstStrom_02 4095;
BA_ "GenSigSendType" SG_ 401 BMS_IstStrom_02_Offset 0;
BA_ "GenSigSwitchedByIgnition" SG_ 401 BMS_IstStrom_02_Offset 0;
BA_ "GenSigSendType" SG_ 401 BMS_IstStrom_02_OffsetVZ 0;
BA_ "GenSigSwitchedByIgnition" SG_ 401 BMS_IstStrom_02_OffsetVZ 0;
BA_ "GenSigSendType" SG_ 401 BMS_SOC_HiRes 0;
BA_ "GenSigStartValue" SG_ 401 BMS_SOC_HiRes 2046;
BA_ "GenSigSwitchedByIgnition" SG_ 401 BMS_SOC_HiRes 0;
BA_ "Fehlerwert" SG_ 401 BMS_SOC_HiRes 2047;
BA_ "GenSigSendType" SG_ 401 BMS_Spannung_ZwKr 0;
BA_ "GenSigStartValue" SG_ 401 BMS_Spannung_ZwKr 2046;
BA_ "GenSigSwitchedByIgnition" SG_ 401 BMS_Spannung_ZwKr 0;
BA_ "Fehlerwert" SG_ 401 BMS_Spannung_ZwKr 2047;
BA_ "GenSigSendType" SG_ 1442 BMS_04_BZ 0;
BA_ "GenSigFuncType" SG_ 1442 BMS_04_BZ 1;
BA_ "GenSigSwitchedByIgnition" SG_ 1442 BMS_04_BZ 0;
BA_ "GenSigSendType" SG_ 1442 BMS_04_CRC 0;
BA_ "GenSigFuncType" SG_ 1442 BMS_04_CRC 2;
BA_ "GenSigSwitchedByIgnition" SG_ 1442 BMS_04_CRC 0;
BA_ "GenSigSendType" SG_ 1442 BMS_Abschaltankuendigung 0;
BA_ "GenSigStartValue" SG_ 1442 BMS_Abschaltankuendigung 1022;
BA_ "Fehlerwert" SG_ 1442 BMS_Abschaltankuendigung 1023;
BA_ "GenSigSendType" SG_ 1442 BMS_Fehlerstatus 3;
BA_ "GenSigStartValue" SG_ 1442 BMS_Fehlerstatus 7;
BA_ "GenSigSwitchedByIgnition" SG_ 1442 BMS_Fehlerstatus 0;
BA_ "GenSigSendType" SG_ 1442 BMS_IstModus 3;
BA_ "GenSigStartValue" SG_ 1442 BMS_IstModus 7;
BA_ "GenSigSwitchedByIgnition" SG_ 1442 BMS_IstModus 0;
BA_ "GenSigSendType" SG_ 1442 BMS_Kapazitaet_02 0;
BA_ "GenSigStartValue" SG_ 1442 BMS_Kapazitaet_02 2047;
BA_ "GenSigSwitchedByIgnition" SG_ 1442 BMS_Kapazitaet_02 0;
BA_ "GenSigSendType" SG_ 1442 BMS_OBD_Lampe_Anf 0;
BA_ "GenSigSwitchedByIgnition" SG_ 1442 BMS_OBD_Lampe_Anf 0;
BA_ "GenSigSendType" SG_ 1442 BMS_Soll_SOC_HiRes 3;
BA_ "GenSigStartValue" SG_ 1442 BMS_Soll_SOC_HiRes 2046;
BA_ "GenSigSwitchedByIgnition" SG_ 1442 BMS_Soll_SOC_HiRes 0;
BA_ "Fehlerwert" SG_ 1442 BMS_Soll_SOC_HiRes 2047;
BA_ "GenSigSendType" SG_ 1442 BMS_Status_ServiceDisconnect 0;
BA_ "GenSigSwitchedByIgnition" SG_ 1442 BMS_Status_ServiceDisconnect 0;
BA_ "GenSigSendType" SG_ 1442 BMS_Status_Spgfreiheit 0;
BA_ "GenSigSwitchedByIgnition" SG_ 1442 BMS_Status_Spgfreiheit 0;
BA_ "GenSigSendType" SG_ 1438 BMS_Batterie_Voko_Anf 0;
BA_ "GenSigSwitchedByIgnition" SG_ 1438 BMS_Batterie_Voko_Anf 0;
BA_ "GenSigSendType" SG_ 1438 BMS_Fehler_NTKreis 0;
BA_ "GenSigSwitchedByIgnition" SG_ 1438 BMS_Fehler_NTKreis 0;
BA_ "Fehlerwert" SG_ 1438 BMS_Fehler_NTKreis 1;
BA_ "GenSigSendType" SG_ 1438 BMS_Fehlerstatus_EWP_02 0;
BA_ "GenSigSwitchedByIgnition" SG_ 1438 BMS_Fehlerstatus_EWP_02 0;
BA_ "Fehlerwert" SG_ 1438 BMS_Fehlerstatus_EWP_02 7;
BA_ "GenSigSendType" SG_ 1438 BMS_IstRuecklaufTemperatur_02 0;
BA_ "GenSigStartValue" SG_ 1438 BMS_IstRuecklaufTemperatur_02 254;
BA_ "GenSigSwitchedByIgnition" SG_ 1438 BMS_IstRuecklaufTemperatur_02 0;
BA_ "Fehlerwert" SG_ 1438 BMS_IstRuecklaufTemperatur_02 255;
BA_ "GenSigSendType" SG_ 1438 BMS_IstVorlaufTemperatur 0;
BA_ "GenSigStartValue" SG_ 1438 BMS_IstVorlaufTemperatur 254;
BA_ "GenSigSwitchedByIgnition" SG_ 1438 BMS_IstVorlaufTemperatur 0;
BA_ "Fehlerwert" SG_ 1438 BMS_IstVorlaufTemperatur 255;
BA_ "GenSigSendType" SG_ 1438 BMS_Soll_PWM_Pumpe 0;
BA_ "GenSigStartValue" SG_ 1438 BMS_Soll_PWM_Pumpe 15;
BA_ "GenSigSwitchedByIgnition" SG_ 1438 BMS_Soll_PWM_Pumpe 0;
BA_ "Fehlerwert" SG_ 1438 BMS_Soll_PWM_Pumpe 14;
BA_ "GenSigSendType" SG_ 1438 BMS_SollVolumenstrom 0;
BA_ "GenSigStartValue" SG_ 1438 BMS_SollVolumenstrom 62;
BA_ "GenSigSwitchedByIgnition" SG_ 1438 BMS_SollVolumenstrom 0;
BA_ "Fehlerwert" SG_ 1438 BMS_SollVolumenstrom 63;
BA_ "GenSigSendType" SG_ 1438 BMS_SollVorlauftemperatur 0;
BA_ "GenSigStartValue" SG_ 1438 BMS_SollVorlauftemperatur 254;
BA_ "GenSigSwitchedByIgnition" SG_ 1438 BMS_SollVorlauftemperatur 0;
BA_ "Fehlerwert" SG_ 1438 BMS_SollVorlauftemperatur 255;
BA_ "GenSigSendType" SG_ 1438 BMS_Status_Ventil 0;
BA_ "GenSigStartValue" SG_ 1438 BMS_Status_Ventil 6;
BA_ "GenSigSwitchedByIgnition" SG_ 1438 BMS_Status_Ventil 0;
BA_ "Fehlerwert" SG_ 1438 BMS_Status_Ventil 7;
BA_ "GenSigSendType" SG_ 1438 BMS_Temp_Epsilon 0;
BA_ "GenSigSwitchedByIgnition" SG_ 1438 BMS_Temp_Epsilon 0;
BA_ "GenSigSendType" SG_ 1438 BMS_Temperatur 0;
BA_ "GenSigStartValue" SG_ 1438 BMS_Temperatur 254;
BA_ "GenSigSwitchedByIgnition" SG_ 1438 BMS_Temperatur 0;
BA_ "Fehlerwert" SG_ 1438 BMS_Temperatur 255;
BA_ "GenSigSendType" SG_ 1438 BMS_Temperierung_Anf 0;
BA_ "GenSigStartValue" SG_ 1438 BMS_Temperierung_Anf 3;
BA_ "GenSigSwitchedByIgnition" SG_ 1438 BMS_Temperierung_Anf 0;
BA_ "GenSigSendType" SG_ 2527679979 BMS_BCCM_Anforderung 0;
BA_ "GenSigStartValue" SG_ 2527679979 BMS_BCCM_Anforderung 2;
BA_ "GenSigSwitchedByIgnition" SG_ 2527679979 BMS_BCCM_Anforderung 0;
BA_ "Fehlerwert" SG_ 2527679979 BMS_BCCM_Anforderung 3;
BA_ "GenSigSendType" SG_ 2527679979 BMS_HV_Auszeit 0;
BA_ "GenSigStartValue" SG_ 2527679979 BMS_HV_Auszeit 510;
BA_ "GenSigSwitchedByIgnition" SG_ 2527679979 BMS_HV_Auszeit 0;
BA_ "Fehlerwert" SG_ 2527679979 BMS_HV_Auszeit 511;
BA_ "GenSigSendType" SG_ 2527679979 BMS_HV_Auszeit_Status 0;
BA_ "GenSigSwitchedByIgnition" SG_ 2527679979 BMS_HV_Auszeit_Status 0;
BA_ "GenSigSendType" SG_ 2527679979 BMS_Kapazitaet 0;
BA_ "GenSigStartValue" SG_ 2527679979 BMS_Kapazitaet 2047;
BA_ "GenSigSwitchedByIgnition" SG_ 2527679979 BMS_Kapazitaet 0;
BA_ "GenSigSendType" SG_ 2527679979 BMS_max_Grenz_SOC 0;
BA_ "GenSigStartValue" SG_ 2527679979 BMS_max_Grenz_SOC 31;
BA_ "GenSigSwitchedByIgnition" SG_ 2527679979 BMS_max_Grenz_SOC 0;
BA_ "GenSigSendType" SG_ 2527679979 BMS_min_Grenz_SOC 0;
BA_ "GenSigStartValue" SG_ 2527679979 BMS_min_Grenz_SOC 31;
BA_ "GenSigSwitchedByIgnition" SG_ 2527679979 BMS_min_Grenz_SOC 0;
BA_ "GenSigSendType" SG_ 2527679979 BMS_SOC_Kaltstart 0;
BA_ "GenSigStartValue" SG_ 2527679979 BMS_SOC_Kaltstart 2046;
BA_ "GenSigSwitchedByIgnition" SG_ 2527679979 BMS_SOC_Kaltstart 0;
BA_ "Fehlerwert" SG_ 2527679979 BMS_SOC_Kaltstart 2047;
BA_ "GenSigSendType" SG_ 1289 BMS_Energieinhalt_HiRes 0;
BA_ "GenSigStartValue" SG_ 1289 BMS_Energieinhalt_HiRes 32766;
BA_ "GenSigSwitchedByIgnition" SG_ 1289 BMS_Energieinhalt_HiRes 0;
BA_ "Fehlerwert" SG_ 1289 BMS_Energieinhalt_HiRes 32767;
BA_ "GenSigSendType" SG_ 1289 BMS_MaxEnergieinhalt_HiRes 0;
BA_ "GenSigStartValue" SG_ 1289 BMS_MaxEnergieinhalt_HiRes 32766;
BA_ "GenSigSwitchedByIgnition" SG_ 1289 BMS_MaxEnergieinhalt_HiRes 0;
BA_ "Fehlerwert" SG_ 1289 BMS_MaxEnergieinhalt_HiRes 32767;
BA_ "GenSigSendType" SG_ 1289 BMS_NutzbarerEnergieinhalt 0;
BA_ "GenSigStartValue" SG_ 1289 BMS_NutzbarerEnergieinhalt 4094;
BA_ "GenSigSwitchedByIgnition" SG_ 1289 BMS_NutzbarerEnergieinhalt 0;
BA_ "Fehlerwert" SG_ 1289 BMS_NutzbarerEnergieinhalt 4095;
BA_ "GenSigSendType" SG_ 1289 BMS_NutzbarerSOC 0;
BA_ "GenSigStartValue" SG_ 1289 BMS_NutzbarerSOC 254;
BA_ "GenSigSwitchedByIgnition" SG_ 1289 BMS_NutzbarerSOC 0;
BA_ "Fehlerwert" SG_ 1289 BMS_NutzbarerSOC 255;
BA_ "GenSigSendType" SG_ 1289 BMS_Pred_Entladeperformance 0;
BA_ "GenSigStartValue" SG_ 1289 BMS_Pred_Entladeperformance 126;
BA_ "GenSigSwitchedByIgnition" SG_ 1289 BMS_Pred_Entladeperformance 0;
BA_ "Fehlerwert" SG_ 1289 BMS_Pred_Entladeperformance 127;
BA_ "GenSigSendType" SG_ 1289 BMS_Pred_Ladeperformance 0;
BA_ "GenSigStartValue" SG_ 1289 BMS_Pred_Ladeperformance 126;
BA_ "GenSigSwitchedByIgnition" SG_ 1289 BMS_Pred_Ladeperformance 0;
BA_ "Fehlerwert" SG_ 1289 BMS_Pred_Ladeperformance 127;
BA_ "GenSigSendType" SG_ 2527679654 BMS_IsoFehler 0;
BA_ "GenSigSwitchedByIgnition" SG_ 2527679654 BMS_IsoFehler 0;
BA_ "GenSigSendType" SG_ 2527679654 BMS_IsoZustand 0;
BA_ "GenSigSwitchedByIgnition" SG_ 2527679654 BMS_IsoZustand 0;
BA_ "GenSigSendType" SG_ 2527679654 BMS_IstTemperatur_hoechste 0;
BA_ "GenSigStartValue" SG_ 2527679654 BMS_IstTemperatur_hoechste 254;
BA_ "GenSigSwitchedByIgnition" SG_ 2527679654 BMS_IstTemperatur_hoechste 0;
BA_ "Fehlerwert" SG_ 2527679654 BMS_IstTemperatur_hoechste 255;
BA_ "GenSigSendType" SG_ 2527679654 BMS_IstTemperatur_niedrigste 0;
BA_ "GenSigStartValue" SG_ 2527679654 BMS_IstTemperatur_niedrigste 254;
BA_ "GenSigSwitchedByIgnition" SG_ 2527679654 BMS_IstTemperatur_niedrigste 0;
BA_ "Fehlerwert" SG_ 2527679654 BMS_IstTemperatur_niedrigste 255;
BA_ "GenSigSendType" SG_ 2527679654 BMS_IstZellspannung_hoechste 0;
BA_ "GenSigStartValue" SG_ 2527679654 BMS_IstZellspannung_hoechste 4094;
BA_ "GenSigSwitchedByIgnition" SG_ 2527679654 BMS_IstZellspannung_hoechste 0;
BA_ "Fehlerwert" SG_ 2527679654 BMS_IstZellspannung_hoechste 4095;
BA_ "GenSigSendType" SG_ 2527679654 BMS_IstZellspannung_niedrigste 0;
BA_ "GenSigStartValue" SG_ 2527679654 BMS_IstZellspannung_niedrigste 4094;
BA_ "GenSigSwitchedByIgnition" SG_ 2527679654 BMS_IstZellspannung_niedrigste 0;
BA_ "Fehlerwert" SG_ 2527679654 BMS_IstZellspannung_niedrigste 4095;
BA_ "GenSigSendType" SG_ 2589283666 BMS_EnergieAntw_Energie 0;
BA_ "GenSigStartValue" SG_ 2589283666 BMS_EnergieAntw_Energie 2046;
BA_ "GenSigSwitchedByIgnition" SG_ 2589283666 BMS_EnergieAntw_Energie 0;
BA_ "Fehlerwert" SG_ 2589283666 BMS_EnergieAntw_Energie 2047;
BA_ "GenSigSendType" SG_ 2589283666 BMS_EnergieAntw_Zaehler 3;
BA_ "GenSigStartValue" SG_ 2589283666 BMS_EnergieAntw_Zaehler 14;
BA_ "GenSigSwitchedByIgnition" SG_ 2589283666 BMS_EnergieAntw_Zaehler 0;
BA_ "Fehlerwert" SG_ 2589283666 BMS_EnergieAntw_Zaehler 15;
BA_ "GenSigSendType" SG_ 2589283666 BMS_LadegrenzeAntw_Leistung 0;
BA_ "GenSigStartValue" SG_ 2589283666 BMS_LadegrenzeAntw_Leistung 4094;
BA_ "GenSigSwitchedByIgnition" SG_ 2589283666 BMS_LadegrenzeAntw_Leistung 0;
BA_ "Fehlerwert" SG_ 2589283666 BMS_LadegrenzeAntw_Leistung 4095;
BA_ "GenSigSendType" SG_ 2589283666 BMS_LadegrenzeAntw_SOC 0;
BA_ "GenSigStartValue" SG_ 2589283666 BMS_LadegrenzeAntw_SOC 126;
BA_ "GenSigSwitchedByIgnition" SG_ 2589283666 BMS_LadegrenzeAntw_SOC 0;
BA_ "Fehlerwert" SG_ 2589283666 BMS_LadegrenzeAntw_SOC 127;
BA_ "GenSigSendType" SG_ 2589283666 BMS_LadegrenzeAntw_Zaehler 3;
BA_ "GenSigStartValue" SG_ 2589283666 BMS_LadegrenzeAntw_Zaehler 14;
BA_ "GenSigSwitchedByIgnition" SG_ 2589283666 BMS_LadegrenzeAntw_Zaehler 0;
BA_ "Fehlerwert" SG_ 2589283666 BMS_LadegrenzeAntw_Zaehler 15;
BA_ "GenSigSendType" SG_ 2589283666 BMS_MMTR_Status 3;
BA_ "GenSigStartValue" SG_ 2589283666 BMS_MMTR_Status 14;
BA_ "GenSigSwitchedByIgnition" SG_ 2589283666 BMS_MMTR_Status 0;
BA_ "Fehlerwert" SG_ 2589283666 BMS_MMTR_Status 15;
BA_ "GenSigSendType" SG_ 2463978838 BMS_NutzbarerEnergieinhalt_HiRes 0;
BA_ "GenSigStartValue" SG_ 2463978838 BMS_NutzbarerEnergieinhalt_HiRes 32766;
BA_ "GenSigSwitchedByIgnition" SG_ 2463978838 BMS_NutzbarerEnergieinhalt_HiRes 0;
BA_ "Fehlerwert" SG_ 2463978838 BMS_NutzbarerEnergieinhalt_HiRes 32767;
BA_ "GenSigSendType" SG_ 2463978838 BMS_ZellTemp_virtuell_max 0;
BA_ "GenSigStartValue" SG_ 2463978838 BMS_ZellTemp_virtuell_max 254;
BA_ "GenSigSwitchedByIgnition" SG_ 2463978838 BMS_ZellTemp_virtuell_max 0;
BA_ "Fehlerwert" SG_ 2463978838 BMS_ZellTemp_virtuell_max 255;
BA_ "GenSigSendType" SG_ 2463978838 BMS_ZellTemp_virtuell_min 0;
BA_ "GenSigStartValue" SG_ 2463978838 BMS_ZellTemp_virtuell_min 254;
BA_ "GenSigSwitchedByIgnition" SG_ 2463978838 BMS_ZellTemp_virtuell_min 0;
BA_ "Fehlerwert" SG_ 2463978838 BMS_ZellTemp_virtuell_min 255;
BA_ "GenSigFuncType" SG_ 2617128448 CCP_Klima_CRO_01_Data 9;
BA_ "GenSigSwitchedByIgnition" SG_ 2617128448 CCP_Klima_CRO_01_Data 0;
BA_ "GenSigFuncType" SG_ 2617128449 CCP_Klima_DTO_01_Data 9;
BA_ "GenSigSwitchedByIgnition" SG_ 2617128449 CCP_Klima_DTO_01_Data 0;
BA_ "GenSigFuncType" SG_ 2617167360 CCP_Lift_VA_CRO_01_Data 9;
BA_ "GenSigSwitchedByIgnition" SG_ 2617167360 CCP_Lift_VA_CRO_01_Data 0;
BA_ "GenSigFuncType" SG_ 2617167361 CCP_Lift_VA_DTO_01_Data 9;
BA_ "GenSigSwitchedByIgnition" SG_ 2617167361 CCP_Lift_VA_DTO_01_Data 0;
BA_ "GenSigSendType" SG_ 901 CHA_Fahrer_Umschaltung 3;
BA_ "GenSigSwitchedByIgnition" SG_ 901 CHA_Fahrer_Umschaltung 0;
BA_ "GenSigSendType" SG_ 901 CHA_Fahrer_Umschaltung_BMA 3;
BA_ "GenSigSwitchedByIgnition" SG_ 901 CHA_Fahrer_Umschaltung_BMA 0;
BA_ "GenSigSendType" SG_ 901 CHA_Ziel_FahrPr_ACC 3;
BA_ "GenSigSwitchedByIgnition" SG_ 901 CHA_Ziel_FahrPr_ACC 0;
BA_ "GenSigSendType" SG_ 901 CHA_Ziel_FahrPr_AFS 3;
BA_ "GenSigSwitchedByIgnition" SG_ 901 CHA_Ziel_FahrPr_AFS 0;
BA_ "GenSigSendType" SG_ 901 CHA_Ziel_FahrPr_AGA 3;
BA_ "GenSigSwitchedByIgnition" SG_ 901 CHA_Ziel_FahrPr_AGA 0;
BA_ "GenSigSendType" SG_ 901 CHA_Ziel_FahrPr_ALR 3;
BA_ "GenSigSwitchedByIgnition" SG_ 901 CHA_Ziel_FahrPr_ALR 0;
BA_ "GenSigSendType" SG_ 901 CHA_Ziel_FahrPr_DR 3;
BA_ "GenSigSwitchedByIgnition" SG_ 901 CHA_Ziel_FahrPr_DR 0;
BA_ "GenSigSendType" SG_ 901 CHA_Ziel_FahrPr_EPS 3;
BA_ "GenSigSwitchedByIgnition" SG_ 901 CHA_Ziel_FahrPr_EPS 0;
BA_ "GenSigSendType" SG_ 901 CHA_Ziel_FahrPr_ESP 3;
BA_ "GenSigSwitchedByIgnition" SG_ 901 CHA_Ziel_FahrPr_ESP 0;
BA_ "GenSigSendType" SG_ 901 CHA_Ziel_FahrPr_Freilauf 3;
BA_ "GenSigSwitchedByIgnition" SG_ 901 CHA_Ziel_FahrPr_Freilauf 0;
BA_ "GenSigSendType" SG_ 901 CHA_Ziel_FahrPr_GE 3;
BA_ "GenSigSwitchedByIgnition" SG_ 901 CHA_Ziel_FahrPr_GE 0;
BA_ "GenSigSendType" SG_ 901 CHA_Ziel_FahrPr_MO 3;
BA_ "GenSigSwitchedByIgnition" SG_ 901 CHA_Ziel_FahrPr_MO 0;
BA_ "GenSigSendType" SG_ 901 CHA_Ziel_FahrPr_MO_BZS 3;
BA_ "GenSigSwitchedByIgnition" SG_ 901 CHA_Ziel_FahrPr_MO_BZS 0;
BA_ "GenSigSendType" SG_ 901 CHA_Ziel_FahrPr_MO_StSt 3;
BA_ "GenSigSwitchedByIgnition" SG_ 901 CHA_Ziel_FahrPr_MO_StSt 0;
BA_ "GenSigSendType" SG_ 901 CHA_Ziel_FahrPr_PreCrash 3;
BA_ "GenSigSwitchedByIgnition" SG_ 901 CHA_Ziel_FahrPr_PreCrash 0;
BA_ "GenSigSendType" SG_ 901 CHA_Ziel_FahrPr_SAK 3;
BA_ "GenSigSwitchedByIgnition" SG_ 901 CHA_Ziel_FahrPr_SAK 0;
BA_ "GenSigSendType" SG_ 901 CHA_Ziel_FahrPr_VAQ 3;
BA_ "GenSigSwitchedByIgnition" SG_ 901 CHA_Ziel_FahrPr_VAQ 0;
BA_ "GenSigSendType" SG_ 902 CHA_Charge_LED 3;
BA_ "GenSigSwitchedByIgnition" SG_ 902 CHA_Charge_LED 0;
BA_ "GenSigSendType" SG_ 902 CHA_Current_Mode 3;
BA_ "GenSigSwitchedByIgnition" SG_ 902 CHA_Current_Mode 0;
BA_ "GenSigSendType" SG_ 902 CHA_Drehschalter_Istmodus 3;
BA_ "GenSigSwitchedByIgnition" SG_ 902 CHA_Drehschalter_Istmodus 0;
BA_ "GenSigSendType" SG_ 902 CHA_Drive_Select1_LED 0;
BA_ "GenSigStartValue" SG_ 902 CHA_Drive_Select1_LED 3;
BA_ "GenSigSwitchedByIgnition" SG_ 902 CHA_Drive_Select1_LED 0;
BA_ "GenSigSendType" SG_ 902 CHA_Eco_Charisma_LED 3;
BA_ "GenSigSwitchedByIgnition" SG_ 902 CHA_Eco_Charisma_LED 0;
BA_ "GenSigSendType" SG_ 902 CHA_EV_LED 3;
BA_ "GenSigSwitchedByIgnition" SG_ 902 CHA_EV_LED 0;
BA_ "GenSigSendType" SG_ 902 CHA_Fahrer_Umschaltung 3;
BA_ "GenSigSwitchedByIgnition" SG_ 902 CHA_Fahrer_Umschaltung 0;
BA_ "GenSigSendType" SG_ 902 CHA_Kombi_Texte 3;
BA_ "GenSigSwitchedByIgnition" SG_ 902 CHA_Kombi_Texte 0;
BA_ "GenSigSendType" SG_ 902 CHA_Kombi_Texte_02 3;
BA_ "GenSigSwitchedByIgnition" SG_ 902 CHA_Kombi_Texte_02 0;
BA_ "GenSigSendType" SG_ 902 CHA_Offroad_LED 3;
BA_ "GenSigSwitchedByIgnition" SG_ 902 CHA_Offroad_LED 0;
BA_ "Fehlerwert" SG_ 902 CHA_Offroad_LED 3;
BA_ "GenSigSendType" SG_ 902 CHA_Ziel_FahrPr_03_01 3;
BA_ "GenSigSwitchedByIgnition" SG_ 902 CHA_Ziel_FahrPr_03_01 0;
BA_ "GenSigSendType" SG_ 902 CHA_Ziel_FahrPr_03_02 3;
BA_ "GenSigSwitchedByIgnition" SG_ 902 CHA_Ziel_FahrPr_03_02 0;
BA_ "GenSigSendType" SG_ 902 CHA_Ziel_FahrPr_AMB 3;
BA_ "GenSigSwitchedByIgnition" SG_ 902 CHA_Ziel_FahrPr_AMB 0;
BA_ "GenSigSendType" SG_ 902 CHA_Ziel_FahrPr_HSP 3;
BA_ "GenSigSwitchedByIgnition" SG_ 902 CHA_Ziel_FahrPr_HSP 0;
BA_ "GenSigSendType" SG_ 902 CHA_Ziel_FahrPr_IVB 3;
BA_ "GenSigSwitchedByIgnition" SG_ 902 CHA_Ziel_FahrPr_IVB 0;
BA_ "GenSigSendType" SG_ 902 CHA_Ziel_FahrPr_KL 3;
BA_ "GenSigSwitchedByIgnition" SG_ 902 CHA_Ziel_FahrPr_KL 0;
BA_ "GenSigSendType" SG_ 902 CHA_Ziel_FahrPr_RWB 3;
BA_ "GenSigSwitchedByIgnition" SG_ 902 CHA_Ziel_FahrPr_RWB 0;
BA_ "GenSigSendType" SG_ 1000 CHA_Fahrer_Umschaltung 3;
BA_ "GenSigSwitchedByIgnition" SG_ 1000 CHA_Fahrer_Umschaltung 0;
BA_ "GenSigSendType" SG_ 1000 CHA_Ziel_FahrPr_AFR 3;
BA_ "GenSigSwitchedByIgnition" SG_ 1000 CHA_Ziel_FahrPr_AFR 0;
BA_ "GenSigSendType" SG_ 1000 CHA_Ziel_FahrPr_AV 3;
BA_ "GenSigSwitchedByIgnition" SG_ 1000 CHA_Ziel_FahrPr_AV 0;
BA_ "GenSigSendType" SG_ 1000 CHA_Ziel_FahrPr_EAR 3;
BA_ "GenSigSwitchedByIgnition" SG_ 1000 CHA_Ziel_FahrPr_EAR 0;
BA_ "GenSigSendType" SG_ 1000 CHA_Ziel_FahrPr_EBKV 3;
BA_ "GenSigSwitchedByIgnition" SG_ 1000 CHA_Ziel_FahrPr_EBKV 0;
BA_ "GenSigSendType" SG_ 1000 CHA_Ziel_FahrPr_FCWO 3;
BA_ "GenSigSwitchedByIgnition" SG_ 1000 CHA_Ziel_FahrPr_FCWO 0;
BA_ "GenSigSendType" SG_ 1000 CHA_Ziel_FahrPr_FCWP 3;
BA_ "GenSigSwitchedByIgnition" SG_ 1000 CHA_Ziel_FahrPr_FCWP 0;
BA_ "GenSigSendType" SG_ 1000 CHA_Ziel_FahrPr_HAL 3;
BA_ "GenSigSwitchedByIgnition" SG_ 1000 CHA_Ziel_FahrPr_HAL 0;
BA_ "GenSigSendType" SG_ 1000 CHA_Ziel_FahrPr_HDC 3;
BA_ "GenSigSwitchedByIgnition" SG_ 1000 CHA_Ziel_FahrPr_HDC 0;
BA_ "GenSigSendType" SG_ 1000 CHA_Ziel_FahrPr_IL 3;
BA_ "GenSigSwitchedByIgnition" SG_ 1000 CHA_Ziel_FahrPr_IL 0;
BA_ "GenSigSendType" SG_ 1000 CHA_Ziel_FahrPr_MXB 3;
BA_ "GenSigSwitchedByIgnition" SG_ 1000 CHA_Ziel_FahrPr_MXB 0;
BA_ "GenSigSendType" SG_ 1000 CHA_Ziel_FahrPr_NR 3;
BA_ "GenSigSwitchedByIgnition" SG_ 1000 CHA_Ziel_FahrPr_NR 0;
BA_ "GenSigSendType" SG_ 1000 CHA_Ziel_FahrPr_QS 3;
BA_ "GenSigSwitchedByIgnition" SG_ 1000 CHA_Ziel_FahrPr_QS 0;
BA_ "GenSigSendType" SG_ 1000 CHA_Ziel_FahrPr_SCU 3;
BA_ "GenSigSwitchedByIgnition" SG_ 1000 CHA_Ziel_FahrPr_SCU 0;
BA_ "GenSigSendType" SG_ 1000 CHA_Ziel_FahrPr_WarnBrems 3;
BA_ "GenSigSwitchedByIgnition" SG_ 1000 CHA_Ziel_FahrPr_WarnBrems 0;
BA_ "GenSigSendType" SG_ 1022 CHA_Current_Mode_BMA 3;
BA_ "GenSigSwitchedByIgnition" SG_ 1022 CHA_Current_Mode_BMA 0;
BA_ "GenSigSendType" SG_ 1022 CHA_Fahrer_Umschaltung 3;
BA_ "GenSigSwitchedByIgnition" SG_ 1022 CHA_Fahrer_Umschaltung 0;
BA_ "GenSigSendType" SG_ 1022 CHA_Fahrer_Umschaltung_BMA 3;
BA_ "GenSigSwitchedByIgnition" SG_ 1022 CHA_Fahrer_Umschaltung_BMA 0;
BA_ "GenSigSendType" SG_ 1022 CHA_Ziel_FahrPr_AGK 3;
BA_ "GenSigSwitchedByIgnition" SG_ 1022 CHA_Ziel_FahrPr_AGK 0;
BA_ "GenSigSendType" SG_ 1022 CHA_Ziel_FahrPr_BMS 3;
BA_ "GenSigSwitchedByIgnition" SG_ 1022 CHA_Ziel_FahrPr_BMS 0;
BA_ "GenSigSendType" SG_ 1022 CHA_Ziel_FahrPr_EDS 3;
BA_ "GenSigSwitchedByIgnition" SG_ 1022 CHA_Ziel_FahrPr_EDS 0;
BA_ "GenSigSendType" SG_ 1022 CHA_Ziel_FahrPr_HHC 3;
BA_ "GenSigSwitchedByIgnition" SG_ 1022 CHA_Ziel_FahrPr_HHC 0;
BA_ "GenSigSendType" SG_ 1022 CHA_Ziel_FahrPr_MO_Freilauf 3;
BA_ "GenSigSwitchedByIgnition" SG_ 1022 CHA_Ziel_FahrPr_MO_Freilauf 0;
BA_ "GenSigSendType" SG_ 1022 CHA_Ziel_FahrPr_PACC 3;
BA_ "GenSigSwitchedByIgnition" SG_ 1022 CHA_Ziel_FahrPr_PACC 0;
BA_ "GenSigSendType" SG_ 1022 CHA_Ziel_FahrPr_PDC 3;
BA_ "GenSigSwitchedByIgnition" SG_ 1022 CHA_Ziel_FahrPr_PDC 0;
BA_ "GenSigSendType" SG_ 1022 CHA_Ziel_FahrPr_Reku_ZwGas 3;
BA_ "GenSigSwitchedByIgnition" SG_ 1022 CHA_Ziel_FahrPr_Reku_ZwGas 0;
BA_ "GenSigSendType" SG_ 615 Daempfer_02_BZ 0;
BA_ "GenSigFuncType" SG_ 615 Daempfer_02_BZ 1;
BA_ "GenSigSendType" SG_ 615 Daempfer_02_CRC 0;
BA_ "GenSigFuncType" SG_ 615 Daempfer_02_CRC 2;
BA_ "GenSigSendType" SG_ 615 DR_Charisma_FahrPr 0;
BA_ "GenSigSendType" SG_ 615 DR_Charisma_Status 0;
BA_ "GenSigSendType" SG_ 615 DR_DynAGL_Anf_Entkopplung 0;
BA_ "GenSigSendType" SG_ 615 DR_DynAGL_Anf_im_Leerlauf 0;
BA_ "GenSigSendType" SG_ 615 DR_ESP_Zuschaltung 0;
BA_ "GenSigSendType" SG_ 615 DR_Systemstatus 0;
BA_ "GenSigSendType" SG_ 615 EFP_LstgBegr 0;
BA_ "GenSigStartValue" SG_ 615 EFP_LstgBegr 1022;
BA_ "GenSigSwitchedByIgnition" SG_ 615 EFP_LstgBegr 0;
BA_ "Fehlerwert" SG_ 615 EFP_LstgBegr 1023;
BA_ "GenSigSendType" SG_ 615 EFP_Niveauzustand_Lift 0;
BA_ "GenSigSwitchedByIgnition" SG_ 615 EFP_Niveauzustand_Lift 0;
BA_ "Fehlerwert" SG_ 615 EFP_Niveauzustand_Lift 5;
BA_ "GenSigSendType" SG_ 615 EFP_Verfuegbarkeit_Lift 0;
BA_ "GenSigSwitchedByIgnition" SG_ 615 EFP_Verfuegbarkeit_Lift 0;
BA_ "GenSigSendType" SG_ 615 EFP_Vorlaufzeit_Lift 0;
BA_ "GenSigSwitchedByIgnition" SG_ 615 EFP_Vorlaufzeit_Lift 0;
BA_ "Fehlerwert" SG_ 615 EFP_Vorlaufzeit_Lift 7;
BA_ "GenSigSwitchedByIgnition" SG_ 2617012736 DEV_BCM1_Resp_00_Data 0;
BA_ "GenSigSwitchedByIgnition" SG_ 2617012991 DEV_BCM1_Resp_FF_Data 0;
BA_ "GenSigSwitchedByIgnition" SG_ 2617037312 DEV_Klima_Fond_Tx_00_Data 0;
BA_ "GenSigSwitchedByIgnition" SG_ 2617037567 DEV_Klima_Fond_Tx_FF_Data 0;
BA_ "GenSigSwitchedByIgnition" SG_ 2617127424 DEV_Klima_Tx_00_Data 0;
BA_ "GenSigSwitchedByIgnition" SG_ 2617127679 DEV_Klima_Tx_FF_Data 0;
BA_ "GenSigFuncType" SG_ 2617166336 DEV_Lift_VA_Req_01_Data 9;
BA_ "GenSigSwitchedByIgnition" SG_ 2617166336 DEV_Lift_VA_Req_01_Data 0;
BA_ "GenSigFuncType" SG_ 2617166337 DEV_Lift_VA_Resp_01_Data 9;
BA_ "GenSigSwitchedByIgnition" SG_ 2617166337 DEV_Lift_VA_Resp_01_Data 0;
BA_ "GenSigFuncType" SG_ 2617166591 DEV_Lift_VA_Resp_FF_Data 9;
BA_ "GenSigSwitchedByIgnition" SG_ 2617166591 DEV_Lift_VA_Resp_FF_Data 0;
BA_ "GenSigSwitchedByIgnition" SG_ 2617123584 DEV_VAS_L_Resp_00_Data 0;
BA_ "GenSigSwitchedByIgnition" SG_ 2617123839 DEV_VAS_L_Resp_FF_Data 0;
BA_ "GenSigSwitchedByIgnition" SG_ 2617125632 DEV_VAS_R_Resp_00_Data 0;
BA_ "GenSigSwitchedByIgnition" SG_ 2617125887 DEV_VAS_R_Resp_FF_Data 0;
BA_ "GenSigSendType" SG_ 2549880614 DIA_AAU_Req_Data 3;
BA_ "GenSigFuncType" SG_ 2549880614 DIA_AAU_Req_Data 9;
BA_ "GenSigSwitchedByIgnition" SG_ 2549880614 DIA_AAU_Req_Data 0;
BA_ "GenSigSendType" SG_ 2550011686 DIA_AAU_Resp_Data 3;
BA_ "GenSigFuncType" SG_ 2550011686 DIA_AAU_Resp_Data 9;
BA_ "GenSigSwitchedByIgnition" SG_ 2550011686 DIA_AAU_Resp_Data 0;
BA_ "GenSigSendType" SG_ 2549880393 DIA_EVLS_Req_Data 3;
BA_ "GenSigFuncType" SG_ 2549880393 DIA_EVLS_Req_Data 9;
BA_ "GenSigSwitchedByIgnition" SG_ 2549880393 DIA_EVLS_Req_Data 0;
BA_ "GenSigSendType" SG_ 2550011465 DIA_EVLS_Resp_Data 3;
BA_ "GenSigFuncType" SG_ 2550011465 DIA_EVLS_Resp_Data 9;
BA_ "GenSigSwitchedByIgnition" SG_ 2550011465 DIA_EVLS_Resp_Data 0;
BA_ "GenSigSendType" SG_ 2549880347 DIA_Geblaese_Req_Data 3;
BA_ "GenSigFuncType" SG_ 2549880347 DIA_Geblaese_Req_Data 9;
BA_ "GenSigSwitchedByIgnition" SG_ 2549880347 DIA_Geblaese_Req_Data 0;
BA_ "GenSigSendType" SG_ 2550011419 DIA_Geblaese_Resp_Data 3;
BA_ "GenSigFuncType" SG_ 2550011419 DIA_Geblaese_Resp_Data 9;
BA_ "GenSigSwitchedByIgnition" SG_ 2550011419 DIA_Geblaese_Resp_Data 0;
BA_ "GenSigSendType" SG_ 2549880340 DIA_gLW_LM_L_Req_Data 3;
BA_ "GenSigFuncType" SG_ 2549880340 DIA_gLW_LM_L_Req_Data 9;
BA_ "GenSigSwitchedByIgnition" SG_ 2549880340 DIA_gLW_LM_L_Req_Data 0;
BA_ "GenSigSendType" SG_ 2550011412 DIA_gLW_LM_L_Resp_Data 3;
BA_ "GenSigFuncType" SG_ 2550011412 DIA_gLW_LM_L_Resp_Data 9;
BA_ "GenSigSwitchedByIgnition" SG_ 2550011412 DIA_gLW_LM_L_Resp_Data 0;
BA_ "GenSigSendType" SG_ 2549880341 DIA_gLW_LM_R_Req_Data 3;
BA_ "GenSigFuncType" SG_ 2549880341 DIA_gLW_LM_R_Req_Data 9;
BA_ "GenSigSwitchedByIgnition" SG_ 2549880341 DIA_gLW_LM_R_Req_Data 0;
BA_ "GenSigSendType" SG_ 2550011413 DIA_gLW_LM_R_Resp_Data 3;
BA_ "GenSigFuncType" SG_ 2550011413 DIA_gLW_LM_R_Resp_Data 9;
BA_ "GenSigSwitchedByIgnition" SG_ 2550011413 DIA_gLW_LM_R_Resp_Data 0;
BA_ "GenSigSendType" SG_ 2549880577 DIA_KBF_Req_Data 3;
BA_ "GenSigFuncType" SG_ 2549880577 DIA_KBF_Req_Data 9;
BA_ "GenSigSwitchedByIgnition" SG_ 2549880577 DIA_KBF_Req_Data 0;
BA_ "GenSigSendType" SG_ 2550011649 DIA_KBF_Resp_Data 3;
BA_ "GenSigFuncType" SG_ 2550011649 DIA_KBF_Resp_Data 9;
BA_ "GenSigSwitchedByIgnition" SG_ 2550011649 DIA_KBF_Resp_Data 0;
BA_ "GenSigSendType" SG_ 2549880639 DIA_KPV_Req_Data 3;
BA_ "GenSigFuncType" SG_ 2549880639 DIA_KPV_Req_Data 9;
BA_ "GenSigSwitchedByIgnition" SG_ 2549880639 DIA_KPV_Req_Data 0;
BA_ "GenSigSendType" SG_ 2550011711 DIA_KPV_Resp_Data 3;
BA_ "GenSigFuncType" SG_ 2550011711 DIA_KPV_Resp_Data 9;
BA_ "GenSigSwitchedByIgnition" SG_ 2550011711 DIA_KPV_Resp_Data 0;
BA_ "GenSigSendType" SG_ 2549880330 DIA_LED_LM_L_Req_Data 3;
BA_ "GenSigFuncType" SG_ 2549880330 DIA_LED_LM_L_Req_Data 9;
BA_ "GenSigSwitchedByIgnition" SG_ 2549880330 DIA_LED_LM_L_Req_Data 0;
BA_ "GenSigSendType" SG_ 2550011402 DIA_LED_LM_L_Resp_Data 3;
BA_ "GenSigFuncType" SG_ 2550011402 DIA_LED_LM_L_Resp_Data 9;
BA_ "GenSigSwitchedByIgnition" SG_ 2550011402 DIA_LED_LM_L_Resp_Data 0;
BA_ "GenSigSendType" SG_ 2549880331 DIA_LED_LM_R_Req_Data 3;
BA_ "GenSigFuncType" SG_ 2549880331 DIA_LED_LM_R_Req_Data 9;
BA_ "GenSigSwitchedByIgnition" SG_ 2549880331 DIA_LED_LM_R_Req_Data 0;
BA_ "GenSigSendType" SG_ 2550011403 DIA_LED_LM_R_Resp_Data 3;
BA_ "GenSigFuncType" SG_ 2550011403 DIA_LED_LM_R_Resp_Data 9;
BA_ "GenSigSwitchedByIgnition" SG_ 2550011403 DIA_LED_LM_R_Resp_Data 0;
BA_ "GenSigSendType" SG_ 2549880633 DIA_LIM_2_Req_Data 3;
BA_ "GenSigFuncType" SG_ 2549880633 DIA_LIM_2_Req_Data 9;
BA_ "GenSigSwitchedByIgnition" SG_ 2549880633 DIA_LIM_2_Req_Data 0;
BA_ "GenSigSendType" SG_ 2550011705 DIA_LIM_2_Resp_Data 3;
BA_ "GenSigFuncType" SG_ 2550011705 DIA_LIM_2_Resp_Data 9;
BA_ "GenSigSwitchedByIgnition" SG_ 2550011705 DIA_LIM_2_Resp_Data 0;
BA_ "GenSigSendType" SG_ 2549880350 DIA_LIM_Req_Data 3;
BA_ "GenSigFuncType" SG_ 2549880350 DIA_LIM_Req_Data 9;
BA_ "GenSigSwitchedByIgnition" SG_ 2549880350 DIA_LIM_Req_Data 0;
BA_ "GenSigSendType" SG_ 2550011422 DIA_LIM_Resp_Data 3;
BA_ "GenSigFuncType" SG_ 2550011422 DIA_LIM_Resp_Data 9;
BA_ "GenSigSwitchedByIgnition" SG_ 2550011422 DIA_LIM_Resp_Data 0;
BA_ "GenSigSendType" SG_ 2549880427 DIA_MXB_LM_L_Req_Data 3;
BA_ "GenSigFuncType" SG_ 2549880427 DIA_MXB_LM_L_Req_Data 9;
BA_ "GenSigSwitchedByIgnition" SG_ 2549880427 DIA_MXB_LM_L_Req_Data 0;
BA_ "GenSigSendType" SG_ 2550011499 DIA_MXB_LM_L_Resp_Data 3;
BA_ "GenSigFuncType" SG_ 2550011499 DIA_MXB_LM_L_Resp_Data 9;
BA_ "GenSigSwitchedByIgnition" SG_ 2550011499 DIA_MXB_LM_L_Resp_Data 0;
BA_ "GenSigSendType" SG_ 2549880428 DIA_MXB_LM_R_Req_Data 3;
BA_ "GenSigFuncType" SG_ 2549880428 DIA_MXB_LM_R_Req_Data 9;
BA_ "GenSigSwitchedByIgnition" SG_ 2549880428 DIA_MXB_LM_R_Req_Data 0;
BA_ "GenSigSendType" SG_ 2550011500 DIA_MXB_LM_R_Resp_Data 3;
BA_ "GenSigFuncType" SG_ 2550011500 DIA_MXB_LM_R_Resp_Data 9;
BA_ "GenSigSwitchedByIgnition" SG_ 2550011500 DIA_MXB_LM_R_Resp_Data 0;
BA_ "GenSigSendType" SG_ 2549880612 DIA_SWP_Req_Data 3;
BA_ "GenSigFuncType" SG_ 2549880612 DIA_SWP_Req_Data 9;
BA_ "GenSigSwitchedByIgnition" SG_ 2549880612 DIA_SWP_Req_Data 0;
BA_ "GenSigSendType" SG_ 2550011684 DIA_SWP_Resp_Data 3;
BA_ "GenSigFuncType" SG_ 2550011684 DIA_SWP_Resp_Data 9;
BA_ "GenSigSwitchedByIgnition" SG_ 2550011684 DIA_SWP_Resp_Data 0;
BA_ "GenSigSendType" SG_ 2549880324 DIA_UGDO_S_Req_Data 3;
BA_ "GenSigFuncType" SG_ 2549880324 DIA_UGDO_S_Req_Data 9;
BA_ "GenSigSwitchedByIgnition" SG_ 2549880324 DIA_UGDO_S_Req_Data 0;
BA_ "GenSigSendType" SG_ 2550011396 DIA_UGDO_S_Resp_Data 3;
BA_ "GenSigFuncType" SG_ 2550011396 DIA_UGDO_S_Resp_Data 9;
BA_ "GenSigSwitchedByIgnition" SG_ 2550011396 DIA_UGDO_S_Resp_Data 0;
BA_ "GenSigSendType" SG_ 2549880679 DIA_WiBli_L_Req 3;
BA_ "GenSigFuncType" SG_ 2549880679 DIA_WiBli_L_Req 9;
BA_ "GenSigSwitchedByIgnition" SG_ 2549880679 DIA_WiBli_L_Req 0;
BA_ "GenSigSendType" SG_ 2550011751 DIA_WiBli_L_Resp 3;
BA_ "GenSigFuncType" SG_ 2550011751 DIA_WiBli_L_Resp 9;
BA_ "GenSigSwitchedByIgnition" SG_ 2550011751 DIA_WiBli_L_Resp 0;
BA_ "GenSigSendType" SG_ 2549880680 DIA_WiBli_R_Req 3;
BA_ "GenSigFuncType" SG_ 2549880680 DIA_WiBli_R_Req 9;
BA_ "GenSigSwitchedByIgnition" SG_ 2549880680 DIA_WiBli_R_Req 0;
BA_ "GenSigSendType" SG_ 2550011752 DIA_WiBli_R_Resp 3;
BA_ "GenSigFuncType" SG_ 2550011752 DIA_WiBli_R_Resp 9;
BA_ "GenSigSwitchedByIgnition" SG_ 2550011752 DIA_WiBli_R_Resp 0;
BA_ "GenSigSendType" SG_ 2549880321 DIA_WWS_Req_Data 3;
BA_ "GenSigFuncType" SG_ 2549880321 DIA_WWS_Req_Data 9;
BA_ "GenSigSwitchedByIgnition" SG_ 2549880321 DIA_WWS_Req_Data 0;
BA_ "GenSigSendType" SG_ 2550011393 DIA_WWS_Resp_Data 3;
BA_ "GenSigFuncType" SG_ 2550011393 DIA_WWS_Resp_Data 9;
BA_ "GenSigSwitchedByIgnition" SG_ 2550011393 DIA_WWS_Resp_Data 0;
BA_ "GenSigSendType" SG_ 1714 DGN_Verlernzaehler 0;
BA_ "GenSigSwitchedByIgnition" SG_ 1714 DGN_Verlernzaehler 0;
BA_ "GenSigSendType" SG_ 1714 KBI_Kilometerstand 0;
BA_ "GenSigStartValue" SG_ 1714 KBI_Kilometerstand 1048574;
BA_ "GenSigSwitchedByIgnition" SG_ 1714 KBI_Kilometerstand 0;
BA_ "Fehlerwert" SG_ 1714 KBI_Kilometerstand 1048575;
BA_ "GenSigSendType" SG_ 1714 Kombi_02_alt 0;
BA_ "GenSigStartValue" SG_ 1714 Kombi_02_alt 1;
BA_ "GenSigFuncType" SG_ 1714 Kombi_02_alt 5;
BA_ "GenSigSwitchedByIgnition" SG_ 1714 Kombi_02_alt 0;
BA_ "GenSigSendType" SG_ 1714 UH_Jahr 0;
BA_ "GenSigSwitchedByIgnition" SG_ 1714 UH_Jahr 0;
BA_ "GenSigSendType" SG_ 1714 UH_Minute 0;
BA_ "GenSigSwitchedByIgnition" SG_ 1714 UH_Minute 0;
BA_ "GenSigSendType" SG_ 1714 UH_Monat 0;
BA_ "GenSigSwitchedByIgnition" SG_ 1714 UH_Monat 0;
BA_ "Fehlerwert" SG_ 1714 UH_Monat 15;
BA_ "GenSigSendType" SG_ 1714 UH_Sekunde 0;
BA_ "GenSigSwitchedByIgnition" SG_ 1714 UH_Sekunde 0;
BA_ "GenSigSendType" SG_ 1714 UH_Stunde 0;
BA_ "GenSigSwitchedByIgnition" SG_ 1714 UH_Stunde 0;
BA_ "GenSigSendType" SG_ 1714 UH_Tag 0;
BA_ "GenSigSwitchedByIgnition" SG_ 1714 UH_Tag 0;
BA_ "GenSigSendType" SG_ 1714 Uhrzeit_01_alt 0;
BA_ "GenSigStartValue" SG_ 1714 Uhrzeit_01_alt 1;
BA_ "GenSigFuncType" SG_ 1714 Uhrzeit_01_alt 5;
BA_ "GenSigSwitchedByIgnition" SG_ 1714 Uhrzeit_01_alt 0;
BA_ "GenSigSendType" SG_ 1520 BCM1_Stellgroesse_Kl_58s 3;
BA_ "GenSigStartValue" SG_ 1520 BCM1_Stellgroesse_Kl_58s 126;
BA_ "GenSigSwitchedByIgnition" SG_ 1520 BCM1_Stellgroesse_Kl_58s 0;
BA_ "Fehlerwert" SG_ 1520 BCM1_Stellgroesse_Kl_58s 127;
BA_ "GenSigSendType" SG_ 1520 DI_Display_Nachtdesign 3;
BA_ "GenSigSwitchedByIgnition" SG_ 1520 DI_Display_Nachtdesign 0;
BA_ "GenSigSendType" SG_ 1520 DI_Fotosensor 3;
BA_ "GenSigSwitchedByIgnition" SG_ 1520 DI_Fotosensor 0;
BA_ "GenSigSendType" SG_ 1520 DI_KL_58xd 3;
BA_ "GenSigStartValue" SG_ 1520 DI_KL_58xd 254;
BA_ "GenSigSwitchedByIgnition" SG_ 1520 DI_KL_58xd 0;
BA_ "Fehlerwert" SG_ 1520 DI_KL_58xd 255;
BA_ "GenSigSendType" SG_ 1520 DI_KL_58xs 3;
BA_ "GenSigStartValue" SG_ 1520 DI_KL_58xs 126;
BA_ "GenSigSwitchedByIgnition" SG_ 1520 DI_KL_58xs 0;
BA_ "Fehlerwert" SG_ 1520 DI_KL_58xs 127;
BA_ "GenSigSendType" SG_ 1520 DI_KL_58xt 3;
BA_ "GenSigStartValue" SG_ 1520 DI_KL_58xt 126;
BA_ "GenSigSwitchedByIgnition" SG_ 1520 DI_KL_58xt 0;
BA_ "Fehlerwert" SG_ 1520 DI_KL_58xt 127;
BA_ "GenSigSendType" SG_ 420 EA_01_BZ 0;
BA_ "GenSigFuncType" SG_ 420 EA_01_BZ 1;
BA_ "GenSigSendType" SG_ 420 EA_01_CRC 0;
BA_ "GenSigFuncType" SG_ 420 EA_01_CRC 2;
BA_ "GenSigSendType" SG_ 420 EA_Anforderung_HMS 0;
BA_ "GenSigSendType" SG_ 420 EA_eCall_Anf 0;
BA_ "GenSigSwitchedByIgnition" SG_ 420 EA_eCall_Anf 0;
BA_ "GenSigSendType" SG_ 420 EA_Funktionsstatus 0;
BA_ "GenSigSendType" SG_ 420 EA_Gurtstraffer_Anf 0;
BA_ "GenSigSendType" SG_ 420 EA_Parken_beibehalten_HMS 0;
BA_ "GenSigStartValue" SG_ 420 EA_Parken_beibehalten_HMS 2;
BA_ "Fehlerwert" SG_ 420 EA_Parken_beibehalten_HMS 3;
BA_ "GenSigSendType" SG_ 420 EA_Sollbeschleunigung 0;
BA_ "GenSigStartValue" SG_ 420 EA_Sollbeschleunigung 2046;
BA_ "Fehlerwert" SG_ 420 EA_Sollbeschleunigung 2047;
BA_ "GenSigSendType" SG_ 420 EA_Warnruckprofil 0;
BA_ "GenSigSendType" SG_ 496 ACF_Lampe_Hands_Off 3;
BA_ "GenSigSwitchedByIgnition" SG_ 496 ACF_Lampe_Hands_Off 0;
BA_ "GenSigSendType" SG_ 496 EA_02_BZ 0;
BA_ "GenSigFuncType" SG_ 496 EA_02_BZ 1;
BA_ "GenSigSendType" SG_ 496 EA_02_CRC 0;
BA_ "GenSigFuncType" SG_ 496 EA_02_CRC 2;
BA_ "GenSigSendType" SG_ 496 EA_Blinken 3;
BA_ "GenSigSendType" SG_ 496 EA_Bremslichtblinken 3;
BA_ "GenSigSendType" SG_ 496 EA_Infotainment_Anf 3;
BA_ "GenSigSendType" SG_ 496 EA_Innenraumlicht_Anf 3;
BA_ "GenSigSendType" SG_ 496 EA_Status_HMI 3;
BA_ "GenSigSendType" SG_ 496 EA_Texte 3;
BA_ "GenSigSendType" SG_ 496 EA_Tueren_Anf 3;
BA_ "GenSigSendType" SG_ 496 STP_Primaeranz 3;
BA_ "GenSigSendType" SG_ 496 zFAS_Warnblinken 3;
BA_ "GenSigSendType" SG_ 2527679980 bCall_active 3;
BA_ "GenSigSwitchedByIgnition" SG_ 2527679980 bCall_active 0;
BA_ "GenSigSendType" SG_ 2527679980 eCall_Funktionsstatus 3;
BA_ "GenSigSwitchedByIgnition" SG_ 2527679980 eCall_Funktionsstatus 0;
BA_ "GenSigSendType" SG_ 2527679980 eCall_Funktionsstatus_02 3;
BA_ "GenSigStartValue" SG_ 2527679980 eCall_Funktionsstatus_02 7;
BA_ "GenSigSwitchedByIgnition" SG_ 2527679980 eCall_Funktionsstatus_02 0;
BA_ "GenSigSendType" SG_ 2527679980 eCall_Mute_Anf 3;
BA_ "GenSigSwitchedByIgnition" SG_ 2527679980 eCall_Mute_Anf 0;
BA_ "GenSigSendType" SG_ 2527679980 eCall_Statuslicht_Farbe1 3;
BA_ "GenSigSwitchedByIgnition" SG_ 2527679980 eCall_Statuslicht_Farbe1 0;
BA_ "GenSigSendType" SG_ 2527679980 eCall_Statuslicht_Farbe2 3;
BA_ "GenSigSwitchedByIgnition" SG_ 2527679980 eCall_Statuslicht_Farbe2 0;
BA_ "GenSigSendType" SG_ 2527679980 eCall_Subscription 3;
BA_ "GenSigSwitchedByIgnition" SG_ 2527679980 eCall_Subscription 0;
BA_ "GenSigSendType" SG_ 1603 KBI_Einheit_Datum 3;
BA_ "GenSigSwitchedByIgnition" SG_ 1603 KBI_Einheit_Datum 0;
BA_ "GenSigSendType" SG_ 1603 KBI_Einheit_Druck 3;
BA_ "GenSigSwitchedByIgnition" SG_ 1603 KBI_Einheit_Druck 0;
BA_ "GenSigSendType" SG_ 1603 KBI_Einheit_Masse 3;
BA_ "GenSigSwitchedByIgnition" SG_ 1603 KBI_Einheit_Masse 0;
BA_ "GenSigSendType" SG_ 1603 KBI_Einheit_Sprache 3;
BA_ "GenSigSwitchedByIgnition" SG_ 1603 KBI_Einheit_Sprache 0;
BA_ "GenSigSendType" SG_ 1603 KBI_Einheit_Streckenanz 3;
BA_ "GenSigSwitchedByIgnition" SG_ 1603 KBI_Einheit_Streckenanz 0;
BA_ "GenSigSendType" SG_ 1603 KBI_Einheit_Temp 3;
BA_ "GenSigSwitchedByIgnition" SG_ 1603 KBI_Einheit_Temp 0;
BA_ "GenSigSendType" SG_ 1603 KBI_Einheit_Uhrzeit 3;
BA_ "GenSigSwitchedByIgnition" SG_ 1603 KBI_Einheit_Uhrzeit 0;
BA_ "GenSigSendType" SG_ 1603 KBI_Einheit_Verbrauch 3;
BA_ "GenSigSwitchedByIgnition" SG_ 1603 KBI_Einheit_Verbrauch 0;
BA_ "GenSigSendType" SG_ 1603 KBI_Einheit_Verbrauch_elektr 3;
BA_ "GenSigSwitchedByIgnition" SG_ 1603 KBI_Einheit_Verbrauch_elektr 0;
BA_ "GenSigSendType" SG_ 1603 KBI_Einheit_Verbrauch_Gas 3;
BA_ "GenSigSwitchedByIgnition" SG_ 1603 KBI_Einheit_Verbrauch_Gas 0;
BA_ "GenSigSendType" SG_ 1603 KBI_Einheit_Volumen 3;
BA_ "GenSigSwitchedByIgnition" SG_ 1603 KBI_Einheit_Volumen 0;
BA_ "GenSigSendType" SG_ 1603 KBI_MFA_v_Einheit_02 3;
BA_ "GenSigSwitchedByIgnition" SG_ 1603 KBI_MFA_v_Einheit_02 0;
BA_ "GenSigSendType" SG_ 260 EPB_01_BZ 0;
BA_ "GenSigFuncType" SG_ 260 EPB_01_BZ 1;
BA_ "GenSigSwitchedByIgnition" SG_ 260 EPB_01_BZ 0;
BA_ "GenSigSendType" SG_ 260 EPB_01_CRC 0;
BA_ "GenSigFuncType" SG_ 260 EPB_01_CRC 2;
BA_ "GenSigSwitchedByIgnition" SG_ 260 EPB_01_CRC 0;
BA_ "GenSigSendType" SG_ 260 EPB_DAA_Randbed_erf 0;
BA_ "GenSigSwitchedByIgnition" SG_ 260 EPB_DAA_Randbed_erf 0;
BA_ "GenSigSendType" SG_ 260 EPB_Fehlerstatus_02 3;
BA_ "GenSigSwitchedByIgnition" SG_ 260 EPB_Fehlerstatus_02 0;
BA_ "GenSigSendType" SG_ 260 EPB_Freig_Verzoeg_Anf 0;
BA_ "GenSigSwitchedByIgnition" SG_ 260 EPB_Freig_Verzoeg_Anf 0;
BA_ "GenSigSendType" SG_ 260 EPB_Pedalweg_Kuppl 3;
BA_ "GenSigSwitchedByIgnition" SG_ 260 EPB_Pedalweg_Kuppl 0;
BA_ "Fehlerwert" SG_ 260 EPB_Pedalweg_Kuppl 255;
BA_ "GenSigSendType" SG_ 260 EPB_QBit_Pedalweg_Kuppl 3;
BA_ "GenSigStartValue" SG_ 260 EPB_QBit_Pedalweg_Kuppl 1;
BA_ "GenSigSwitchedByIgnition" SG_ 260 EPB_QBit_Pedalweg_Kuppl 0;
BA_ "GenSigSendType" SG_ 260 EPB_QBit_Schalterpos 0;
BA_ "GenSigStartValue" SG_ 260 EPB_QBit_Schalterpos 1;
BA_ "GenSigSwitchedByIgnition" SG_ 260 EPB_QBit_Schalterpos 0;
BA_ "GenSigSendType" SG_ 260 EPB_Schalterposition 0;
BA_ "GenSigSwitchedByIgnition" SG_ 260 EPB_Schalterposition 0;
BA_ "Fehlerwert" SG_ 260 EPB_Schalterposition 3;
BA_ "GenSigSendType" SG_ 260 EPB_Spannkraft 0;
BA_ "GenSigStartValue" SG_ 260 EPB_Spannkraft 30;
BA_ "GenSigSwitchedByIgnition" SG_ 260 EPB_Spannkraft 0;
BA_ "Fehlerwert" SG_ 260 EPB_Spannkraft 31;
BA_ "GenSigSendType" SG_ 260 EPB_Status_02 3;
BA_ "GenSigStartValue" SG_ 260 EPB_Status_02 6;
BA_ "GenSigSwitchedByIgnition" SG_ 260 EPB_Status_02 0;
BA_ "GenSigSendType" SG_ 260 EPB_Verzoeg_Anf 0;
BA_ "GenSigStartValue" SG_ 260 EPB_Verzoeg_Anf 166;
BA_ "GenSigSwitchedByIgnition" SG_ 260 EPB_Verzoeg_Anf 0;
BA_REL_ "GenSigTimeoutTime" BU_SG_REL_ BCM1 SG_ 1431 SoSe_SunInt_2D_Re_Dash 5000;
BA_REL_ "GenSigTimeoutTime" BU_SG_REL_ BCM1 SG_ 1431 SoSe_SunInt_2D_Li_Dash 5000;
BA_REL_ "GenSigTimeoutTime" BU_SG_REL_ BCM1 SG_ 870 BM_ZV_auf 5000;
BA_REL_ "GenSigTimeoutTime" BU_SG_REL_ BCM1 SG_ 870 BM_ZV_zu 5000;
BA_REL_ "GenSigTimeoutTime" BU_SG_REL_ BCM1 SG_ 870 BM_DWA_ein 5000;
BA_REL_ "GenSigTimeoutTime" BU_SG_REL_ BCM1 SG_ 870 BM_DWA_Alarm 5000;
BA_REL_ "GenSigTimeoutTime" BU_SG_REL_ BCM1 SG_ 870 BM_Crash 5000;
BA_REL_ "GenSigTimeoutTime" BU_SG_REL_ BCM1 SG_ 870 BM_Panik 5000;
BA_REL_ "GenSigTimeoutTime" BU_SG_REL_ BCM1 SG_ 870 BM_Not_Bremsung 5000;
BA_REL_ "GenSigTimeoutTime" BU_SG_REL_ BCM1 SG_ 870 BM_GDO 5000;
BA_REL_ "GenSigTimeoutTime" BU_SG_REL_ BCM1 SG_ 870 BM_Warnblinken 5000;
BA_REL_ "GenSigTimeoutTime" BU_SG_REL_ BCM1 SG_ 870 BM_Taxi_Notalarm 5000;
BA_REL_ "GenSigTimeoutTime" BU_SG_REL_ BCM1 SG_ 870 BM_Telematik 5000;
BA_REL_ "GenSigTimeoutTime" BU_SG_REL_ BCM1 SG_ 870 BM_links 5000;
BA_REL_ "GenSigTimeoutTime" BU_SG_REL_ BCM1 SG_ 870 BM_rechts 5000;
BA_REL_ "GenSigTimeoutTime" BU_SG_REL_ BCM1 SG_ 870 Blinken_li_Fzg_Takt 5000;
BA_REL_ "GenSigTimeoutTime" BU_SG_REL_ BCM1 SG_ 870 Blinken_re_Fzg_Takt 5000;
BA_REL_ "GenSigTimeoutTime" BU_SG_REL_ BCM1 SG_ 870 BM_WBT_Beleuchtung 5000;
BA_REL_ "GenSigTimeoutTime" BU_SG_REL_ BCM1 SG_ 870 BM_HD_Oeffnung_angelernt 5000;
BA_REL_ "GenSigTimeoutTime" BU_SG_REL_ BCM1 SG_ 870 BM_Autobahn 5000;
BA_REL_ "GenSigTimeoutTime" BU_SG_REL_ BCM1 SG_ 870 BM_Rollenmodus_Blinken 5000;
BA_REL_ "GenSigTimeoutTime" BU_SG_REL_ BCM1 SG_ 870 BM_Recas 5000;
BA_REL_ "GenSigTimeoutTime" BU_SG_REL_ BCM1 SG_ 870 BM_Wischblinken 5000;
BA_REL_ "GenSigTimeoutTime" BU_SG_REL_ BCM1 SG_ 870 BM_PiloPa 5000;
BA_REL_ "GenSigTimeoutTime" BU_SG_REL_ BCM1 SG_ 901 CHA_Ziel_FahrPr_MO_BZS 5000;
BA_REL_ "GenSigTimeoutTime" BU_SG_REL_ BCM1 SG_ 901 CHA_Ziel_FahrPr_AFS 5000;
BA_REL_ "GenSigTimeoutTime" BU_SG_REL_ BCM1 SG_ 902 CHA_Drive_Select1_LED 5000;
BA_REL_ "GenSigTimeoutTime" BU_SG_REL_ BCM1 SG_ 902 CHA_Eco_Charisma_LED 5000;
BA_REL_ "GenSigTimeoutTime" BU_SG_REL_ BCM1 SG_ 902 CHA_Fahrer_Umschaltung 5000;
BA_REL_ "GenSigTimeoutTime" BU_SG_REL_ BCM1 SG_ 902 CHA_EV_LED 5000;
BA_REL_ "GenSigTimeoutTime" BU_SG_REL_ BCM1 SG_ 902 CHA_Ziel_FahrPr_AMB 5000;
BA_REL_ "GenSigTimeoutTime" BU_SG_REL_ BCM1 SG_ 902 CHA_Ziel_FahrPr_KL 5000;
BA_REL_ "GenSigTimeoutTime" BU_SG_REL_ BCM1 SG_ 902 CHA_Drehschalter_Istmodus 5000;
BA_REL_ "GenSigTimeoutTime" BU_SG_REL_ BCM1 SG_ 1000 CHA_Ziel_FahrPr_AV 5000;
BA_REL_ "GenSigTimeoutTime" BU_SG_REL_ BCM1 SG_ 1022 CHA_Ziel_FahrPr_PDC 5000;
BA_REL_ "GenSigTimeoutTime" BU_SG_REL_ BCM1 SG_ 1714 DGN_Verlernzaehler 5000;
BA_REL_ "GenSigTimeoutTime" BU_SG_REL_ BCM1 SG_ 1714 KBI_Kilometerstand 5000;
BA_REL_ "GenSigTimeoutTime" BU_SG_REL_ BCM1 SG_ 1714 UH_Jahr 5000;
BA_REL_ "GenSigTimeoutTime" BU_SG_REL_ BCM1 SG_ 1714 UH_Monat 5000;
BA_REL_ "GenSigTimeoutTime" BU_SG_REL_ BCM1 SG_ 1714 UH_Tag 5000;
BA_REL_ "GenSigTimeoutTime" BU_SG_REL_ BCM1 SG_ 1714 UH_Stunde 5000;
BA_REL_ "GenSigTimeoutTime" BU_SG_REL_ BCM1 SG_ 1714 UH_Minute 5000;
BA_REL_ "GenSigTimeoutTime" BU_SG_REL_ BCM1 SG_ 1714 UH_Sekunde 5000;
BA_REL_ "GenSigTimeoutTime" BU_SG_REL_ BCM1 SG_ 1714 Uhrzeit_01_alt 5000;
BA_REL_ "GenSigTimeoutTime" BU_SG_REL_ BCM1 SG_ 420 EA_Funktionsstatus 5000;
BA_REL_ "GenSigTimeoutTime" BU_SG_REL_ BCM1 SG_ 496 EA_Innenraumlicht_Anf 500;
BA_REL_ "GenSigTimeoutTime" BU_SG_REL_ BCM1 SG_ 2527679980 eCall_Statuslicht_Farbe2 5000;
BA_REL_ "GenSigTimeoutTime" BU_SG_REL_ BCM1 SG_ 2527679980 eCall_Statuslicht_Farbe1 5000;
BA_REL_ "GenSigTimeoutTime" BU_SG_REL_ BCM1 SG_ 2527679980 bCall_active 5000;
BA_REL_ "GenSigTimeoutTime" BU_SG_REL_ BCM1 SG_ 2527679980 eCall_Funktionsstatus_02 5000;
BA_REL_ "GenSigTimeoutTime" BU_SG_REL_ BCM1 SG_ 2527679980 eCall_Mute_Anf 5000;
BA_REL_ "GenSigTimeoutTime" BU_SG_REL_ BCM1 SG_ 1603 KBI_Einheit_Temp 5000;
BA_REL_ "GenSigTimeoutTime" BU_SG_REL_ BCM1 SG_ 260 EPB_Fehlerstatus_02 5000;
BA_REL_ "GenSigTimeoutTime" BU_SG_REL_ BCM1 SG_ 260 EPB_Status_02 5000;
BA_REL_ "GenSigTimeoutTime" BU_SG_REL_ Gateway SG_ 1448 BCM1_FlHz_Stufe_HR 5000;
BA_REL_ "GenSigTimeoutTime" BU_SG_REL_ Gateway SG_ 1448 BCM1_FlHz_Stufe_HL 5000;
BA_REL_ "GenSigTimeoutTime" BU_SG_REL_ Gateway SG_ 1448 BCM1_FlHz_Stufe_VR 5000;
BA_REL_ "GenSigTimeoutTime" BU_SG_REL_ Gateway SG_ 1448 BCM1_FlHz_Stufe_VL 5000;
BA_REL_ "GenSigTimeoutTime" BU_SG_REL_ Gateway SG_ 1448 BCM1_FlHz_Ruhesitz_HLR_Anf 5000;
BA_REL_ "GenSigTimeoutTime" BU_SG_REL_ Gateway SG_ 1448 BCM1_FlHz_VR_HLR_Anf 5000;
BA_REL_ "GenSigTimeoutTime" BU_SG_REL_ Gateway SG_ 1448 BCM1_FlHz_VL_HLR_Anf 5000;
BA_REL_ "GenSigTimeoutTime" BU_SG_REL_ Gateway SG_ 1448 BCM1_FlHz_HL_HLR_Anf 5000;
BA_REL_ "GenSigTimeoutTime" BU_SG_REL_ Gateway SG_ 1448 BCM1_FlHz_HR_HLR_Anf 5000;
BA_REL_ "GenSigTimeoutTime" BU_SG_REL_ Gateway SG_ 961 Heckrollo_Taster 2000;
BA_REL_ "GenSigTimeoutTime" BU_SG_REL_ Gateway SG_ 961 Drivesel_1_Taster 2000;
BA_REL_ "GenSigTimeoutTime" BU_SG_REL_ Gateway SG_ 961 Drivesel_2_Taster 2000;
BA_REL_ "GenSigTimeoutTime" BU_SG_REL_ Gateway SG_ 961 LIM_bCall_Taster 2000;
BA_REL_ "GenSigTimeoutTime" BU_SG_REL_ Gateway SG_ 961 eCall_Taste 2000;
BA_REL_ "GenSigTimeoutTime" BU_SG_REL_ Gateway SG_ 1432 BCM_BFS_Fernsteuerung_aktiv 5000;
BA_REL_ "GenSigTimeoutTime" BU_SG_REL_ Gateway SG_ 1432 BCM_FS_Programmwippe 5000;
BA_REL_ "GenSigTimeoutTime" BU_SG_REL_ Gateway SG_ 1432 BCM_BFS_Programmwippe 5000;
BA_REL_ "GenSigTimeoutTime" BU_SG_REL_ Gateway SG_ 1432 BCM_FS_Multif_Taster 5000;
BA_REL_ "GenSigTimeoutTime" BU_SG_REL_ Gateway SG_ 1432 BCM_BFS_Multif_Taster 5000;
BA_REL_ "GenSigTimeoutTime" BU_SG_REL_ Gateway SG_ 1432 BCM_FS_Massage_Taster 5000;
BA_REL_ "GenSigTimeoutTime" BU_SG_REL_ Gateway SG_ 1432 BCM_BFS_Massage_Taster 5000;
BA_REL_ "GenSigTimeoutTime" BU_SG_REL_ Gateway SG_ 1432 BCM_FS_Pneumatik_Verstellung 5000;
BA_REL_ "GenSigTimeoutTime" BU_SG_REL_ Gateway SG_ 1432 BCM_BFS_Pneumatik_Verstellung 5000;
BA_REL_ "GenSigTimeoutTime" BU_SG_REL_ Gateway SG_ 1520 DI_KL_58xd 2000;
BA_REL_ "GenSigTimeoutTime" BU_SG_REL_ Gateway SG_ 1520 DI_KL_58xs 2000;
BA_REL_ "GenSigTimeoutTime" BU_SG_REL_ Gateway_PAG SG_ 1448 BCM1_FlHz_Stufe_HR 5000;
BA_REL_ "GenSigTimeoutTime" BU_SG_REL_ Gateway_PAG SG_ 1448 BCM1_FlHz_Stufe_HL 5000;
BA_REL_ "GenSigTimeoutTime" BU_SG_REL_ Gateway_PAG SG_ 1448 BCM1_FlHz_Stufe_VR 5000;
BA_REL_ "GenSigTimeoutTime" BU_SG_REL_ Gateway_PAG SG_ 1448 BCM1_FlHz_Stufe_VL 5000;
BA_REL_ "GenSigTimeoutTime" BU_SG_REL_ Gateway_PAG SG_ 1448 BCM1_FlHz_Ruhesitz_HLR_Anf 5000;
BA_REL_ "GenSigTimeoutTime" BU_SG_REL_ Gateway_PAG SG_ 1448 BCM1_FlHz_VR_HLR_Anf 5000;
BA_REL_ "GenSigTimeoutTime" BU_SG_REL_ Gateway_PAG SG_ 1448 BCM1_FlHz_VL_HLR_Anf 5000;
BA_REL_ "GenSigTimeoutTime" BU_SG_REL_ Gateway_PAG SG_ 1448 BCM1_FlHz_HL_HLR_Anf 5000;
BA_REL_ "GenSigTimeoutTime" BU_SG_REL_ Gateway_PAG SG_ 1448 BCM1_FlHz_HR_HLR_Anf 5000;
BA_REL_ "GenSigTimeoutTime" BU_SG_REL_ Gateway_PAG SG_ 961 Heckrollo_Taster 2000;
BA_REL_ "GenSigTimeoutTime" BU_SG_REL_ Gateway_PAG SG_ 961 Drivesel_1_Taster 2000;
BA_REL_ "GenSigTimeoutTime" BU_SG_REL_ Gateway_PAG SG_ 961 Drivesel_2_Taster 2000;
BA_REL_ "GenSigTimeoutTime" BU_SG_REL_ Gateway_PAG SG_ 961 LIM_bCall_Taster 2000;
BA_REL_ "GenSigTimeoutTime" BU_SG_REL_ Gateway_PAG SG_ 961 eCall_Taste 2000;
BA_REL_ "GenSigTimeoutTime" BU_SG_REL_ Gateway_PAG SG_ 1432 BCM_BFS_Fernsteuerung_aktiv 5000;
BA_REL_ "GenSigTimeoutTime" BU_SG_REL_ Gateway_PAG SG_ 1432 BCM_FS_Programmwippe 5000;
BA_REL_ "GenSigTimeoutTime" BU_SG_REL_ Gateway_PAG SG_ 1432 BCM_BFS_Programmwippe 5000;
BA_REL_ "GenSigTimeoutTime" BU_SG_REL_ Gateway_PAG SG_ 1432 BCM_FS_Multif_Taster 5000;
BA_REL_ "GenSigTimeoutTime" BU_SG_REL_ Gateway_PAG SG_ 1432 BCM_BFS_Multif_Taster 5000;
BA_REL_ "GenSigTimeoutTime" BU_SG_REL_ Gateway_PAG SG_ 1432 BCM_FS_Massage_Taster 5000;
BA_REL_ "GenSigTimeoutTime" BU_SG_REL_ Gateway_PAG SG_ 1432 BCM_BFS_Massage_Taster 5000;
BA_REL_ "GenSigTimeoutTime" BU_SG_REL_ Gateway_PAG SG_ 1432 BCM_FS_Pneumatik_Verstellung 5000;
BA_REL_ "GenSigTimeoutTime" BU_SG_REL_ Gateway_PAG SG_ 1432 BCM_BFS_Pneumatik_Verstellung 5000;
BA_REL_ "GenSigTimeoutTime" BU_SG_REL_ Gateway_PAG SG_ 1520 DI_KL_58xd 2000;
BA_REL_ "GenSigTimeoutTime" BU_SG_REL_ Klima_MSB SG_ 1448 BCM1_FlHz_Stufe_HR 5000;
BA_REL_ "GenSigTimeoutTime" BU_SG_REL_ Klima_MSB SG_ 1448 BCM1_FlHz_Stufe_HL 5000;
BA_REL_ "GenSigTimeoutTime" BU_SG_REL_ Klima_MSB SG_ 1448 BCM1_FlHz_Stufe_VR 5000;
BA_REL_ "GenSigTimeoutTime" BU_SG_REL_ Klima_MSB SG_ 1448 BCM1_FlHz_Stufe_VL 5000;
BA_REL_ "GenSigTimeoutTime" BU_SG_REL_ Klima_MSB SG_ 401 BMS_SOC_HiRes 1000;
BA_REL_ "GenSigTimeoutTime" BU_SG_REL_ Klima_MSB SG_ 1442 BMS_IstModus 5000;
BA_REL_ "GenSigTimeoutTime" BU_SG_REL_ Klima_MSB SG_ 1438 BMS_Temperatur 5000;
BA_REL_ "GenSigTimeoutTime" BU_SG_REL_ Klima_MSB SG_ 2527679979 BMS_SOC_Kaltstart 5000;
BA_REL_ "GenSigTimeoutTime" BU_SG_REL_ Klima_MSB SG_ 1289 BMS_NutzbarerSOC 1000;
BA_REL_ "GenSigTimeoutTime" BU_SG_REL_ Klima_MSB SG_ 2527679654 BMS_IstTemperatur_hoechste 5000;
BA_REL_ "GenSigTimeoutTime" BU_SG_REL_ Klima_MSB SG_ 2527679654 BMS_IstTemperatur_niedrigste 5000;
BA_REL_ "GenSigTimeoutTime" BU_SG_REL_ Klima_MSB SG_ 2589283666 BMS_MMTR_Status 5000;
BA_REL_ "GenSigTimeoutTime" BU_SG_REL_ Klima_MSB SG_ 2463978838 BMS_ZellTemp_virtuell_max 1000;
BA_REL_ "GenSigTimeoutTime" BU_SG_REL_ Klima_MSB SG_ 2463978838 BMS_ZellTemp_virtuell_min 1000;
BA_REL_ "GenSigTimeoutTime" BU_SG_REL_ Klima_MSB SG_ 902 CHA_Fahrer_Umschaltung 5000;
BA_REL_ "GenSigTimeoutTime" BU_SG_REL_ Klima_MSB SG_ 902 CHA_Ziel_FahrPr_KL 5000;
BA_REL_ "GenSigTimeoutTime" BU_SG_REL_ Klima_MSB SG_ 1714 DGN_Verlernzaehler 5000;
BA_REL_ "GenSigTimeoutTime" BU_SG_REL_ Klima_MSB SG_ 1714 KBI_Kilometerstand 5000;
BA_REL_ "GenSigTimeoutTime" BU_SG_REL_ Klima_MSB SG_ 1714 UH_Jahr 5000;
BA_REL_ "GenSigTimeoutTime" BU_SG_REL_ Klima_MSB SG_ 1714 UH_Monat 5000;
BA_REL_ "GenSigTimeoutTime" BU_SG_REL_ Klima_MSB SG_ 1714 UH_Tag 5000;
BA_REL_ "GenSigTimeoutTime" BU_SG_REL_ Klima_MSB SG_ 1714 UH_Stunde 5000;
BA_REL_ "GenSigTimeoutTime" BU_SG_REL_ Klima_MSB SG_ 1714 UH_Minute 5000;
BA_REL_ "GenSigTimeoutTime" BU_SG_REL_ Klima_MSB SG_ 1714 UH_Sekunde 5000;
BA_REL_ "GenSigTimeoutTime" BU_SG_REL_ Klima_MSB SG_ 1603 KBI_Einheit_Temp 5000;
BA_REL_ "GenSigTimeoutTime" BU_SG_REL_ Lift_VA SG_ 1431 BED_Taster_Lift 5000;
BA_REL_ "GenSigTimeoutTime" BU_SG_REL_ Lift_VA SG_ 1000 CHA_Ziel_FahrPr_NR 5000;
BA_REL_ "GenSigTimeoutTime" BU_SG_REL_ Lift_VA SG_ 615 EFP_Niveauzustand_Lift 800;
BA_REL_ "GenSigTimeoutTime" BU_SG_REL_ Lift_VA SG_ 615 EFP_Verfuegbarkeit_Lift 800;
BA_REL_ "GenSigTimeoutTime" BU_SG_REL_ Lift_VA SG_ 615 EFP_Vorlaufzeit_Lift 800;
BA_REL_ "GenSigTimeoutTime" BU_SG_REL_ Lift_VA SG_ 1714 DGN_Verlernzaehler 5000;
BA_REL_ "GenSigTimeoutTime" BU_SG_REL_ Lift_VA SG_ 1714 KBI_Kilometerstand 5000;
BA_REL_ "GenSigTimeoutTime" BU_SG_REL_ Lift_VA SG_ 1714 UH_Jahr 5000;
BA_REL_ "GenSigTimeoutTime" BU_SG_REL_ Lift_VA SG_ 1714 UH_Monat 5000;
BA_REL_ "GenSigTimeoutTime" BU_SG_REL_ Lift_VA SG_ 1714 UH_Tag 5000;
BA_REL_ "GenSigTimeoutTime" BU_SG_REL_ Lift_VA SG_ 1714 UH_Stunde 5000;
BA_REL_ "GenSigTimeoutTime" BU_SG_REL_ Lift_VA SG_ 1714 UH_Minute 5000;
BA_REL_ "GenSigTimeoutTime" BU_SG_REL_ Lift_VA SG_ 1714 UH_Sekunde 5000;
BA_REL_ "GenSigTimeoutTime" BU_SG_REL_ VAS_L SG_ 870 BM_Warnblinken 5000;
BA_REL_ "GenSigTimeoutTime" BU_SG_REL_ VAS_L SG_ 870 BM_links 5000;
BA_REL_ "GenSigTimeoutTime" BU_SG_REL_ VAS_L SG_ 870 BM_rechts 5000;
BA_REL_ "GenSigTimeoutTime" BU_SG_REL_ VAS_L SG_ 870 Blinken_li_Fzg_Takt 5000;
BA_REL_ "GenSigTimeoutTime" BU_SG_REL_ VAS_L SG_ 870 Blinken_re_Fzg_Takt 5000;
BA_REL_ "GenSigTimeoutTime" BU_SG_REL_ VAS_L SG_ 1714 DGN_Verlernzaehler 5000;
BA_REL_ "GenSigTimeoutTime" BU_SG_REL_ VAS_L SG_ 1714 KBI_Kilometerstand 5000;
BA_REL_ "GenSigTimeoutTime" BU_SG_REL_ VAS_L SG_ 1714 UH_Jahr 5000;
BA_REL_ "GenSigTimeoutTime" BU_SG_REL_ VAS_L SG_ 1714 UH_Monat 5000;
BA_REL_ "GenSigTimeoutTime" BU_SG_REL_ VAS_L SG_ 1714 UH_Tag 5000;
BA_REL_ "GenSigTimeoutTime" BU_SG_REL_ VAS_L SG_ 1714 UH_Stunde 5000;
BA_REL_ "GenSigTimeoutTime" BU_SG_REL_ VAS_L SG_ 1714 UH_Minute 5000;
BA_REL_ "GenSigTimeoutTime" BU_SG_REL_ VAS_L SG_ 1714 UH_Sekunde 5000;
BA_REL_ "GenSigTimeoutTime" BU_SG_REL_ VAS_L SG_ 1714 Uhrzeit_01_alt 5000;
BA_REL_ "GenSigTimeoutTime" BU_SG_REL_ VAS_L SG_ 1520 DI_KL_58xd 2000;
BA_REL_ "GenSigTimeoutTime" BU_SG_REL_ VAS_L SG_ 1520 DI_Display_Nachtdesign 2000;
BA_REL_ "GenSigTimeoutTime" BU_SG_REL_ VAS_L SG_ 1520 DI_Fotosensor 2000;
BA_REL_ "GenSigTimeoutTime" BU_SG_REL_ VAS_R SG_ 870 BM_Warnblinken 5000;
BA_REL_ "GenSigTimeoutTime" BU_SG_REL_ VAS_R SG_ 870 BM_links 5000;
BA_REL_ "GenSigTimeoutTime" BU_SG_REL_ VAS_R SG_ 870 BM_rechts 5000;
BA_REL_ "GenSigTimeoutTime" BU_SG_REL_ VAS_R SG_ 870 Blinken_li_Fzg_Takt 5000;
BA_REL_ "GenSigTimeoutTime" BU_SG_REL_ VAS_R SG_ 870 Blinken_re_Fzg_Takt 5000;
BA_REL_ "GenSigTimeoutTime" BU_SG_REL_ VAS_R SG_ 1714 DGN_Verlernzaehler 5000;
BA_REL_ "GenSigTimeoutTime" BU_SG_REL_ VAS_R SG_ 1714 KBI_Kilometerstand 5000;
BA_REL_ "GenSigTimeoutTime" BU_SG_REL_ VAS_R SG_ 1714 UH_Jahr 5000;
BA_REL_ "GenSigTimeoutTime" BU_SG_REL_ VAS_R SG_ 1714 UH_Monat 5000;
BA_REL_ "GenSigTimeoutTime" BU_SG_REL_ VAS_R SG_ 1714 UH_Tag 5000;
BA_REL_ "GenSigTimeoutTime" BU_SG_REL_ VAS_R SG_ 1714 UH_Stunde 5000;
BA_REL_ "GenSigTimeoutTime" BU_SG_REL_ VAS_R SG_ 1714 UH_Minute 5000;
BA_REL_ "GenSigTimeoutTime" BU_SG_REL_ VAS_R SG_ 1714 UH_Sekunde 5000;
BA_REL_ "GenSigTimeoutTime" BU_SG_REL_ VAS_R SG_ 1714 Uhrzeit_01_alt 5000;
BA_REL_ "GenSigTimeoutTime" BU_SG_REL_ VAS_R SG_ 1520 DI_KL_58xd 2000;
BA_REL_ "GenSigTimeoutTime" BU_SG_REL_ VAS_R SG_ 1520 DI_Display_Nachtdesign 2000;
BA_REL_ "GenSigTimeoutTime" BU_SG_REL_ VAS_R SG_ 1520 DI_Fotosensor 2000;
VAL_ 1448 BCM1_FlHz_Stufe_HR 0 "Aus" 1 "Stufe_1" 2 "Stufe_2" 3 "Stufe_3" 4 "Stufe_4" 5 "Stufe_5" 6 "Stufe_6" ;
VAL_ 1448 BCM1_FlHz_Stufe_HL 0 "Aus" 1 "Stufe_1" 2 "Stufe_2" 3 "Stufe_3" 4 "Stufe_4" 5 "Stufe_5" 6 "Stufe_6" ;
VAL_ 1448 BCM1_FlHz_Stufe_VR 0 "Aus" 1 "Stufe_1" 2 "Stufe_2" 3 "Stufe_3" 4 "Stufe_4" 5 "Stufe_5" 6 "Stufe_6" ;
VAL_ 1448 BCM1_FlHz_Stufe_VL 0 "Aus" 1 "Stufe_1" 2 "Stufe_2" 3 "Stufe_3" 4 "Stufe_4" 5 "Stufe_5" 6 "Stufe_6" ;
VAL_ 1448 BCM1_FlHz_Ruhesitz_HLR_Anf 0 "0_Prozent" 1 "33_Prozent" 2 "66_Prozent" 3 "100_Prozent" ;
VAL_ 1448 BCM1_FlHz_VR_HLR_Anf 0 "0_Prozent" 1 "33_Prozent" 2 "66_Prozent" 3 "100_Prozent" ;
VAL_ 1448 BCM1_FlHz_VL_HLR_Anf 0 "0_Prozent" 1 "33_Prozent" 2 "66_Prozent" 3 "100_Prozent" ;
VAL_ 1448 BCM1_FlHz_HL_HLR_Anf 0 "0_Prozent" 1 "33_Prozent" 2 "66_Prozent" 3 "100_Prozent" ;
VAL_ 1448 BCM1_FlHz_HR_HLR_Anf 0 "0_Prozent" 1 "33_Prozent" 2 "66_Prozent" 3 "100_Prozent" ;
VAL_ 1448 BCM1_FlHz_HBFS_PWM_B 101 "100_Prozent_PWM_SpgUnkompensiert" 127 "FnAbbruch_Slave_zuruecksetzen" ;
VAL_ 1448 BCM1_FlHz_HBFS_PWM_A 101 "100_Prozent_PWM_SpgUnkompensiert" 127 "FnAbbruch_Slave_zuruecksetzen" ;
VAL_ 1448 BCM1_FlHz_BFS_PWM_B 101 "100_Prozent_PWM_SpgUnkompensiert" 127 "FnAbbruch_Slave_zuruecksetzen" ;
VAL_ 1448 BCM1_FlHz_BFS_PWM_A 101 "100_Prozent_PWM_SpgUnkompensiert" 127 "FnAbbruch_Slave_zuruecksetzen" ;
VAL_ 961 Heckrollo_2_Taster 0 "Taste_nicht_betaetigt" 1 "Taste_entprellt_betaetigt" 2 "Init_oder_nicht_verbaut" 3 "Fehler" ;
VAL_ 961 APS_Taster 0 "Taste_nicht_betaetigt" 1 "Taste_entprellt_betaetigt" 2 "Init_oder_nicht_verbaut" 3 "Fehler" ;
VAL_ 961 PLA_Taster 0 "Taste_nicht_betaetigt" 1 "Taste_entprellt_betaetigt" 2 "Init_oder_nicht_verbaut" 3 "Fehler" ;
VAL_ 961 ESP_Off_Taster 0 "Taste_nicht_betaetigt" 1 "Taste_entprellt_betaetigt" 2 "Init_oder_nicht_verbaut" 3 "Fehler" ;
VAL_ 961 HDC_Taster 0 "Taste_nicht_betaetigt" 1 "Taste_entprellt_betaetigt" 2 "Init_oder_nicht_verbaut" 3 "Fehler" ;
VAL_ 961 AVH_Taster 0 "Taste_nicht_betaetigt" 1 "Taste_entprellt_betaetigt" 2 "Init_oder_nicht_verbaut" 3 "Fehler" ;
VAL_ 961 Display_Taster 0 "Taste_nicht_betaetigt" 1 "Taste_entprellt_betaetigt" 2 "Init_oder_nicht_verbaut" 3 "Fehler" ;
VAL_ 961 Heckrollo_Taster 0 "Taste_nicht_betaetigt" 1 "Taste_entprellt_betaetigt" 2 "Init_oder_nicht_verbaut" 3 "Fehler" ;
VAL_ 961 Spoiler_Taster 0 "Taste_nicht_betaetigt" 1 "Taste_entprellt_betaetigt" 2 "Init_oder_nicht_verbaut" 3 "Fehler" ;
VAL_ 961 Drivesel_1_Taster 0 "Taste_nicht_betaetigt" 1 "Taste_entprellt_betaetigt" 2 "Init_oder_nicht_verbaut" 3 "Fehler" ;
VAL_ 961 Drivesel_2_Taster 0 "Taste_nicht_betaetigt" 1 "Taste_entprellt_betaetigt" 2 "Init_oder_nicht_verbaut" 3 "Fehler" ;
VAL_ 961 Sideview_Taster 0 "Taste_nicht_betaetigt" 1 "Taste_entprellt_betaetigt" 2 "Init_oder_nicht_verbaut" 3 "Fehler" ;
VAL_ 961 LKS_Taster 0 "Taste_nicht_betaetigt" 1 "Taste_betaetigt" 2 "INIT_Taste_nicht_verbaut" 3 "Fehler" ;
VAL_ 961 SWA_Taster 0 "nicht_betaetigt" 1 "betaetigt" 2 "nicht_vorhanden" 3 "Fehler" ;
VAL_ 961 LIM_bCall_Taster 0 "nicht_betaetigt" 1 "betaetigt" ;
VAL_ 961 eCall_Taste 0 "button_released" 1 "button_pressed" 2 "discrete_line_broken" 3 "Fehler" ;
VAL_ 961 PLA_Taster_Fehler_Roh 0 "kein Fehler vorhanden" 1 "Fehler vorhanden" ;
VAL_ 961 LIM_PAO_ON_Status 0 "LED aus" 1 "LED an" 2 "LED blinkt" 3 "LED defekt" ;
VAL_ 961 LIM_PAO_OFF_Status 0 "LED aus" 1 "LED an" 2 "LED blinkt" 3 "LED defekt" ;
VAL_ 961 LIM_PAO_Schriftzug_Status 0 "LED aus" 1 "LED an" 2 "LED blinkt" 3 "LED defekt" ;
VAL_ 961 Spoiler_LED_Status 0 "LED_aus" 1 "LED_ein" 2 "LED_blinken" 3 "Fehler" ;
VAL_ 961 AVH_LED_Status 0 "LED_aus" 1 "LED_ein" 2 "LED_blinken" 3 "Fehler" ;
VAL_ 961 HDC_LED_Status 0 "LED_aus" 1 "LED_ein" 2 "LED_blinken" 3 "Fehler" ;
VAL_ 961 PLA_LED_Status 0 "LED_aus" 1 "LED_ein" 2 "LED_blinken" 3 "Fehler" ;
VAL_ 961 APS_LED_Status 0 "LED_aus" 1 "LED_ein" 2 "LED_blinken" 3 "Fehler" ;
VAL_ 1432 BCM_BFS_Fernsteuerung_aktiv 0 "inaktiv" 1 "aktiv" ;
VAL_ 1432 BCM_Soundklappe_Taster 0 "Taster_nicht_Betaetigt" 1 "Taster_Betaetigt" ;
VAL_ 1432 E_Sound_LED_Status 0 "LED_aus" 1 "LED_ein" 2 "LED_blinken" 3 "Fehler" ;
VAL_ 1432 Pilot_Taster 0 "Taste_nicht_betaetigt" 1 "Taste_entprellt_betaetigt" 2 "Init_oder_nicht_verbaut" 3 "Fehler" ;
VAL_ 1432 BCM1_eSound_Taster 0 "Taste_nicht_betaetigt" 1 "Taste_entprellt_betaetigt" 2 "Init_oder_nicht_verbaut" 3 "Fehler" ;
VAL_ 1432 BCM_FS_Programmwippe 0 "Taster_unbetaetigt" 1 "Taster_betaetigt" ;
VAL_ 1432 BCM_BFS_Programmwippe 0 "Taster_unbetaetigt" 1 "Taster_betaetigt" ;
VAL_ 1432 BCM_FS_Multif_Taster 0 "Taster_unbetaetigt" 1 "Taster_betaetigt" ;
VAL_ 1432 BCM_BFS_Multif_Taster 0 "Taster_unbetaetigt" 1 "Taster_betaetigt" ;
VAL_ 1432 BCM_FS_Massage_Taster 0 "Taster_unbetaetigt" 1 "Taster_betaetigt" ;
VAL_ 1432 BCM_BFS_Massage_Taster 0 "Taster_unbetaetigt" 1 "Taster_betaetigt" ;
VAL_ 1432 BCM_FS_Pneumatik_Verstellung 0 "keine_Verstellung" 1 "Pneumatikverstellung_aktiv" ;
VAL_ 1432 BCM_BFS_Pneumatik_Verstellung 0 "keine_Verstellung" 1 "Pneumatikverstellung_aktiv" ;
VAL_ 1432 LIM_Rear_Mode 0 "inaktiv" 1 "aktiv" ;
VAL_ 1432 BCM1_NR_Ride_Height_Up_Taster 0 "Taste_nicht_betaetigt" 1 "Taste_entprellt_betaetigt" 2 "Init_oder_nicht_verbaut" 3 "Fehler" ;
VAL_ 1432 BCM1_NR_Ride_Height_Down_Taster 0 "Taste_nicht_betaetigt" 1 "Taste_entprellt_betaetigt" 2 "Init_oder_nicht_verbaut" 3 "Fehler" ;
VAL_ 1432 LIM_S_Rollo_vo 0 "nicht_betaetigt" 1 "man_zu" 2 "auto_zu" 3 "man_auf" 4 "auto_auf" 5 "stop" 6 "fehler_schalter_haengt" 7 "fehler_schalter_unplausibel" ;
VAL_ 1432 LIM_S_Rollo_hi 0 "nicht_betaetigt" 1 "man_zu" 2 "auto_zu" 3 "man_auf" 4 "auto_auf" 5 "stop" 6 "fehler_schalter_haengt" 7 "fehler_schalter_unplausibel" ;
VAL_ 1432 LIM_S_SAD_Vo 0 "nicht_betaetigt" 1 "man_sl_zu" 2 "auto_sl_zu" 3 "man_sl_auf" 4 "auto_sl_auf" 5 "man_al_auf" 6 "auto_al_auf" 7 "man_al_zu" 8 "auto_al_zu" 9 "stop" 10 "Toggle_Taster_AL_betaetigt" 14 "fehler_schalter_haengt" 15 "fehler_schalter_unplausibel" ;
VAL_ 1432 LIM_S_SAD_hi 0 "nicht_betaetigt" 1 "man_sl_zu" 2 "auto_sl_zu" 3 "man_sl_auf" 4 "auto_sl_auf" 5 "man_al_auf" 6 "auto_al_auf" 7 "man_al_zu" 8 "auto_al_zu" 14 "fehler_schalter_haengt" 15 "fehler_schalter_unplausibel" ;
VAL_ 1431 BED_Taster_VD_Oeffnen 0 "Taste_nicht_betaetigt" 1 "Taste_entprellt_betaetigt" 2 "Init_oder_nicht_verbaut" 3 "Fehler" ;
VAL_ 1431 BED_Taster_VD_Schliessen 0 "Taste_nicht_betaetigt" 1 "Taste_entprellt_betaetigt" 2 "Init_oder_nicht_verbaut" 3 "Fehler" ;
VAL_ 1431 BED_Taster_Windschott 0 "Taste_nicht_betaetigt" 1 "Taste_entprellt_betaetigt" 2 "Init_oder_nicht_verbaut" 3 "Fehler" ;
VAL_ 1431 BED_SAD_vo 0 "nicht_betaetigt" 1 "man_sl_zu" 2 "auto_sl_zu" 3 "man_sl_auf" 4 "auto_sl_auf" 5 "man_al_auf" 6 "auto_al_auf" 7 "man_al_zu" 8 "auto_al_zu" 14 "fehler_schalter_haengt" 15 "fehler_schalter_unplausibel" ;
VAL_ 1431 BED_Rollo_vo 0 "nicht_betaetigt" 1 "man_zu" 2 "auto_zu" 3 "man_auf" 4 "auto_auf" 6 "fehler_schalter_haengt" 7 "fehler_schalter_unplausibel" ;
VAL_ 1431 BED_Taster_Lift 0 "Taste_nicht_betaetigt" 1 "Taste_entprellt_betaetigt" 2 "Init_oder_nicht_verbaut" 3 "Fehler" ;
VAL_ 1431 SoSe_SunInt_2D_Re_Dash 254 "Init" 255 "Fehler" ;
VAL_ 1431 SoSe_SunInt_2D_Li_Dash 254 "Init" 255 "Fehler" ;
VAL_ 1431 BED_Taster_Fahrwerk 0 "Taste_nicht_betaetigt" 1 "Taste_entprellt_betaetigt" ;
VAL_ 870 BM_ZV_auf 0 "inaktiv" 1 "aktiv" ;
VAL_ 870 BM_ZV_zu 0 "inaktiv" 1 "aktiv" ;
VAL_ 870 BM_DWA_ein 0 "inaktiv" 1 "aktiv" ;
VAL_ 870 BM_DWA_Alarm 0 "inaktiv" 1 "aktiv" ;
VAL_ 870 BM_Crash 0 "inaktiv" 1 "aktiv" ;
VAL_ 870 BM_Panik 0 "inaktiv" 1 "aktiv" ;
VAL_ 870 BM_Not_Bremsung 0 "kein_blinken" 1 "Notbremswarnblinken_aktiv" ;
VAL_ 870 BM_GDO 0 "inaktiv" 1 "aktiv" ;
VAL_ 870 BM_Warnblinken 0 "inaktiv" 1 "aktiv" ;
VAL_ 870 BM_Taxi_Notalarm 0 "inaktiv" 1 "aktiv" ;
VAL_ 870 BM_Telematik 0 "inaktiv" 1 "aktiv" ;
VAL_ 870 BM_links 0 "inaktiv" 1 "aktiv" ;
VAL_ 870 BM_rechts 0 "inaktiv" 1 "aktiv" ;
VAL_ 870 Blinken_li_Fzg_Takt 0 "Blinker_links_ausgeschaltet" 1 "Blinker_links_eingeschaltet" ;
VAL_ 870 Blinken_re_Fzg_Takt 0 "Blinker_rechts_ausgeschaltet" 1 "Blinker_rechts_eingeschaltet" ;
VAL_ 870 Blinken_li_Kombi_Takt 0 "Blinkerkontrolllampe_links_ausgeschaltet" 1 "Blinkerkontrolllampe_links_eingeschaltet" ;
VAL_ 870 Blinken_re_Kombi_Takt 0 "Blinkerkontrolllampe_rechts_ausgeschaltet" 1 "Blinkerkontrolllampe_rechts_eingeschaltet" ;
VAL_ 870 BM_NBA_n_codiert_n_aktiv 0 "codiert_AND_kein_Fehler" 1 "nicht_codiert_OR_Fehler_erkannt" ;
VAL_ 870 BM_NBA_Status 0 "NBA_nicht_aktiv" 1 "BRL_Dunkelphase" 3 "BRL_Hellphase" ;
VAL_ 870 BM_WBT_Beleuchtung 0 "inaktiv" 1 "aktiv" ;
VAL_ 870 BM_HD_Oeffnung_angelernt 0 "keine_Quittierung" 1 "Quittierung" ;
VAL_ 870 BM_Autobahn 0 "inaktiv" 1 "aktiv" ;
VAL_ 870 BM_Rollenmodus_Blinken 0 "inaktiv" 1 "aktiv" ;
VAL_ 870 BM_Recas 0 "kein_blinken" 1 "Recasblinken_aktiv" ;
VAL_ 870 BM_Wischblinken 0 "inaktiv" 1 "aktiv" ;
VAL_ 870 BM_Telematik_Abbruchgrund 0 "Init" 1 "speed_out_of_range" 2 "defect" 3 "clamp_s_on" 4 "clamp_15_on" 5 "door_open" 6 "engine_hood_open" 7 "trunk_open" 8 "convertible_top_not_locked" 9 "horn_activated_by_user" 10 "Higher_Prioritiy_Function_active" 11 "Central_Lock_status_changed" 12 "Request_Dropped_by_Requester" 13 "Service_Duration_Expired" 14 "not_possible_due_to_coding" 15 "no_reason_or_unknown_timeout" ;
VAL_ 870 BM_PiloPa 0 "PiloPa_Blinkerquittierung_inaktiv" 1 "PiloPa_Blinkerquittierung_aktiv" ;
VAL_ 870 DWA_Alarmquelle 0 "kein_Ausloesegrund" 1 "Tuerkontakt_Fahrertuer" 2 "Tuerkontakt_Beifahrertuer" 3 "Tuerkontakt_hinten_links" 4 "Tuerkontakt_hinten_rechts" 5 "Motorhaubenkontakt_vorne" 6 "Kofferraum_hinten" 7 "Masseschleife_der_Heckscheibe" 8 "Innenraumueberwachung" 9 "Alarm_durch_Noteinstieg" 10 "Sounder" 11 "Neigungssensor" 12 "TSG_FT_am_CAN_Bus" 13 "TSG_BT_am_CAN_Bus" 14 "TSG_HFS_am_CAN_Bus" 15 "TSG_HBFS_am_CAN_Bus" 16 "Klemme_15" 17 "Klemme_15sig" 18 "frei" 19 "Anhaengerueberwachung" 20 "Scheinwerferueberwachung_links" 21 "Scheinwerferueberwachung_rechts" 22 "Handschuhkasten" 23 "Verdeckueberwachung" 24 "OBD_Alarm" 25 "Power_on_Reset" 30 "Init" 31 "Fehler" ;
VAL_ 868 NBlinken_li_Fzg_Takt 0 "Blinker_links_ausgeschaltet" 1 "Blinker links eingeschaltet" ;
VAL_ 868 NBlinken_re_Fzg_Takt 0 "Blinker rechts ausgeschaltet" 1 "Blinker rechts eingeschaltet" ;
VAL_ 868 NBlinken_li_Kombi_Takt 0 "Blinkerkontrolllampe_links_ausgeschaltet" 1 "Blinkerkontrolllampe_links_eingeschaltet" ;
VAL_ 868 NBlinken_re_Kombi_Takt 0 "Blinkerkontrolllampe rechts ausgeschaltet" 1 "Blinkerkontrolllampe rechts eingeschaltet" ;
VAL_ 401 BMS_IstStrom_02 4094 "Init" 4095 "Fehler" ;
VAL_ 401 BMS_IstSpannung 4094 "Init" 4095 "Fehler" ;
VAL_ 401 BMS_Spannung_ZwKr 2046 "Init" 2047 "Fehler" ;
VAL_ 401 BMS_SOC_HiRes 2046 "Init" 2047 "Fehler" ;
VAL_ 401 BMS_IstStrom_02_OffsetVZ 0 "Minus" 1 "Plus" ;
VAL_ 1442 BMS_Status_ServiceDisconnect 0 "gesteckt" 1 "gezogen" ;
VAL_ 1442 BMS_Status_Spgfreiheit 0 "Init" 1 "HV_Komponente_spannungsfrei" 2 "HV_Komp_nicht_spannungsfrei" 3 "Fehler_nicht_spannungsfrei" ;
VAL_ 1442 BMS_OBD_Lampe_Anf 0 "kein_MIL_Request" 1 "MIL_Request" ;
VAL_ 1442 BMS_IstModus 0 "HV_inaktiv" 1 "Fahren_HV_aktiv" 2 "stBalancing" 3 "externes_Laden" 4 "AC_Laden" 5 "Error_Batt" 6 "DC_Laden" 7 "Init" ;
VAL_ 1442 BMS_Fehlerstatus 0 "Komponente_IO" 1 "Eingeschr_KompFkt_Isofehler_I" 2 "Eingeschr_KompFkt_Isofehler_II" 3 "Eingeschr_KompFkt_Interlock" 4 "Eingeschr_KompFkt_SD" 5 "Eingeschr_KompFkt_Leistungsred" 6 "Keine_Komponentenfunktion" 7 "Init" ;
VAL_ 1442 BMS_Kapazitaet_02 2047 "Init" ;
VAL_ 1442 BMS_Abschaltankuendigung 1022 "keine_Abschaltung" 1023 "Fehler" ;
VAL_ 1442 BMS_Soll_SOC_HiRes 2046 "Init" 2047 "Fehler" ;
VAL_ 1438 BMS_Temperierung_Anf 0 "hoher_Kuehlbedarf" 1 "mittlerer_Kuehlbedarf" 2 "niedriger_Kuehlbedarf" 3 "kein_Temperierungsbedarf_Init" 4 "niedriger_Heizbedarf" 5 "mittlerer_Heizbedarf" 6 "hoher_Heizbedarf" 7 "Umwaelzungsbedarf" ;
VAL_ 1438 BMS_Status_Ventil 0 "Ventil_nicht_angesteuert" 1 "Ventil_angesteuert" 2 "reserviert" 3 "reserviert" 4 "reserviert" 5 "Ventil_nicht_verbaut" 6 "Init" 7 "Fehler" ;
VAL_ 1438 BMS_Soll_PWM_Pumpe 14 "Fehler" 15 "Init" ;
VAL_ 1438 BMS_Temperatur 254 "Init" 255 "Fehler" ;
VAL_ 1438 BMS_IstVorlaufTemperatur 254 "Init" 255 "Fehler" ;
VAL_ 1438 BMS_Fehler_NTKreis 0 "kein_Fehler" 1 "Fehler" ;
VAL_ 1438 BMS_Fehlerstatus_EWP_02 0 "Diagnose_nicht_durchgefuehrt" 1 "Pumpe_iO" 2 "Diagnose_laeuft" 3 "Pumpe_iO_Diagnose_laeuft" 4 "Blockade_Trockenlauf" 5 "Pumpe_stromlos" 6 "Blockade_Trockenlauf_Diag_laeuft" 7 "Fehler" ;
VAL_ 1438 BMS_SollVolumenstrom 62 "Init" 63 "Fehler" ;
VAL_ 1438 BMS_Batterie_Voko_Anf 0 "keine_Voko_angefordert" 1 "Voko_angefordert" ;
VAL_ 1438 BMS_SollVorlauftemperatur 254 "Init" 255 "Fehler" ;
VAL_ 1438 BMS_IstRuecklaufTemperatur_02 254 "Init" 255 "Fehler" ;
VAL_ 2527679979 BMS_BCCM_Anforderung 0 "Inaktiv" 1 "Aktiv" 2 "Init" 3 "Fehler" ;
VAL_ 2527679979 BMS_HV_Auszeit_Status 0 "Abstellzeit_nicht_berechnet" 1 "Abstellzeit_berechnet" 2 "Abstellzeit_Minimalwert" 3 "Abstellzeit_ungültig" ;
VAL_ 2527679979 BMS_HV_Auszeit 510 "Init" 511 "Fehler" ;
VAL_ 2527679979 BMS_Kapazitaet 2047 "Init" ;
VAL_ 2527679979 BMS_SOC_Kaltstart 2046 "Init" 2047 "Fehler" ;
VAL_ 2527679979 BMS_max_Grenz_SOC 31 "Init" ;
VAL_ 2527679979 BMS_min_Grenz_SOC 31 "Init" ;
VAL_ 1289 BMS_Energieinhalt_HiRes 32766 "Init" 32767 "Fehler" ;
VAL_ 1289 BMS_MaxEnergieinhalt_HiRes 32766 "Init" 32767 "Fehler" ;
VAL_ 1289 BMS_NutzbarerSOC 254 "Init" 255 "Fehler" ;
VAL_ 1289 BMS_NutzbarerEnergieinhalt 4094 "Init" 4095 "Fehler" ;
VAL_ 1289 BMS_Pred_Entladeperformance 126 "Init" 127 "Fehler" ;
VAL_ 1289 BMS_Pred_Ladeperformance 126 "Init" 127 "Fehler" ;
VAL_ 2527679654 BMS_IsoZustand 0 "Init_kein_Diagnoseergebnis" 1 "groesser_Schwelle_1" 2 "kleiner_Schwelle_1_gesamt" 3 "kleiner_Schwelle_1_intern" 4 "kleiner_Schwelle_2_gesamt" 5 "kleiner_Schwelle_2_intern" 6 "kein_Messwert" 7 "Messung_aktiv" ;
VAL_ 2527679654 BMS_IsoFehler 0 "Init" 1 "kein_IsoFehler" 2 "IsoFehler_Schwelle_1" 3 "IsoFehler_Schwelle_2" 4 "IWU_defekt" 5 "reserviert" 6 "reserviert" 7 "reserviert" ;
VAL_ 2527679654 BMS_IstTemperatur_hoechste 253 "reserviert" 254 "Init" 255 "Fehler" ;
VAL_ 2527679654 BMS_IstTemperatur_niedrigste 253 "reserviert" 254 "Init" 255 "Fehler" ;
VAL_ 2527679654 BMS_IstZellspannung_hoechste 4092 "reserviert" 4093 "reserviert" 4094 "Init" 4095 "Fehler" ;
VAL_ 2527679654 BMS_IstZellspannung_niedrigste 4092 "reserviert" 4093 "reserviert" 4094 "Init" 4095 "Fehler" ;
VAL_ 2589283666 BMS_MMTR_Status 0 "Nicht_verfuegbar" 1 "Inaktiv" 2 "Aktiv_Vorkonditionierung" 3 "Aktiv_TrackSession" 4 "Nicht_verfuegb_Lebensdauertimer" 5 "Abgeschlossen_Vorkonditionierung" 6 "Aktiv_Rueckkehrstrategie" 14 "Init" 15 "Fehler" ;
VAL_ 2589283666 BMS_LadegrenzeAntw_SOC 126 "Init" 127 "Fehler" ;
VAL_ 2589283666 BMS_EnergieAntw_Zaehler 14 "Init" 15 "Fehler" ;
VAL_ 2589283666 BMS_EnergieAntw_Energie 2046 "Init" 2047 "Fehler" ;
VAL_ 2589283666 BMS_LadegrenzeAntw_Leistung 4094 "Init" 4095 "Fehler" ;
VAL_ 2589283666 BMS_LadegrenzeAntw_Zaehler 14 "Init" 15 "Fehler" ;
VAL_ 2463978838 BMS_ZellTemp_virtuell_max 253 "Nicht_verfuegbar" 254 "Init" 255 "Fehler" ;
VAL_ 2463978838 BMS_ZellTemp_virtuell_min 253 "Nicht_verfuegbar" 254 "Init" 255 "Fehler" ;
VAL_ 2463978838 BMS_NutzbarerEnergieinhalt_HiRes 0 "nicht_verbaut" 32766 "Init" 32767 "Fehler" ;
VAL_ 901 CHA_Ziel_FahrPr_AGA 0 "keine_Funktion" 1 "Programm_1" 2 "Programm_2" 3 "Programm_3" 4 "Programm_4" 5 "Programm_5" 6 "Programm_6" 7 "Programm_7" 8 "Programm_8" 9 "Programm_9" 10 "Programm_10" 11 "Programm_11" 12 "Programm_12" 13 "Programm_13" 14 "Programm_14" 15 "Programm_15" ;
VAL_ 901 CHA_Ziel_FahrPr_ESP 0 "keine_Funktion" 1 "Programm_1" 2 "Programm_2" 3 "Programm_3" 4 "Programm_4" 5 "Programm_5" 6 "Programm_6" 7 "Programm_7" 8 "Programm_8" 9 "Programm_9" 10 "Programm_10" 11 "Programm_11" 12 "Programm_12" 13 "Programm_13" 14 "Programm_14" 15 "Programm_15" ;
VAL_ 901 CHA_Ziel_FahrPr_Freilauf 0 "keine_Funktion" 1 "Programm_1" 2 "Programm_2" 3 "Programm_3" 4 "Programm_4" 5 "Programm_5" 6 "Programm_6" 7 "Programm_7" 8 "Programm_8" 9 "Programm_9" 10 "Programm_10" 11 "Programm_11" 12 "Programm_12" 13 "Programm_13" 14 "Programm_14" 15 "Programm_15" ;
VAL_ 901 CHA_Fahrer_Umschaltung 0 "keine_oder_automatische_Umschaltung" 1 "manuelle_Umschaltung" ;
VAL_ 901 CHA_Fahrer_Umschaltung_BMA 0 "keine_oder_autom_Umschaltung" 1 "manuelle_Umschaltung" ;
VAL_ 901 CHA_Ziel_FahrPr_MO 0 "keine_Funktion" 1 "Programm_1" 2 "Programm_2" 3 "Programm_3" 4 "Programm_4" 5 "Programm_5" 6 "Programm_6" 7 "Programm_7" 8 "Programm_8" 9 "Programm_9" 10 "Programm_10" 11 "Programm_11" 12 "Programm_12" 13 "Programm_13" 14 "Programm_14" 15 "Programm_15" ;
VAL_ 901 CHA_Ziel_FahrPr_GE 0 "keine_Funktion" 1 "Programm_1" 2 "Programm_2" 3 "Programm_3" 4 "Programm_4" 5 "Programm_5" 6 "Programm_6" 7 "Programm_7" 8 "Programm_8" 9 "Programm_9" 10 "Programm_10" 11 "Programm_11" 12 "Programm_12" 13 "Programm_13" 14 "Programm_14" 15 "Programm_15" ;
VAL_ 901 CHA_Ziel_FahrPr_ALR 0 "keine_Funktion" 1 "Programm_1" 2 "Programm_2" 3 "Programm_3" 4 "Programm_4" 5 "Programm_5" 6 "Programm_6" 7 "Programm_7" 8 "Programm_8" 9 "Programm_9" 10 "Programm_10" 11 "Programm_11" 12 "Programm_12" 13 "Programm_13" 14 "Programm_14" 15 "Programm_15" ;
VAL_ 901 CHA_Ziel_FahrPr_MO_BZS 0 "keine_Funktion" 1 "Programm_1" 2 "Programm_2" 3 "Programm_3" 4 "Programm_4" 5 "Programm_5" 6 "Programm_6" 7 "Programm_7" 8 "Programm_8" 9 "Programm_9" 10 "Programm_10" 11 "Programm_11" 12 "Programm_12" 13 "Programm_13" 14 "Programm_14" 15 "Programm_15" ;
VAL_ 901 CHA_Ziel_FahrPr_DR 0 "keine_Funktion" 1 "Programm_1" 2 "Programm_2" 3 "Programm_3" 4 "Programm_4" 5 "Programm_5" 6 "Programm_6" 7 "Programm_7" 8 "Programm_8" 9 "Programm_9" 10 "Programm_10" 11 "Programm_11" 12 "Programm_12" 13 "Programm_13" 14 "Programm_14" 15 "Programm_15" ;
VAL_ 901 CHA_Ziel_FahrPr_VAQ 0 "keine_Funktion" 1 "Programm_1" 2 "Programm_2" 3 "Programm_3" 4 "Programm_4" 5 "Programm_5" 6 "Programm_6" 7 "Programm_7" 8 "Programm_8" 9 "Programm_9" 10 "Programm_10" 11 "Programm_11" 12 "Programm_12" 13 "Programm_13" 14 "Programm_14" 15 "Programm_15" ;
VAL_ 901 CHA_Ziel_FahrPr_AFS 0 "keine_Funktion" 1 "Programm_1" 2 "Programm_2" 3 "Programm_3" 4 "Programm_4" 5 "Programm_5" 6 "Programm_6" 7 "Programm_7" 8 "Programm_8" 9 "Programm_9" 10 "Programm_10" 11 "Programm_11" 12 "Programm_12" 13 "Programm_13" 14 "Programm_14" 15 "Programm_15" ;
VAL_ 901 CHA_Ziel_FahrPr_PreCrash 0 "keine_Funktion" 1 "Programm_1" 2 "Programm_2" 3 "Programm_3" 4 "Programm_4" 5 "Programm_5" 6 "Programm_6" 7 "Programm_7" 8 "Programm_8" 9 "Programm_9" 10 "Programm_10" 11 "Programm_11" 12 "Programm_12" 13 "Programm_13" 14 "Programm_14" 15 "Programm_15" ;
VAL_ 901 CHA_Ziel_FahrPr_EPS 0 "keine_Funktion" 1 "Programm_1" 2 "Programm_2" 3 "Programm_3" 4 "Programm_4" 5 "Programm_5" 6 "Programm_6" 7 "Programm_7" 8 "Programm_8" 9 "Programm_9" 10 "Programm_10" 11 "Programm_11" 12 "Programm_12" 13 "Programm_13" 14 "Programm_14" 15 "Programm_15" ;
VAL_ 901 CHA_Ziel_FahrPr_ACC 0 "keine_Funktion" 1 "Programm_1" 2 "Programm_2" 3 "Programm_3" 4 "Programm_4" 5 "Programm_5" 6 "Programm_6" 7 "Programm_7" 8 "Programm_8" 9 "Programm_9" 10 "Programm_10" 11 "Programm_11" 12 "Programm_12" 13 "Programm_13" 14 "Programm_14" 15 "Programm_15" ;
VAL_ 901 CHA_Ziel_FahrPr_SAK 0 "keine_Funktion" 1 "Programm_1" 2 "Programm_2" 3 "Programm_3" 4 "Programm_4" 5 "Programm_5" 6 "Programm_6" 7 "Programm_7" 8 "Programm_8" 9 "Programm_9" 10 "Programm_10" 11 "Programm_11" 12 "Programm_12" 13 "Programm_13" 14 "Programm_14" 15 "Programm_15" ;
VAL_ 901 CHA_Ziel_FahrPr_MO_StSt 0 "keine_Funktion" 1 "Programm_1" 2 "Programm_2" 3 "Programm_3" 4 "Programm_4" 5 "Programm_5" 6 "Programm_6" 7 "Programm_7" 8 "Programm_8" 9 "Programm_9" 10 "Programm_10" 11 "Programm_11" 12 "Programm_12" 13 "Programm_13" 14 "Programm_14" 15 "Programm_15" ;
VAL_ 902 CHA_Drive_Select1_LED 0 "LED_aus" 1 "LED_ein" 2 "LED_blinken" 3 "init" ;
VAL_ 902 CHA_Eco_Charisma_LED 0 "LED_aus_und_Blinken_aus" 1 "LED_ein_und_Blinken_aus" 2 "LED_ein_und_Blinken_ein_50_percent" 3 "reserviert" ;
VAL_ 902 CHA_Fahrer_Umschaltung 0 "keine_oder_automatische_Umschaltung" 1 "manuelle_Umschaltung" ;
VAL_ 902 CHA_EV_LED 0 "LED_aus" 1 "LED_an" ;
VAL_ 902 CHA_Ziel_FahrPr_AMB 0 "keine_Funktion" 1 "Programm_1" 2 "Programm_2" 3 "Programm_3" 4 "Programm_4" 5 "Programm_5" 6 "Programm_6" 7 "Programm_7" 8 "Programm_8" 9 "Programm_9" 10 "Programm_10" 11 "Programm_11" 12 "Programm_12" 13 "Programm_13" 14 "Programm_14" 15 "Programm_15" ;
VAL_ 902 CHA_Ziel_FahrPr_IVB 0 "keine_Funktion" 1 "Programm_1" 2 "Programm_2" 3 "Programm_3" 4 "Programm_4" 5 "Programm_5" 6 "Programm_6" 7 "Programm_7" 8 "Programm_8" 9 "Programm_9" 10 "Programm_10" 11 "Programm_11" 12 "Programm_12" 13 "Programm_13" 14 "Programm_14" 15 "Programm_15" ;
VAL_ 902 CHA_Kombi_Texte 0 "keine_Anzeige" 1 "Text_1" 2 "Text_2" 3 "Text_3" 4 "Text_4" 5 "Text_5" 6 "Text_6" 7 "Text_7" 8 "Text_8" 9 "Text_9" 10 "Text_10" 11 "Text_11" 12 "Text_12" 13 "Text_13" 14 "Text_14" 15 "Text_15" ;
VAL_ 902 CHA_Ziel_FahrPr_KL 0 "keine_Funktion" 1 "Programm_1" 2 "Programm_2" 3 "Programm_3" 4 "Programm_4" 5 "Programm_5" 6 "Programm_6" 7 "Programm_7" 8 "Programm_8" 9 "Programm_9" 10 "Programm_10" 11 "Programm_11" 12 "Programm_12" 13 "Programm_13" 14 "Programm_14" 15 "Programm_15" ;
VAL_ 902 CHA_Ziel_FahrPr_HSP 0 "keine_Funktion" 1 "Programm_1" 2 "Programm_2" 3 "Programm_3" 4 "Programm_4" 5 "Programm_5" 6 "Programm_6" 7 "Programm_7" 8 "Programm_8" 9 "Programm_9" 10 "Programm_10" 11 "Programm_11" 12 "Programm_12" 13 "Programm_13" 14 "Programm_14" 15 "Programm_15" ;
VAL_ 902 CHA_Drehschalter_Istmodus 0 "keine_Schalterstellung" 1 "Schalterstellung_1" 2 "Schalterstellung_2" 3 "Schalterstellung_3" 4 "Schalterstellung_4" 5 "Schalterstellung_5" 6 "Schalterstellung_6" 7 "Schalterstellung_7" 8 "Schalterstellung_8" 9 "Schalterstellung_9" 10 "Schalterstellung_10" 11 "Schalterstellung_11" 12 "Schalterstellung_12" 13 "Schalterstellung_13" 14 "Schalterstellung_14" 15 "Schalterstellung_15" ;
VAL_ 902 CHA_Ziel_FahrPr_RWB 0 "keine_Funktion" 1 "Programm_1" 2 "Programm_2" 3 "Programm_3" 4 "Programm_4" 5 "Programm_5" 6 "Programm_6" 7 "Programm_7" 8 "Programm_8" 9 "Programm_9" 10 "Programm_10" 11 "Programm_11" 12 "Programm_12" 13 "Programm_13" 14 "Programm_14" 15 "Programm_15" ;
VAL_ 902 CHA_Ziel_FahrPr_03_01 0 "keine_Funktion" 1 "Programm_1" 2 "Programm_2" 3 "Programm_3" 4 "Programm_4" 5 "Programm_5" 6 "Programm_6" 7 "Programm_7" 8 "Programm_8" 9 "Programm_9" 10 "Programm_10" 11 "Programm_11" 12 "Programm_12" 13 "Programm_13" 14 "Programm_14" 15 "Programm_15" ;
VAL_ 902 CHA_Ziel_FahrPr_03_02 0 "keine_Funktion" 1 "Programm_1" 2 "Programm_2" 3 "Programm_3" 4 "Programm_4" 5 "Programm_5" 6 "Programm_6" 7 "Programm_7" 8 "Programm_8" 9 "Programm_9" 10 "Programm_10" 11 "Programm_11" 12 "Programm_12" 13 "Programm_13" 14 "Programm_14" 15 "Programm_15" ;
VAL_ 902 CHA_Current_Mode 0 "keine_Funktion" 1 "Programm_1" 2 "Programm_2" 3 "Programm_3" 4 "Programm_4" 5 "Programm_5" 6 "Programm_6" 7 "Programm_7" 8 "Programm_8" 9 "Programm_9" 10 "Programm_10" 11 "Programm_11" 12 "Programm_12" 13 "Programm_13" 14 "Programm_14" 15 "Programm_15" ;
VAL_ 902 CHA_Charge_LED 0 "LED_aus" 1 "LED_ein" ;
VAL_ 902 CHA_Offroad_LED 0 "LED_aus" 1 "LED_ein" 2 "LED_blinken" 3 "Fehler" ;
VAL_ 902 CHA_Kombi_Texte_02 0 "Init" 1 "Text_1" 2 "Text_2" 3 "Text_3" 4 "Text_4" 5 "Text_5" 6 "Text_6" 7 "Text_7" 8 "Text_8" 9 "Text_9" 10 "Text_10" 11 "Text_11" 12 "Text_12" 13 "Text_13" 14 "Text_14" 15 "Text_15" ;
VAL_ 1000 CHA_Ziel_FahrPr_EBKV 0 "keine_Funktion" 1 "Programm_1" 2 "Programm_2" 3 "Programm_3" 4 "Programm_4" 5 "Programm_5" 6 "Programm_6" 7 "Programm_7" 8 "Programm_8" 9 "Programm_9" 10 "Programm_10" 11 "Programm_11" 12 "Programm_12" 13 "Programm_13" 14 "Programm_14" 15 "Programm_15" ;
VAL_ 1000 CHA_Ziel_FahrPr_IL 0 "keine_Funktion" 1 "Programm_1" 2 "Programm_2" 3 "Programm_3" 4 "Programm_4" 5 "Programm_5" 6 "Programm_6" 7 "Programm_7" 8 "Programm_8" 9 "Programm_9" 10 "Programm_10" 11 "Programm_11" 12 "Programm_12" 13 "Programm_13" 14 "Programm_14" 15 "Programm_15" ;
VAL_ 1000 CHA_Ziel_FahrPr_WarnBrems 0 "keine_Funktion" 1 "Programm_1" 2 "Programm_2" 3 "Programm_3" 4 "Programm_4" 5 "Programm_5" 6 "Programm_6" 7 "Programm_7" 8 "Programm_8" 9 "Programm_9" 10 "Programm_10" 11 "Programm_11" 12 "Programm_12" 13 "Programm_13" 14 "Programm_14" 15 "Programm_15" ;
VAL_ 1000 CHA_Fahrer_Umschaltung 0 "keine_oder_automatische_Umschaltung" 1 "manuelle_Umschaltung" ;
VAL_ 1000 CHA_Ziel_FahrPr_QS 0 "keine_Funktion" 1 "Programm_1" 2 "Programm_2" 3 "Programm_3" 4 "Programm_4" 5 "Programm_5" 6 "Programm_6" 7 "Programm_7" 8 "Programm_8" 9 "Programm_9" 10 "Programm_10" 11 "Programm_11" 12 "Programm_12" 13 "Programm_13" 14 "Programm_14" 15 "Programm_15" ;
VAL_ 1000 CHA_Ziel_FahrPr_SCU 0 "keine_Funktion" 1 "Programm_1" 2 "Programm_2" 3 "Programm_3" 4 "Programm_4" 5 "Programm_5" 6 "Programm_6" 7 "Programm_7" 8 "Programm_8" 9 "Programm_9" 10 "Programm_10" 11 "Programm_11" 12 "Programm_12" 13 "Programm_13" 14 "Programm_14" 15 "Programm_15" ;
VAL_ 1000 CHA_Ziel_FahrPr_HAL 0 "keine_Funktion" 1 "Programm_1" 2 "Programm_2" 3 "Programm_3" 4 "Programm_4" 5 "Programm_5" 6 "Programm_6" 7 "Programm_7" 8 "Programm_8" 9 "Programm_9" 10 "Programm_10" 11 "Programm_11" 12 "Programm_12" 13 "Programm_13" 14 "Programm_14" 15 "Programm_15" ;
VAL_ 1000 CHA_Ziel_FahrPr_NR 0 "keine_Funktion" 1 "Programm_1" 2 "Programm_2" 3 "Programm_3" 4 "Programm_4" 5 "Programm_5" 6 "Programm_6" 7 "Programm_7" 8 "Programm_8" 9 "Programm_9" 10 "Programm_10" 11 "Programm_11" 12 "Programm_12" 13 "Programm_13" 14 "Programm_14" 15 "Programm_15" ;
VAL_ 1000 CHA_Ziel_FahrPr_AV 0 "keine_Funktion" 1 "Programm_1" 2 "Programm_2" 3 "Programm_3" 4 "Programm_4" 5 "Programm_5" 6 "Programm_6" 7 "Programm_7" 8 "Programm_8" 9 "Programm_9" 10 "Programm_10" 11 "Programm_11" 12 "Programm_12" 13 "Programm_13" 14 "Programm_14" 15 "Programm_15" ;
VAL_ 1000 CHA_Ziel_FahrPr_MXB 0 "keine_Funktion" 1 "Programm_1" 2 "Programm_2" 3 "Programm_3" 4 "Programm_4" 5 "Programm_5" 6 "Programm_6" 7 "Programm_7" 8 "Programm_8" 9 "Programm_9" 10 "Programm_10" 11 "Programm_11" 12 "Programm_12" 13 "Programm_13" 14 "Programm_14" 15 "Programm_15" ;
VAL_ 1000 CHA_Ziel_FahrPr_AFR 0 "keine_Funktion" 1 "Programm_1" 2 "Programm_2" 3 "Programm_3" 4 "Programm_4" 5 "Programm_5" 6 "Programm_6" 7 "Programm_7" 8 "Programm_8" 9 "Programm_9" 10 "Programm_10" 11 "Programm_11" 12 "Programm_12" 13 "Programm_13" 14 "Programm_14" 15 "Programm_15" ;
VAL_ 1000 CHA_Ziel_FahrPr_HDC 0 "keine_Funktion" 1 "Programm_1" 2 "Programm_2" 3 "Programm_3" 4 "Programm_4" 5 "Programm_5" 6 "Programm_6" 7 "Programm_7" 8 "Programm_8" 9 "Programm_9" 10 "Programm_10" 11 "Programm_11" 12 "Programm_12" 13 "Programm_13" 14 "Programm_14" 15 "Programm_15" ;
VAL_ 1000 CHA_Ziel_FahrPr_EAR 0 "keine_Funktion" 1 "Programm_1" 2 "Programm_2" 3 "Programm_3" 4 "Programm_4" 5 "Programm_5" 6 "Programm_6" 7 "Programm_7" 8 "Programm_8" 9 "Programm_9" 10 "Programm_10" 11 "Programm_11" 12 "Programm_12" 13 "Programm_13" 14 "Programm_14" 15 "Programm_15" ;
VAL_ 1000 CHA_Ziel_FahrPr_FCWO 0 "keine_Funktion" 1 "Programm_1" 2 "Programm_2" 3 "Programm_3" 4 "Programm_4" 5 "Programm_5" 6 "Programm_6" 7 "Programm_7" 8 "Programm_8" 9 "Programm_9" 10 "Programm_10" 11 "Programm_11" 12 "Programm_12" 13 "Programm_13" 14 "Programm_14" 15 "Programm_15" ;
VAL_ 1000 CHA_Ziel_FahrPr_FCWP 0 "keine_Funktion" 1 "Programm_1" 2 "Programm_2" 3 "Programm_3" 4 "Programm_4" 5 "Programm_5" 6 "Programm_6" 7 "Programm_7" 8 "Programm_8" 9 "Programm_9" 10 "Programm_10" 11 "Programm_11" 12 "Programm_12" 13 "Programm_13" 14 "Programm_14" 15 "Programm_15" ;
VAL_ 1022 CHA_Fahrer_Umschaltung 0 "keine_oder_automatische_Umschaltung" 1 "manuelle_Umschaltung" ;
VAL_ 1022 CHA_Fahrer_Umschaltung_BMA 0 "keine_oder_autom_Umschaltung" 1 "manuelle_Umschaltung" ;
VAL_ 1022 CHA_Ziel_FahrPr_Reku_ZwGas 0 "kein_Funktion" 1 "Programm_1" 2 "Programm_2" 3 "Programm_3" 4 "Programm_4" 5 "Programm_5" 6 "Programm_6" 7 "Programm_7" 8 "Programm_8" 9 "Programm_9" 10 "Programm_10" 11 "Programm_11" 12 "Programm_12" 13 "Programm_13" 14 "Programm_14" 15 "Programm_15" ;
VAL_ 1022 CHA_Ziel_FahrPr_MO_Freilauf 0 "keine_Funktion" 1 "Programm_1" 2 "Programm_2" 3 "Programm_3" 4 "Programm_4" 5 "Programm_5" 6 "Programm_6" 7 "Programm_7" 8 "Programm_8" 9 "Programm_9" 10 "Programm_10" 11 "Programm_11" 12 "Programm_12" 13 "Programm_13" 14 "Programm_14" 15 "Programm_15" ;
VAL_ 1022 CHA_Ziel_FahrPr_BMS 0 "keine_Funktion" 1 "Programm_1" 2 "Programm_2" 3 "Programm_3" 4 "Programm_4" 5 "Programm_5" 6 "Programm_6" 7 "Programm_7" 8 "Programm_8" 9 "Programm_9" 10 "Programm_10" 11 "Programm_11" 12 "Programm_12" 13 "Programm_13" 14 "Programm_14" 15 "Programm_15" ;
VAL_ 1022 CHA_Current_Mode_BMA 0 "keine_Funktion" 1 "Programm_1" 2 "Programm_2" 3 "Programm_3" 4 "Programm_4" 5 "Programm_5" 6 "Programm_6" 7 "Programm_7" 8 "Programm_8" 9 "Programm_9" 10 "Programm_10" 11 "Programm_11" 12 "Programm_12" 13 "Programm_13" 14 "Programm_14" 15 "Programm_15" ;
VAL_ 1022 CHA_Ziel_FahrPr_PDC 0 "keine_Funktion" 1 "Programm_1" 2 "Programm_2" 3 "Programm_3" 4 "Programm_4" 5 "Programm_5" 6 "Programm_6" 7 "Programm_7" 8 "Programm_8" 9 "Programm_9" 10 "Programm_10" 11 "Programm_11" 12 "Programm_12" 13 "Programm_13" 14 "Programm_14" 15 "Programm_15" ;
VAL_ 1022 CHA_Ziel_FahrPr_HHC 0 "keine_Funktion" 1 "Programm_1" 2 "Programm_2" 3 "Programm_3" 4 "Programm_4" 5 "Programm_5" 6 "Programm_6" 7 "Programm_7" 8 "Programm_8" 9 "Programm_9" 10 "Programm_10" 11 "Programm_11" 12 "Programm_12" 13 "Programm_13" 14 "Programm_14" 15 "Programm_15" ;
VAL_ 1022 CHA_Ziel_FahrPr_EDS 0 "keine_Funktion" 1 "Programm_1" 2 "Programm_2" 3 "Programm_3" 4 "Programm_4" 5 "Programm_5" 6 "Programm_6" 7 "Programm_7" 8 "Programm_8" 9 "Programm_9" 10 "Programm_10" 11 "Programm_11" 12 "Programm_12" 13 "Programm_13" 14 "Programm_14" 15 "Programm_15" ;
VAL_ 1022 CHA_Ziel_FahrPr_PACC 0 "keine_Funktion" 1 "Programm_1" 2 "Programm_2" 3 "Programm_3" 4 "Programm_4" 5 "Programm_5" 6 "Programm_6" 7 "Programm_7" 8 "Programm_8" 9 "Programm_9" 10 "Programm_10" 11 "Programm_11" 12 "Programm_12" 13 "Programm_13" 14 "Programm_14" 15 "Programm_15" ;
VAL_ 1022 CHA_Ziel_FahrPr_AGK 0 "keine_Funktion" 1 "Programm_1" 2 "Programm_2" 3 "Programm_3" 4 "Programm_4" 5 "Programm_5" 6 "Programm_6" 7 "Programm_7" 8 "Programm_8" 9 "Programm_9" 10 "Programm_10" 11 "Programm_11" 12 "Programm_12" 13 "Programm_13" 14 "Programm_14" 15 "Programm_15" ;
VAL_ 615 DR_Systemstatus 0 "Init oder kein Wert verfuegbar" 1 "Komfortabel" 2 "Normal" 3 "Sport 1" 4 "Sport 2" 5 "nicht funktionsfähig" 6 "Funktionseinschränkung aktiv" 7 "Notfahrfunktion" ;
VAL_ 615 DR_ESP_Zuschaltung 0 "keine_ESP_Beeinflussung" 1 "ESP_Zwangszuschaltung_gefordert" ;
VAL_ 615 DR_DynAGL_Anf_Entkopplung 0 "inaktiv" 1 "aktiv" ;
VAL_ 615 DR_DynAGL_Anf_im_Leerlauf 0 "inaktiv" 1 "aktiv" ;
VAL_ 615 EFP_Niveauzustand_Lift 0 "Init" 1 "gesenkt" 2 "heben" 3 "gehoben" 4 "senken" 5 "Fehler" ;
VAL_ 615 EFP_Verfuegbarkeit_Lift 0 "Init" 1 "verfuegbar" 2 "temporaer_nicht_verfuegbar" 3 "Fehler_Service_notwendig" 4 "Temperaturschutz" 5 "Fehler_Niveauplausibilisierung" ;
VAL_ 615 DR_Charisma_FahrPr 0 "keine_Funktion" 1 "Programm_1" 2 "Programm_2" 3 "Programm_3" 4 "Programm_4" 5 "Programm_5" 6 "Programm_6" 7 "Programm_7" 8 "Programm_8" 9 "Programm_9" 10 "Programm_10" 11 "Programm_11" 12 "Programm_12" 13 "Programm_13" 14 "Programm_14" 15 "Programm_15" ;
VAL_ 615 DR_Charisma_Status 0 "Init" 1 "verfuegbar" 2 "nicht_verfuegbar" 3 "asynchron_durch_Fahrerwunsch" ;
VAL_ 615 EFP_Vorlaufzeit_Lift 6 "Init" 7 "Fehler" ;
VAL_ 615 EFP_LstgBegr 1022 "Init" 1023 "Fehler" ;
VAL_ 1714 DGN_Verlernzaehler 255 "ungültiger Zählerstand oder kein gültiger Fahrzyklus" ;
VAL_ 1714 KBI_Kilometerstand 1048574 "Init" 1048575 "Fehler" ;
VAL_ 1714 UH_Monat 0 "Init" 14 "Relatives_Datum" 15 "Fehler" ;
VAL_ 1714 UH_Tag 0 "Init" ;
VAL_ 1714 Kombi_02_alt 0 "aktuell" 1 "veraltet" ;
VAL_ 1714 Uhrzeit_01_alt 0 "aktuell" 1 "veraltet" ;
VAL_ 1520 DI_KL_58xd 254 "Init" 255 "Fehler" ;
VAL_ 1520 DI_KL_58xs 126 "Init" 127 "Fehler" ;
VAL_ 1520 DI_KL_58xt 126 "Init" 127 "Fehler" ;
VAL_ 1520 BCM1_Stellgroesse_Kl_58s 125 "Nicht_verbaut" 126 "Init" 127 "Fehler" ;
VAL_ 420 EA_Parken_beibehalten_HMS 0 "Parken_nicht_beibehalten" 1 "Parken_beibehalten" 2 "Init" 3 "Fehler" ;
VAL_ 420 EA_Warnruckprofil 0 "keine_Ruckanforderung" 1 "Profil_1" 2 "Profil_2" 3 "Profil_3" 4 "Profil_4" 5 "Profil_5" 6 "Profil_6" 7 "Profil_7" ;
VAL_ 420 EA_eCall_Anf 0 "Keine_Anforderung" 1 "Ausloesen_eCall" ;
VAL_ 420 EA_Funktionsstatus 0 "EA_INIT" 1 "EA_OFF" 2 "EA_STANDBY" 3 "EA_PHASE0_AKTIV" 4 "EA_PHASE1_AKTIV" 5 "EA_PHASE2_AKTIV" 6 "EA_PHASE3_AKTIV" 7 "EA_REVERSIBLER_FEHLER" 8 "EA_IRREVERSIBLER_FEHLER" ;
VAL_ 420 EA_Gurtstraffer_Anf 0 "Keine_Anforderung" 1 "Haptik_1" 2 "Haptik_2" 3 "Haptik_3" ;
VAL_ 420 EA_Anforderung_HMS 0 "keine_Anforderung" 1 "halten" 2 "parken" 3 "halten_Standby" 4 "anfahren" 5 "Loesen_ueber_Rampe" 6 "Parken_mit_P" ;
VAL_ 420 EA_Sollbeschleunigung 2046 "Neutralwert" 2047 "Fehler" ;
VAL_ 496 EA_Texte 0 "keine_Anzeige" 1 "Nothalteassistent_fehlende_Fahreraktivitaet" 2 "Nothalteassistent_aktiv_Fahrzeugfuehrung_uebernehmen" 3 "Nothalteassistent_automatischer_Nothalt_wird_durchgefuehrt" 4 "Nothalteassistent_automatischer_Nothalt_durchgefuehrt" 5 "Nothalteassistent_Verbindung_zum_Notruf_wird_aufgebaut" 6 "Nothalteassistent_deaktiviert" 7 "Nothalteassistent_Eingriff_abgebrochen" 8 "Nothalteassistent_fehlende_Fahreraktivitaet_2" 9 "Sekundenschlaf_erkannt" 10 "LaneAssist_Lenkung_uebernehmen" 11 "ACA_Fahrzeugfuehrung_uebernehmen" 12 "EA_Fahr_Standstreifenwechsel" 14 "Nothalteassistent_nicht_verfuegbar_reversibel" 15 "Nothalteassistent_Stoerung_irreversibel" ;
VAL_ 496 ACF_Lampe_Hands_Off 0 "keine_Anzeige" 1 "Hands_Off_erkannt" ;
VAL_ 496 EA_Infotainment_Anf 0 "Init" 1 "Keine_Absenkung" 2 "Absenkung" 3 "Mute" ;
VAL_ 496 EA_Tueren_Anf 0 "Keine_Anforderung" 1 "Tueren_entriegeln" ;
VAL_ 496 EA_Innenraumlicht_Anf 0 "Innenraumbeleuchtung_ausschalten" 1 "Innenraumbeleuchtung_einschalten" ;
VAL_ 496 zFAS_Warnblinken 0 "Aus" 1 "Statisch" 2 "Taster" 3 "Statisch_ohne_WBT" ;
VAL_ 496 STP_Primaeranz 0 "keine_Anzeige" 1 "Verfuegbar" 2 "Aktiv" 3 "Uebernahme" 4 "Aktiv_Warnung" 5 "Nicht_Verfuegbar" ;
VAL_ 496 EA_Bremslichtblinken 0 "kein_Blinken" 1 "Anforderung_Bremslichtblinken" ;
VAL_ 496 EA_Blinken 0 "Kein_Blinken" 1 "Wechselblinken_links" 2 "Wechselblinken_rechts" 3 "Warnblinken" 4 "Warnblinken_Taster" ;
VAL_ 496 EA_Status_HMI 0 "Keine_Anzeige" 1 "Aktiv_quer_laengs" 2 "Aktiv_laengs" ;
VAL_ 2527679980 eCall_Statuslicht_Farbe2 0 "Aus" 1 "Blinken_1" 2 "Blinken_2" 3 "An" ;
VAL_ 2527679980 eCall_Statuslicht_Farbe1 0 "Aus" 1 "Blinken_1" 2 "Blinken_2" 3 "An" ;
VAL_ 2527679980 bCall_active 0 "bcall_inactive" 1 "bcall_active" ;
VAL_ 2527679980 eCall_Funktionsstatus 0 "kein_Fehler" 1 "Fkt_eingeschraenkt" 2 "Fkt_eingeschraenkt_service" 3 "Fkt_nicht_verfuegbar" 4 "Fkt_Service" 5 "Fkt_deaktiviert" 6 "Fkt_aktiviert" 7 "init" ;
VAL_ 2527679980 eCall_Subscription 0 "Init" 1 "unsubscribed" 2 "subscribed" ;
VAL_ 2527679980 eCall_Funktionsstatus_02 0 "kein_Fehler" 1 "Manueller_Notruf_aktiv" 2 "Automatischer_Notruf_aktiv" 7 "Init" ;
VAL_ 2527679980 eCall_Mute_Anf 0 "kein_mute" 1 "mute" ;
VAL_ 1603 KBI_Einheit_Datum 0 "Tag/Monat/Jahr" 1 "Monat/Tag/Jahr" 2 "Jahr/Monat/Tag" 3 "reserviert" ;
VAL_ 1603 KBI_Einheit_Druck 0 "Druckangabe in bar" 1 "Druckangabe in psi" 2 "Druckangabe in kPa" 3 "tbd." ;
VAL_ 1603 KBI_Einheit_Streckenanz 0 "Kilometer" 1 "Meilen" ;
VAL_ 1603 KBI_MFA_v_Einheit_02 0 "kmh" 1 "mph" ;
VAL_ 1603 KBI_Einheit_Temp 0 "Grad Celsius °C" 1 "Grad Fahrenheit °F" ;
VAL_ 1603 KBI_Einheit_Uhrzeit 0 "24h" 1 " 12h AM/PM" ;
VAL_ 1603 KBI_Einheit_Verbrauch 0 "mpg UK" 1 "mpg USA" 2 "Liter/100km" 3 "km/Liter" ;
VAL_ 1603 KBI_Einheit_Volumen 0 "Liter" 1 "Gallonen UK" 2 "Gallonen USA" 3 "reserviert" ;
VAL_ 1603 KBI_Einheit_Verbrauch_elektr 0 "kWh_pro_100km" 1 "km_pro_kWh" 2 "kWh_pro_100mls" 3 "mls_pro_kWh" 4 "MPGe" ;
VAL_ 1603 KBI_Einheit_Verbrauch_Gas 0 "kg_per_100km" 1 "km_per_kg" 2 "m3_per_100km" 3 "km_per_m3" 4 "miles_per_lbs" 5 "miles_per_yard3" 6 "miles_per_kg" 7 "miles_per_m3" 8 "miles_per_gallon_equivalent_US" ;
VAL_ 1603 KBI_Einheit_Masse 0 "kg" 1 "lbs" 2 "reserviert" ;
VAL_ 260 EPB_QBit_Pedalweg_Kuppl 0 "gültiger Wert" 1 "Ersatz-, Init- oder Fehlerwert" ;
VAL_ 260 EPB_Freig_Verzoeg_Anf 0 "nicht freigegeben" 1 "freigegeben" ;
VAL_ 260 EPB_Pedalweg_Kuppl 0 "Init" 255 "Fehler" ;
VAL_ 260 EPB_DAA_Randbed_erf 0 "Randbed_nicht_erfuellt" 1 "Randbed_erfuellt" ;
VAL_ 260 EPB_Fehlerstatus_02 0 "kein_Fehler" 1 "Fehler_ausserhalb_apply_release" 2 "Fehler_einseitig_apply_release" 3 "Fehler_beidseitig_apply_release" ;
VAL_ 260 EPB_Schalterposition 0 "keine Fahreranforderung" 1 "Fahreranforderung Öffnen" 2 "Fahreranforderung Schließen" 3 "Fehler" ;
VAL_ 260 EPB_QBit_Schalterpos 0 "gültiger Wert (volle Funktion)" 1 " Ersatz-, Init- oder Fehlerwert (Schalter ausser Funktion)" ;
VAL_ 260 EPB_Spannkraft 30 "Init" 31 "Fehler" ;
VAL_ 260 EPB_Status_02 0 "offen" 1 "geschlossen_Parken" 2 "teilgespannt_Halten" 3 "im_Lauf_oeffnen" 4 "im_Lauf_schliessen" 5 "tbd" 6 "Init" 7 "unbekannt" ;
